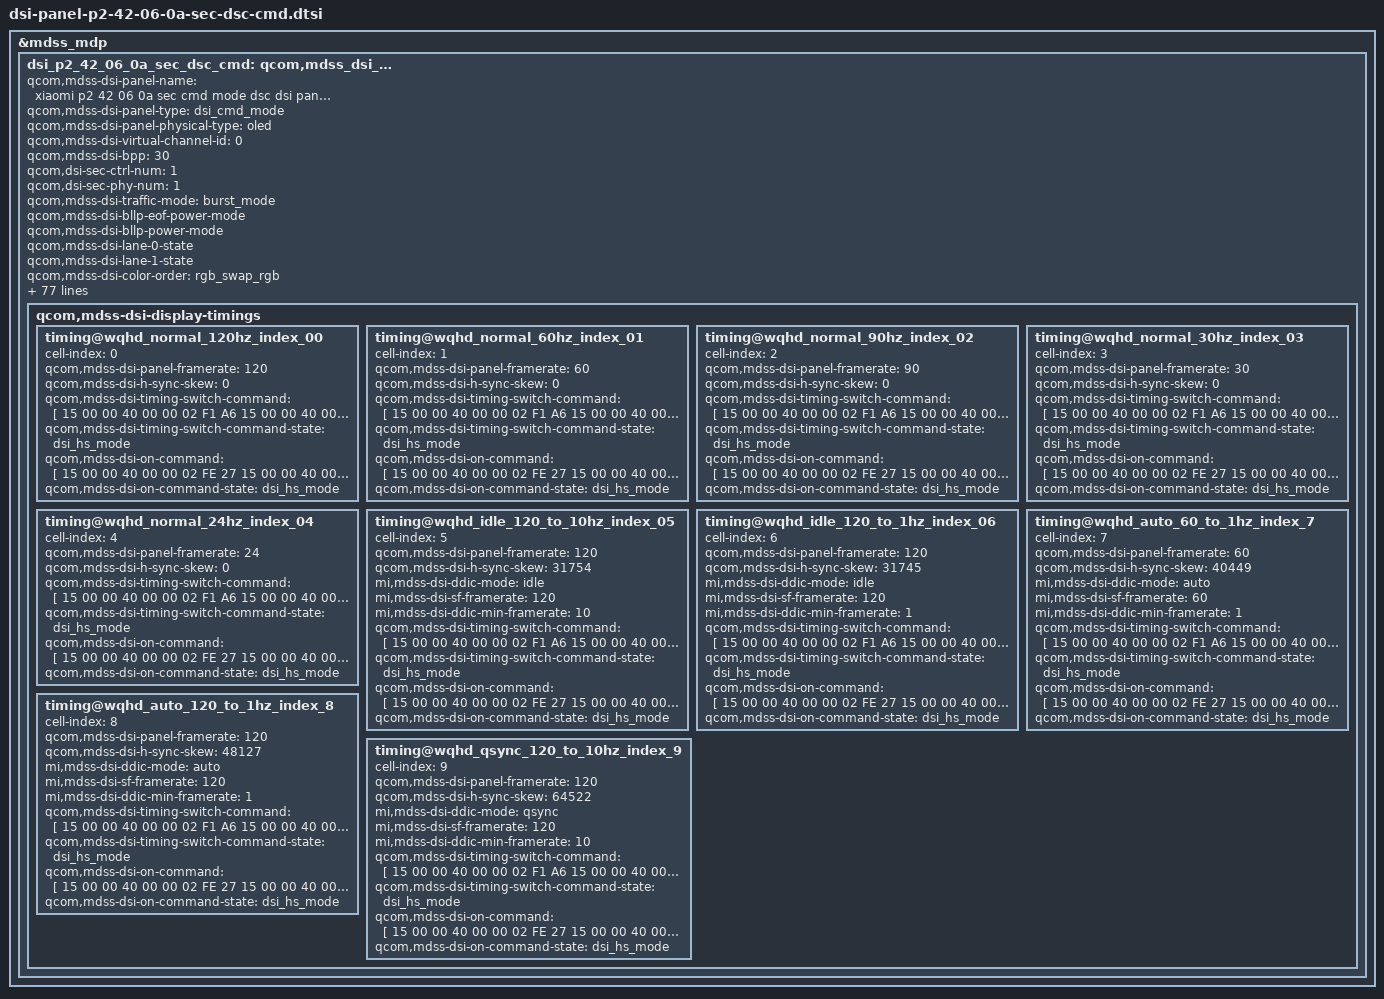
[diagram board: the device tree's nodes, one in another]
&mdss_mdp {
	dsi_p2_42_06_0a_sec_dsc_cmd: qcom,mdss_dsi_p2_42_06_0a_sec_dsc_cmd {
		qcom,mdss-dsi-panel-name = "xiaomi p2 42 06 0a sec cmd mode dsc dsi panel";
		qcom,mdss-dsi-panel-type = "dsi_cmd_mode";
		qcom,mdss-dsi-panel-physical-type = "oled";
		qcom,mdss-dsi-virtual-channel-id = <0>;
		qcom,mdss-dsi-bpp = <30>;
		qcom,dsi-sec-ctrl-num = <1>;
		qcom,dsi-sec-phy-num = <1>;
		qcom,mdss-dsi-traffic-mode = "burst_mode";
		qcom,mdss-dsi-bllp-eof-power-mode;
		qcom,mdss-dsi-bllp-power-mode;
		qcom,mdss-dsi-lane-0-state;
		qcom,mdss-dsi-lane-1-state;
		qcom,mdss-dsi-color-order = "rgb_swap_rgb";
		qcom,mdss-dsi-dma-trigger = "trigger_sw";
		qcom,mdss-dsi-mdp-trigger = "none";
		qcom,mdss-dsi-reset-sequence =<0 1>, <1 33>;
		qcom,mdss-pan-physical-width-dimension = <378>;
		qcom,mdss-pan-physical-height-dimension = <619>;
		qcom,mdss-dsi-te-pin-select = <1>;
		qcom,mdss-dsi-wr-mem-start = <0x2c>;
		qcom,mdss-dsi-wr-mem-continue = <0x3c>;
		qcom,mdss-dsi-te-dcs-command = <1>;
		qcom,mdss-dsi-tx-eot-append;
		//qcom,mdss-dsi-lp11-init;
		qcom,mdss-dsi-bl-inverted-dbv;
		qcom,bl-update-flag = "delay_until_first_frame";
		qcom,mdss-dsi-panel-hdr-enabled;
		qcom,mdss-dsi-panel-hdr-color-primaries = <14500 15500 32000
			17000 15500 30000 8000 3000>;
		qcom,mdss-dsi-panel-peak-brightness = <32000000>;
		qcom,mdss-dsi-panel-blackness-level = <3230>;
		qcom,mdss-dsi-dma-schedule-line = <1>;
		qcom,mdss-dsi-dma-schedule-window = <50>;

		qcom,mdss-disable-cesta-hw-sleep;

		qcom,mdss-dsi-display-timings {
			timing@wqhd_normal_120hz_index_00 {
				#include "dsi-panel-p2-42-06-0a-sec-dsc-cmd-common.dtsi"
				cell-index = <0>;
				qcom,mdss-dsi-panel-framerate = <120>;
				qcom,mdss-dsi-h-sync-skew = <0>;
				qcom,mdss-dsi-timing-switch-command = [
					15 00 00 40 00 00 02 F1 A6
					15 00 00 40 00 00 02 FE 00
					15 00 00 40 00 00 02 8A 17 // auto 120 - 1
					15 00 00 40 00 00 02 FE 98
					15 00 00 40 00 00 02 E3 08
					15 00 00 40 00 00 02 CB 01
					15 00 00 40 00 00 02 FE 44
					15 00 00 40 00 00 02 77 E8
					15 00 00 40 00 00 02 FE 00
					15 00 00 00 00 00 02 FB AA
				];
				qcom,mdss-dsi-timing-switch-command-state = "dsi_hs_mode";
				qcom,mdss-dsi-on-command = [
					/* round corner */
					15 00 00 40 00 00 02 FE 27
					15 00 00 40 00 00 02 BF 01
					15 00 00 40 00 00 02 F6 01
					15 00 00 40 00 00 02 FE 27
					15 00 00 40 00 00 02 0F F2
					15 00 00 40 00 00 02 13 2C
					15 00 00 40 00 00 02 19 86
					15 00 00 40 00 00 02 1A 14
					15 00 00 40 00 00 02 1B 40
					15 00 00 40 00 00 02 26 63
					15 00 00 40 00 00 02 27 63
					15 00 00 40 00 00 02 29 64
					15 00 00 40 00 00 02 2A 78
					15 00 00 40 00 00 02 2F 00
					15 00 00 40 00 00 02 30 6F
					15 00 00 40 00 00 02 31 95
					15 00 00 40 00 00 02 32 00
					15 00 00 40 00 00 02 33 96
					15 00 00 40 00 00 02 34 78
					15 00 00 40 00 00 02 35 00
					15 00 00 40 00 00 02 36 04
					15 00 00 40 00 00 02 37 07
					15 00 00 40 00 00 02 38 95
					15 00 00 40 00 00 02 39 6F
					15 00 00 40 00 00 02 3A 00
					15 00 00 40 00 00 02 3B 96
					15 00 00 40 00 00 02 3F 78
					15 00 00 40 00 00 02 40 00
					15 00 00 40 00 00 02 41 04
					15 00 00 40 00 00 02 42 07
					15 00 00 40 00 00 02 77 86
					15 00 00 40 00 00 02 78 A0
					15 00 00 40 00 00 02 80 64
					15 00 00 40 00 00 02 81 64
					15 00 00 40 00 00 02 83 63
					15 00 00 40 00 00 02 90 86
					15 00 00 40 00 00 02 91 A0
					15 00 00 40 00 00 02 B6 00
					15 00 00 40 00 00 02 B7 44
					15 00 00 40 00 00 02 C1 24
					15 00 00 40 00 00 02 C3 24
					15 00 00 40 00 00 02 FE 28
					15 00 00 40 00 00 02 37 18
					15 00 00 40 00 00 02 58 18
					15 00 00 40 00 00 02 FE 90
					15 00 00 40 00 00 02 08 00
					15 00 00 00 00 00 02 09 00
					/* init code */
					15 00 00 40 00 00 02 FE D2
					15 00 00 40 00 00 02 97 00
					15 00 00 40 00 00 02 FE 00
					15 00 00 40 00 00 02 FA 01
					15 00 00 40 00 00 02 FE 00
					15 00 00 40 00 00 02 2F 04
					15 00 00 40 00 00 02 8A 10
					15 00 00 40 00 00 02 FE 00
					39 00 00 40 00 00 05 2A 00 00 02 53
					39 00 00 40 00 00 05 2B 00 00 03 CF
					15 00 00 40 00 00 02 35 00
					39 00 00 00 00 00 03 51 00 00
					/* frame skip */
					15 00 00 40 00 00 02 FE 44
					15 00 00 40 00 00 02 00 88
					15 00 00 40 00 00 02 AA 00
					15 00 00 40 00 00 02 01 08
					15 00 00 40 00 00 02 02 01
					15 00 00 40 00 00 02 03 01
					15 00 00 40 00 00 02 04 32
					15 00 00 40 00 00 02 05 01
					15 00 00 40 00 00 02 06 00
					15 00 00 40 00 00 02 07 00
					15 00 00 40 00 00 02 08 00
					15 00 00 40 00 00 02 09 00
					15 00 00 40 00 00 02 0A 00
					15 00 00 40 00 00 02 0B 00
					15 00 00 40 00 00 02 0C 00
					15 00 00 40 00 00 02 0D 11
					15 00 00 40 00 00 02 0E 11
					15 00 00 40 00 00 02 0F 11
					15 00 00 40 00 00 02 10 11
					15 00 00 40 00 00 02 15 01
					15 00 00 40 00 00 02 16 03
					15 00 00 40 00 00 02 17 00
					15 00 00 40 00 00 02 18 00
					15 00 00 40 00 00 02 19 00
					15 00 00 40 00 00 02 1A 00
					15 00 00 40 00 00 02 1B 00
					15 00 00 40 00 00 02 1C 00
					15 00 00 40 00 00 02 1D 11
					15 00 00 40 00 00 02 1E 11
					15 00 00 40 00 00 02 1F 11
					15 00 00 40 00 00 02 20 11
					15 00 00 40 00 00 02 25 01
					15 00 00 40 00 00 02 26 03
					15 00 00 40 00 00 02 27 0B
					15 00 00 40 00 00 02 28 0B
					15 00 00 40 00 00 02 29 00
					15 00 00 40 00 00 02 2A 00
					15 00 00 40 00 00 02 2B 00
					15 00 00 40 00 00 02 2D 00
					15 00 00 40 00 00 02 2F 11
					15 00 00 40 00 00 02 30 FF
					15 00 00 40 00 00 02 31 11
					15 00 00 40 00 00 02 32 11
					15 00 00 40 00 00 02 37 01
					15 00 00 40 00 00 02 38 03
					15 00 00 40 00 00 02 39 04
					15 00 00 40 00 00 02 3A 00
					15 00 00 40 00 00 02 3B 00
					15 00 00 40 00 00 02 3D 00
					15 00 00 40 00 00 02 3F 00
					15 00 00 40 00 00 02 40 00
					15 00 00 40 00 00 02 41 11
					15 00 00 40 00 00 02 42 11
					15 00 00 40 00 00 02 43 11
					15 00 00 40 00 00 02 44 11
					15 00 00 40 00 00 02 69 00
					15 00 00 40 00 00 02 6A 00
					15 00 00 40 00 00 02 6B 00
					15 00 00 40 00 00 02 6C 00
					15 00 00 40 00 00 02 6D 00
					15 00 00 40 00 00 02 6E 00
					15 00 00 40 00 00 02 6F 00
					15 00 00 40 00 00 02 70 00
					15 00 00 40 00 00 02 80 42
					15 00 00 40 00 00 02 81 03
					15 00 00 40 00 00 02 82 0B
					15 00 00 40 00 00 02 83 0B
					15 00 00 40 00 00 02 84 00
					15 00 00 40 00 00 02 85 00
					15 00 00 40 00 00 02 86 00
					15 00 00 40 00 00 02 87 00
					15 00 00 40 00 00 02 88 00
					15 00 00 40 00 00 02 89 00
					15 00 00 40 00 00 02 8A 00
					15 00 00 40 00 00 02 8B 1F
					15 00 00 40 00 00 02 8C F1
					15 00 00 40 00 00 02 8D 11
					15 00 00 40 00 00 02 8E 11
					15 00 00 40 00 00 02 49 00
					15 00 00 40 00 00 02 4A 00
					15 00 00 40 00 00 02 4B 04
					15 00 00 40 00 00 02 4C 00
					15 00 00 40 00 00 02 4D 00
					15 00 00 40 00 00 02 4E 01
					15 00 00 40 00 00 02 4F 03
					15 00 00 40 00 00 02 50 04
					15 00 00 40 00 00 02 51 0B
					15 00 00 40 00 00 02 52 77
					15 00 00 40 00 00 02 53 EF
					15 00 00 40 00 00 02 54 77
					15 00 00 40 00 00 02 55 77
					15 00 00 40 00 00 02 56 0B
					15 00 00 40 00 00 02 58 59
					15 00 00 40 00 00 02 59 00
					15 00 00 40 00 00 02 5A 00
					15 00 00 40 00 00 02 5B 00
					15 00 00 40 00 00 02 5C 00
					15 00 00 40 00 00 02 5D 00
					15 00 00 40 00 00 02 98 00
					15 00 00 40 00 00 02 99 00
					15 00 00 40 00 00 02 9A 00
					15 00 00 40 00 00 02 9B 00
					15 00 00 40 00 00 02 9C 00
					15 00 00 40 00 00 02 9D 00
					15 00 00 40 00 00 02 9E 00
					15 00 00 40 00 00 02 9F 00
					15 00 00 40 00 00 02 A0 00
					15 00 00 40 00 00 02 A2 00
					15 00 00 40 00 00 02 A3 00
					15 00 00 40 00 00 02 A4 00
					15 00 00 40 00 00 02 A5 00
					15 00 00 40 00 00 02 A6 00
					15 00 00 40 00 00 02 A7 00
					15 00 00 40 00 00 02 A9 00
					15 00 00 40 00 00 02 5E 00
					15 00 00 40 00 00 02 5F 01
					15 00 00 40 00 00 02 60 12
					15 00 00 40 00 00 02 61 32
					15 00 00 40 00 00 02 62 44
					15 00 00 40 00 00 02 63 40
					15 00 00 40 00 00 02 64 00
					15 00 00 40 00 00 02 65 00
					15 00 00 40 00 00 02 76 C0
					15 00 00 40 00 00 02 77 E8
					15 00 00 40 00 00 02 FE 43
					15 00 00 40 00 00 02 64 1B
					15 00 00 40 00 00 02 63 05
					15 00 00 40 00 00 02 66 06
					15 00 00 40 00 00 02 67 22
					15 00 00 40 00 00 02 68 22
					15 00 00 40 00 00 02 69 B3
					15 00 00 40 00 00 02 6A 33
					15 00 00 40 00 00 02 6B 0B
					15 00 00 40 00 00 02 6C 16
					15 00 00 40 00 00 02 6D 21
					15 00 00 40 00 00 02 6F 37
					15 00 00 40 00 00 02 70 42
					15 00 00 40 00 00 02 71 4D
					15 00 00 40 00 00 02 72 58
					15 00 00 40 00 00 02 73 0B
					15 00 00 40 00 00 02 74 16
					15 00 00 40 00 00 02 75 21
					15 00 00 40 00 00 02 76 2C
					15 00 00 40 00 00 02 77 37
					15 00 00 40 00 00 02 78 42
					15 00 00 40 00 00 02 79 4D
					15 00 00 40 00 00 02 7A 58
					15 00 00 40 00 00 02 7B 0B
					15 00 00 40 00 00 02 7C 16
					15 00 00 40 00 00 02 7D 21
					15 00 00 40 00 00 02 7E 2C
					15 00 00 40 00 00 02 7F 37
					15 00 00 40 00 00 02 80 42
					15 00 00 40 00 00 02 81 4D
					15 00 00 40 00 00 02 82 58
					15 00 00 40 00 00 02 83 0B
					15 00 00 40 00 00 02 84 16
					15 00 00 40 00 00 02 85 21
					15 00 00 40 00 00 02 86 2C
					15 00 00 40 00 00 02 87 37
					15 00 00 40 00 00 02 88 42
					15 00 00 40 00 00 02 89 4D
					15 00 00 40 00 00 02 8A 58
					15 00 00 40 00 00 02 8B 58
					15 00 00 40 00 00 02 8C 4D
					15 00 00 40 00 00 02 8D 42
					15 00 00 40 00 00 02 8E 37
					15 00 00 40 00 00 02 8F 2C
					15 00 00 40 00 00 02 90 21
					15 00 00 40 00 00 02 91 16
					15 00 00 40 00 00 02 92 0B
					15 00 00 40 00 00 02 93 58
					15 00 00 40 00 00 02 94 4D
					15 00 00 40 00 00 02 95 42
					15 00 00 40 00 00 02 96 37
					15 00 00 40 00 00 02 97 2C
					15 00 00 40 00 00 02 98 21
					15 00 00 40 00 00 02 99 16
					15 00 00 40 00 00 02 9A 0B
					15 00 00 40 00 00 02 9B 58
					15 00 00 40 00 00 02 9C 4D
					15 00 00 40 00 00 02 9D 42
					15 00 00 40 00 00 02 9E 37
					15 00 00 40 00 00 02 9F 2C
					15 00 00 40 00 00 02 A0 21
					15 00 00 40 00 00 02 A2 16
					15 00 00 40 00 00 02 A3 0B
					15 00 00 40 00 00 02 A4 58
					15 00 00 40 00 00 02 A5 4D
					15 00 00 40 00 00 02 A6 42
					15 00 00 40 00 00 02 A7 37
					15 00 00 40 00 00 02 A9 2C
					15 00 00 40 00 00 02 AA 21
					15 00 00 40 00 00 02 AB 16
					15 00 00 40 00 00 02 AC 0B
					15 00 00 40 00 00 02 AD 16
					15 00 00 40 00 00 02 AE 2C
					15 00 00 40 00 00 02 AF 16
					15 00 00 40 00 00 02 B0 2C
					15 00 00 40 00 00 02 B1 16
					15 00 00 40 00 00 02 B2 2C
					15 00 00 40 00 00 02 B3 16
					15 00 00 40 00 00 02 B4 2C
					15 00 00 40 00 00 02 B5 16
					15 00 00 40 00 00 02 B6 2C
					15 00 00 40 00 00 02 B7 16
					15 00 00 40 00 00 02 B8 2C
					15 00 00 40 00 00 02 B9 16
					15 00 00 40 00 00 02 BA 2C
					15 00 00 40 00 00 02 BB 16
					15 00 00 40 00 00 02 BC 2C
					15 00 00 40 00 00 02 BD 16
					15 00 00 40 00 00 02 BE 2C
					15 00 00 40 00 00 02 BF 16
					15 00 00 40 00 00 02 C0 2C
					15 00 00 40 00 00 02 C1 16
					15 00 00 40 00 00 02 C2 2C
					15 00 00 40 00 00 02 C3 16
					15 00 00 40 00 00 02 C4 2C
					15 00 00 40 00 00 02 C5 16
					15 00 00 40 00 00 02 C6 2C
					15 00 00 40 00 00 02 C7 16
					15 00 00 40 00 00 02 C8 2C
					15 00 00 40 00 00 02 C9 16
					15 00 00 40 00 00 02 CA 2C
					15 00 00 40 00 00 02 CB 16
					15 00 00 40 00 00 02 CC 2C
					15 00 00 40 00 00 02 CD 2C
					15 00 00 40 00 00 02 CE 16
					15 00 00 40 00 00 02 CF 2C
					15 00 00 40 00 00 02 D0 16
					15 00 00 40 00 00 02 D1 2C
					15 00 00 40 00 00 02 D2 16
					15 00 00 40 00 00 02 D3 2C
					15 00 00 40 00 00 02 D4 16
					15 00 00 40 00 00 02 D5 2C
					15 00 00 40 00 00 02 D6 16
					15 00 00 40 00 00 02 D7 2C
					15 00 00 40 00 00 02 D8 16
					15 00 00 40 00 00 02 D9 2C
					15 00 00 40 00 00 02 DA 16
					15 00 00 40 00 00 02 DB 2C
					15 00 00 40 00 00 02 DC 16
					15 00 00 40 00 00 02 DD 2C
					15 00 00 40 00 00 02 DE 16
					15 00 00 40 00 00 02 DF 2C
					15 00 00 40 00 00 02 E0 16
					15 00 00 40 00 00 02 E1 2C
					15 00 00 40 00 00 02 E2 16
					15 00 00 40 00 00 02 E3 2C
					15 00 00 40 00 00 02 E4 16
					15 00 00 40 00 00 02 E5 2C
					15 00 00 40 00 00 02 E6 16
					15 00 00 40 00 00 02 E7 2C
					15 00 00 40 00 00 02 E8 16
					15 00 00 40 00 00 02 E9 2C
					15 00 00 40 00 00 02 EA 16
					15 00 00 40 00 00 02 EB 2C
					15 00 00 40 00 00 02 EC 16
					15 00 00 40 00 00 02 FE 6A
					15 00 00 40 00 00 02 4E 00
					15 00 00 40 00 00 02 4F 00
					15 00 00 40 00 00 02 50 00
					15 00 00 40 00 00 02 51 00
					15 00 00 40 00 00 02 52 00
					15 00 00 40 00 00 02 53 00
					15 00 00 40 00 00 02 54 00
					15 00 00 40 00 00 02 55 00
					15 00 00 40 00 00 02 56 00
					15 00 00 40 00 00 02 58 00
					15 00 00 40 00 00 02 59 00
					15 00 00 40 00 00 02 5A 00
					15 00 00 40 00 00 02 5B 00
					15 00 00 40 00 00 02 5C 00
					15 00 00 40 00 00 02 5D 00
					15 00 00 40 00 00 02 5E 00
					15 00 00 40 00 00 02 FE 44
					15 00 00 40 00 00 02 78 3F
					15 00 00 40 00 00 02 79 E0
					15 00 00 40 00 00 02 66 00
					15 00 00 40 00 00 02 67 00
					15 00 00 40 00 00 02 FE 72
					15 00 00 40 00 00 02 F3 60
					15 00 00 40 00 00 02 33 01
					15 00 00 40 00 00 02 FE 98
					15 00 00 40 00 00 02 02 04
					15 00 00 00 00 00 02 03 EC
					//err flag setting
					15 00 00 40 00 00 02 FE D4
					15 00 00 40 00 00 02 40 03
					15 00 00 40 00 00 02 42 00
					15 00 00 40 00 00 02 FE 47
					15 00 00 40 00 00 02 80 26
					15 00 00 40 00 00 02 83 00
					15 00 00 40 00 00 02 FE 40
					15 00 00 40 00 00 02 DE A8
					15 00 00 40 00 00 02 FE A0
					15 00 00 40 00 00 02 06 04
					15 00 00 40 00 00 02 7C 15
					15 00 00 40 00 00 02 FE 42
					15 00 00 40 00 00 02 17 02
					15 00 00 40 00 00 02 FE A1
					15 00 00 40 00 00 02 74 72
					15 00 00 40 00 00 02 C3 FF
					15 00 00 40 00 00 02 C4 FF
					15 00 00 00 00 00 02 C5 7F
					// IC write
					15 00 00 40 00 00 02 FE 40
					15 00 00 40 00 00 02 92 70
					15 00 00 40 00 00 02 93 81
					15 00 00 40 00 00 02 FE 98
					15 00 00 40 00 00 02 7D 10
					15 00 00 40 00 00 02 C4 88
					15 00 00 40 00 00 02 C6 03
					15 00 00 40 00 00 02 C7 8F
					15 00 00 40 00 00 02 FE A1
					15 00 00 00 00 00 02 58 67
					// timing switch
					15 00 00 40 00 00 02 FE 00
					15 00 00 40 00 00 02 8A 17 // auto 120 - 1
					15 00 00 40 00 00 02 FE 98
					15 00 00 40 00 00 02 E3 08
					15 00 00 40 00 00 02 CB 01
					15 00 00 40 00 00 02 FE 44
					15 00 00 40 00 00 02 77 E8
					// vsync out for Psensor
					15 00 00 40 00 00 02 FE D0
					15 00 00 40 00 00 02 1C 09
					15 00 00 40 00 00 02 FE 98
					15 00 00 40 00 00 02 E0 07
					15 00 00 40 00 00 02 E1 07
					15 00 00 40 00 00 02 E2 07
					15 00 00 40 00 00 02 FE 61
					15 00 00 40 00 00 02 48 11
					15 00 00 40 00 00 02 FE 62
					15 00 00 40 00 00 02 48 8D
					15 00 00 40 00 00 02 49 00
					15 00 00 40 00 00 02 4A 00
					15 00 00 40 00 00 02 4B 14
					15 00 00 40 00 00 02 4C 40
					15 00 00 40 00 00 02 4D 00
					15 00 00 40 00 00 02 4E 01
					15 00 00 00 00 00 02 4F 01
					// PPS lock
					15 00 00 00 00 00 02 FE FD
					15 00 00 00 00 00 02 90 01
					// PSCAN_CK1
					15 00 00 40 00 00 02 FE 62
					15 00 00 00 00 00 02 00 C7
					// Sleep Out
					15 00 00 00 00 00 02 FE 00
					05 00 00 00 78 00 01 11
					05 00 00 00 00 00 01 29
				];
				qcom,mdss-dsi-on-command-state = "dsi_hs_mode";
			};
			timing@wqhd_normal_60hz_index_01 {
				#include "dsi-panel-p2-42-06-0a-sec-dsc-cmd-common.dtsi"
				cell-index = <1>;
				qcom,mdss-dsi-panel-framerate = <60>;
				qcom,mdss-dsi-h-sync-skew = <0>;
				qcom,mdss-dsi-timing-switch-command = [
					15 00 00 40 00 00 02 F1 A6
					15 00 00 40 00 00 02 FE 00
					15 00 00 40 00 00 02 8A 11 // fix 60
					15 00 00 40 00 00 02 FE 98
					15 00 00 40 00 00 02 E3 04
					15 00 00 40 00 00 02 CB 01
					15 00 00 40 00 00 02 FE 44
					15 00 00 40 00 00 02 77 48
					15 00 00 40 00 00 02 FE 00
					15 00 00 00 00 00 02 FB AA
				];
				qcom,mdss-dsi-timing-switch-command-state = "dsi_hs_mode";
				qcom,mdss-dsi-on-command = [
					/* round corner */
					15 00 00 40 00 00 02 FE 27
					15 00 00 40 00 00 02 BF 01
					15 00 00 40 00 00 02 F6 01
					15 00 00 40 00 00 02 FE 27
					15 00 00 40 00 00 02 0F F2
					15 00 00 40 00 00 02 13 2C
					15 00 00 40 00 00 02 19 86
					15 00 00 40 00 00 02 1A 14
					15 00 00 40 00 00 02 1B 40
					15 00 00 40 00 00 02 26 63
					15 00 00 40 00 00 02 27 63
					15 00 00 40 00 00 02 29 64
					15 00 00 40 00 00 02 2A 78
					15 00 00 40 00 00 02 2F 00
					15 00 00 40 00 00 02 30 6F
					15 00 00 40 00 00 02 31 95
					15 00 00 40 00 00 02 32 00
					15 00 00 40 00 00 02 33 96
					15 00 00 40 00 00 02 34 78
					15 00 00 40 00 00 02 35 00
					15 00 00 40 00 00 02 36 04
					15 00 00 40 00 00 02 37 07
					15 00 00 40 00 00 02 38 95
					15 00 00 40 00 00 02 39 6F
					15 00 00 40 00 00 02 3A 00
					15 00 00 40 00 00 02 3B 96
					15 00 00 40 00 00 02 3F 78
					15 00 00 40 00 00 02 40 00
					15 00 00 40 00 00 02 41 04
					15 00 00 40 00 00 02 42 07
					15 00 00 40 00 00 02 77 86
					15 00 00 40 00 00 02 78 A0
					15 00 00 40 00 00 02 80 64
					15 00 00 40 00 00 02 81 64
					15 00 00 40 00 00 02 83 63
					15 00 00 40 00 00 02 90 86
					15 00 00 40 00 00 02 91 A0
					15 00 00 40 00 00 02 B6 00
					15 00 00 40 00 00 02 B7 44
					15 00 00 40 00 00 02 C1 24
					15 00 00 40 00 00 02 C3 24
					15 00 00 40 00 00 02 FE 28
					15 00 00 40 00 00 02 37 18
					15 00 00 40 00 00 02 58 18
					15 00 00 40 00 00 02 FE 90
					15 00 00 40 00 00 02 08 00
					15 00 00 00 00 00 02 09 00
					/* init code */
					15 00 00 40 00 00 02 FE D2
					15 00 00 40 00 00 02 97 00
					15 00 00 40 00 00 02 FE 00
					15 00 00 40 00 00 02 FA 01
					15 00 00 40 00 00 02 FE 00
					15 00 00 40 00 00 02 2F 04
					15 00 00 40 00 00 02 8A 10
					15 00 00 40 00 00 02 FE 00
					39 00 00 40 00 00 05 2A 00 00 02 53
					39 00 00 40 00 00 05 2B 00 00 03 CF
					15 00 00 40 00 00 02 35 00
					39 00 00 00 00 00 03 51 00 00
					/* frame skip */
					15 00 00 40 00 00 02 FE 44
					15 00 00 40 00 00 02 00 88
					15 00 00 40 00 00 02 AA 00
					15 00 00 40 00 00 02 01 08
					15 00 00 40 00 00 02 02 01
					15 00 00 40 00 00 02 03 01
					15 00 00 40 00 00 02 04 32
					15 00 00 40 00 00 02 05 01
					15 00 00 40 00 00 02 06 00
					15 00 00 40 00 00 02 07 00
					15 00 00 40 00 00 02 08 00
					15 00 00 40 00 00 02 09 00
					15 00 00 40 00 00 02 0A 00
					15 00 00 40 00 00 02 0B 00
					15 00 00 40 00 00 02 0C 00
					15 00 00 40 00 00 02 0D 11
					15 00 00 40 00 00 02 0E 11
					15 00 00 40 00 00 02 0F 11
					15 00 00 40 00 00 02 10 11
					15 00 00 40 00 00 02 15 01
					15 00 00 40 00 00 02 16 03
					15 00 00 40 00 00 02 17 00
					15 00 00 40 00 00 02 18 00
					15 00 00 40 00 00 02 19 00
					15 00 00 40 00 00 02 1A 00
					15 00 00 40 00 00 02 1B 00
					15 00 00 40 00 00 02 1C 00
					15 00 00 40 00 00 02 1D 11
					15 00 00 40 00 00 02 1E 11
					15 00 00 40 00 00 02 1F 11
					15 00 00 40 00 00 02 20 11
					15 00 00 40 00 00 02 25 01
					15 00 00 40 00 00 02 26 03
					15 00 00 40 00 00 02 27 0B
					15 00 00 40 00 00 02 28 0B
					15 00 00 40 00 00 02 29 00
					15 00 00 40 00 00 02 2A 00
					15 00 00 40 00 00 02 2B 00
					15 00 00 40 00 00 02 2D 00
					15 00 00 40 00 00 02 2F 11
					15 00 00 40 00 00 02 30 FF
					15 00 00 40 00 00 02 31 11
					15 00 00 40 00 00 02 32 11
					15 00 00 40 00 00 02 37 01
					15 00 00 40 00 00 02 38 03
					15 00 00 40 00 00 02 39 04
					15 00 00 40 00 00 02 3A 00
					15 00 00 40 00 00 02 3B 00
					15 00 00 40 00 00 02 3D 00
					15 00 00 40 00 00 02 3F 00
					15 00 00 40 00 00 02 40 00
					15 00 00 40 00 00 02 41 11
					15 00 00 40 00 00 02 42 11
					15 00 00 40 00 00 02 43 11
					15 00 00 40 00 00 02 44 11
					15 00 00 40 00 00 02 69 00
					15 00 00 40 00 00 02 6A 00
					15 00 00 40 00 00 02 6B 00
					15 00 00 40 00 00 02 6C 00
					15 00 00 40 00 00 02 6D 00
					15 00 00 40 00 00 02 6E 00
					15 00 00 40 00 00 02 6F 00
					15 00 00 40 00 00 02 70 00
					15 00 00 40 00 00 02 80 42
					15 00 00 40 00 00 02 81 03
					15 00 00 40 00 00 02 82 0B
					15 00 00 40 00 00 02 83 0B
					15 00 00 40 00 00 02 84 00
					15 00 00 40 00 00 02 85 00
					15 00 00 40 00 00 02 86 00
					15 00 00 40 00 00 02 87 00
					15 00 00 40 00 00 02 88 00
					15 00 00 40 00 00 02 89 00
					15 00 00 40 00 00 02 8A 00
					15 00 00 40 00 00 02 8B 1F
					15 00 00 40 00 00 02 8C F1
					15 00 00 40 00 00 02 8D 11
					15 00 00 40 00 00 02 8E 11
					15 00 00 40 00 00 02 49 00
					15 00 00 40 00 00 02 4A 00
					15 00 00 40 00 00 02 4B 04
					15 00 00 40 00 00 02 4C 00
					15 00 00 40 00 00 02 4D 00
					15 00 00 40 00 00 02 4E 01
					15 00 00 40 00 00 02 4F 03
					15 00 00 40 00 00 02 50 04
					15 00 00 40 00 00 02 51 0B
					15 00 00 40 00 00 02 52 77
					15 00 00 40 00 00 02 53 EF
					15 00 00 40 00 00 02 54 77
					15 00 00 40 00 00 02 55 77
					15 00 00 40 00 00 02 56 0B
					15 00 00 40 00 00 02 58 59
					15 00 00 40 00 00 02 59 00
					15 00 00 40 00 00 02 5A 00
					15 00 00 40 00 00 02 5B 00
					15 00 00 40 00 00 02 5C 00
					15 00 00 40 00 00 02 5D 00
					15 00 00 40 00 00 02 98 00
					15 00 00 40 00 00 02 99 00
					15 00 00 40 00 00 02 9A 00
					15 00 00 40 00 00 02 9B 00
					15 00 00 40 00 00 02 9C 00
					15 00 00 40 00 00 02 9D 00
					15 00 00 40 00 00 02 9E 00
					15 00 00 40 00 00 02 9F 00
					15 00 00 40 00 00 02 A0 00
					15 00 00 40 00 00 02 A2 00
					15 00 00 40 00 00 02 A3 00
					15 00 00 40 00 00 02 A4 00
					15 00 00 40 00 00 02 A5 00
					15 00 00 40 00 00 02 A6 00
					15 00 00 40 00 00 02 A7 00
					15 00 00 40 00 00 02 A9 00
					15 00 00 40 00 00 02 5E 00
					15 00 00 40 00 00 02 5F 01
					15 00 00 40 00 00 02 60 12
					15 00 00 40 00 00 02 61 32
					15 00 00 40 00 00 02 62 44
					15 00 00 40 00 00 02 63 40
					15 00 00 40 00 00 02 64 00
					15 00 00 40 00 00 02 65 00
					15 00 00 40 00 00 02 76 C0
					15 00 00 40 00 00 02 77 E8
					15 00 00 40 00 00 02 FE 43
					15 00 00 40 00 00 02 64 1B
					15 00 00 40 00 00 02 63 05
					15 00 00 40 00 00 02 66 06
					15 00 00 40 00 00 02 67 22
					15 00 00 40 00 00 02 68 22
					15 00 00 40 00 00 02 69 B3
					15 00 00 40 00 00 02 6A 33
					15 00 00 40 00 00 02 6B 0B
					15 00 00 40 00 00 02 6C 16
					15 00 00 40 00 00 02 6D 21
					15 00 00 40 00 00 02 6F 37
					15 00 00 40 00 00 02 70 42
					15 00 00 40 00 00 02 71 4D
					15 00 00 40 00 00 02 72 58
					15 00 00 40 00 00 02 73 0B
					15 00 00 40 00 00 02 74 16
					15 00 00 40 00 00 02 75 21
					15 00 00 40 00 00 02 76 2C
					15 00 00 40 00 00 02 77 37
					15 00 00 40 00 00 02 78 42
					15 00 00 40 00 00 02 79 4D
					15 00 00 40 00 00 02 7A 58
					15 00 00 40 00 00 02 7B 0B
					15 00 00 40 00 00 02 7C 16
					15 00 00 40 00 00 02 7D 21
					15 00 00 40 00 00 02 7E 2C
					15 00 00 40 00 00 02 7F 37
					15 00 00 40 00 00 02 80 42
					15 00 00 40 00 00 02 81 4D
					15 00 00 40 00 00 02 82 58
					15 00 00 40 00 00 02 83 0B
					15 00 00 40 00 00 02 84 16
					15 00 00 40 00 00 02 85 21
					15 00 00 40 00 00 02 86 2C
					15 00 00 40 00 00 02 87 37
					15 00 00 40 00 00 02 88 42
					15 00 00 40 00 00 02 89 4D
					15 00 00 40 00 00 02 8A 58
					15 00 00 40 00 00 02 8B 58
					15 00 00 40 00 00 02 8C 4D
					15 00 00 40 00 00 02 8D 42
					15 00 00 40 00 00 02 8E 37
					15 00 00 40 00 00 02 8F 2C
					15 00 00 40 00 00 02 90 21
					15 00 00 40 00 00 02 91 16
					15 00 00 40 00 00 02 92 0B
					15 00 00 40 00 00 02 93 58
					15 00 00 40 00 00 02 94 4D
					15 00 00 40 00 00 02 95 42
					15 00 00 40 00 00 02 96 37
					15 00 00 40 00 00 02 97 2C
					15 00 00 40 00 00 02 98 21
					15 00 00 40 00 00 02 99 16
					15 00 00 40 00 00 02 9A 0B
					15 00 00 40 00 00 02 9B 58
					15 00 00 40 00 00 02 9C 4D
					15 00 00 40 00 00 02 9D 42
					15 00 00 40 00 00 02 9E 37
					15 00 00 40 00 00 02 9F 2C
					15 00 00 40 00 00 02 A0 21
					15 00 00 40 00 00 02 A2 16
					15 00 00 40 00 00 02 A3 0B
					15 00 00 40 00 00 02 A4 58
					15 00 00 40 00 00 02 A5 4D
					15 00 00 40 00 00 02 A6 42
					15 00 00 40 00 00 02 A7 37
					15 00 00 40 00 00 02 A9 2C
					15 00 00 40 00 00 02 AA 21
					15 00 00 40 00 00 02 AB 16
					15 00 00 40 00 00 02 AC 0B
					15 00 00 40 00 00 02 AD 16
					15 00 00 40 00 00 02 AE 2C
					15 00 00 40 00 00 02 AF 16
					15 00 00 40 00 00 02 B0 2C
					15 00 00 40 00 00 02 B1 16
					15 00 00 40 00 00 02 B2 2C
					15 00 00 40 00 00 02 B3 16
					15 00 00 40 00 00 02 B4 2C
					15 00 00 40 00 00 02 B5 16
					15 00 00 40 00 00 02 B6 2C
					15 00 00 40 00 00 02 B7 16
					15 00 00 40 00 00 02 B8 2C
					15 00 00 40 00 00 02 B9 16
					15 00 00 40 00 00 02 BA 2C
					15 00 00 40 00 00 02 BB 16
					15 00 00 40 00 00 02 BC 2C
					15 00 00 40 00 00 02 BD 16
					15 00 00 40 00 00 02 BE 2C
					15 00 00 40 00 00 02 BF 16
					15 00 00 40 00 00 02 C0 2C
					15 00 00 40 00 00 02 C1 16
					15 00 00 40 00 00 02 C2 2C
					15 00 00 40 00 00 02 C3 16
					15 00 00 40 00 00 02 C4 2C
					15 00 00 40 00 00 02 C5 16
					15 00 00 40 00 00 02 C6 2C
					15 00 00 40 00 00 02 C7 16
					15 00 00 40 00 00 02 C8 2C
					15 00 00 40 00 00 02 C9 16
					15 00 00 40 00 00 02 CA 2C
					15 00 00 40 00 00 02 CB 16
					15 00 00 40 00 00 02 CC 2C
					15 00 00 40 00 00 02 CD 2C
					15 00 00 40 00 00 02 CE 16
					15 00 00 40 00 00 02 CF 2C
					15 00 00 40 00 00 02 D0 16
					15 00 00 40 00 00 02 D1 2C
					15 00 00 40 00 00 02 D2 16
					15 00 00 40 00 00 02 D3 2C
					15 00 00 40 00 00 02 D4 16
					15 00 00 40 00 00 02 D5 2C
					15 00 00 40 00 00 02 D6 16
					15 00 00 40 00 00 02 D7 2C
					15 00 00 40 00 00 02 D8 16
					15 00 00 40 00 00 02 D9 2C
					15 00 00 40 00 00 02 DA 16
					15 00 00 40 00 00 02 DB 2C
					15 00 00 40 00 00 02 DC 16
					15 00 00 40 00 00 02 DD 2C
					15 00 00 40 00 00 02 DE 16
					15 00 00 40 00 00 02 DF 2C
					15 00 00 40 00 00 02 E0 16
					15 00 00 40 00 00 02 E1 2C
					15 00 00 40 00 00 02 E2 16
					15 00 00 40 00 00 02 E3 2C
					15 00 00 40 00 00 02 E4 16
					15 00 00 40 00 00 02 E5 2C
					15 00 00 40 00 00 02 E6 16
					15 00 00 40 00 00 02 E7 2C
					15 00 00 40 00 00 02 E8 16
					15 00 00 40 00 00 02 E9 2C
					15 00 00 40 00 00 02 EA 16
					15 00 00 40 00 00 02 EB 2C
					15 00 00 40 00 00 02 EC 16
					15 00 00 40 00 00 02 FE 6A
					15 00 00 40 00 00 02 4E 00
					15 00 00 40 00 00 02 4F 00
					15 00 00 40 00 00 02 50 00
					15 00 00 40 00 00 02 51 00
					15 00 00 40 00 00 02 52 00
					15 00 00 40 00 00 02 53 00
					15 00 00 40 00 00 02 54 00
					15 00 00 40 00 00 02 55 00
					15 00 00 40 00 00 02 56 00
					15 00 00 40 00 00 02 58 00
					15 00 00 40 00 00 02 59 00
					15 00 00 40 00 00 02 5A 00
					15 00 00 40 00 00 02 5B 00
					15 00 00 40 00 00 02 5C 00
					15 00 00 40 00 00 02 5D 00
					15 00 00 40 00 00 02 5E 00
					15 00 00 40 00 00 02 FE 44
					15 00 00 40 00 00 02 78 3F
					15 00 00 40 00 00 02 79 E0
					15 00 00 40 00 00 02 66 00
					15 00 00 40 00 00 02 67 00
					15 00 00 40 00 00 02 FE 72
					15 00 00 40 00 00 02 F3 60
					15 00 00 40 00 00 02 33 01
					15 00 00 40 00 00 02 FE 98
					15 00 00 40 00 00 02 02 04
					15 00 00 00 00 00 02 03 EC
					//err flag setting
					15 00 00 40 00 00 02 FE D4
					15 00 00 40 00 00 02 40 03
					15 00 00 40 00 00 02 42 00
					15 00 00 40 00 00 02 FE 47
					15 00 00 40 00 00 02 80 26
					15 00 00 40 00 00 02 83 00
					15 00 00 40 00 00 02 FE 40
					15 00 00 40 00 00 02 DE A8
					15 00 00 40 00 00 02 FE A0
					15 00 00 40 00 00 02 06 04
					15 00 00 40 00 00 02 7C 15
					15 00 00 40 00 00 02 FE 42
					15 00 00 40 00 00 02 17 02
					15 00 00 40 00 00 02 FE A1
					15 00 00 40 00 00 02 74 72
					15 00 00 40 00 00 02 C3 FF
					15 00 00 40 00 00 02 C4 FF
					15 00 00 00 00 00 02 C5 7F
					// IC write
					15 00 00 40 00 00 02 FE 40
					15 00 00 40 00 00 02 92 70
					15 00 00 40 00 00 02 93 81
					15 00 00 40 00 00 02 FE 98
					15 00 00 40 00 00 02 7D 10
					15 00 00 40 00 00 02 C4 88
					15 00 00 40 00 00 02 C6 03
					15 00 00 40 00 00 02 C7 8F
					15 00 00 40 00 00 02 FE A1
					15 00 00 00 00 00 02 58 67
					// timing switch
					15 00 00 40 00 00 02 FE 00
					15 00 00 40 00 00 02 8A 11 // fix 60
					15 00 00 40 00 00 02 FE 98
					15 00 00 40 00 00 02 E3 04
					15 00 00 40 00 00 02 CB 01
					15 00 00 40 00 00 02 FE 44
					15 00 00 40 00 00 02 77 48
					// vsync out for Psensor
					15 00 00 40 00 00 02 FE D0
					15 00 00 40 00 00 02 1C 09
					15 00 00 40 00 00 02 FE 98
					15 00 00 40 00 00 02 E0 07
					15 00 00 40 00 00 02 E1 07
					15 00 00 40 00 00 02 E2 07
					15 00 00 40 00 00 02 FE 61
					15 00 00 40 00 00 02 48 11
					15 00 00 40 00 00 02 FE 62
					15 00 00 40 00 00 02 48 8D
					15 00 00 40 00 00 02 49 00
					15 00 00 40 00 00 02 4A 00
					15 00 00 40 00 00 02 4B 14
					15 00 00 40 00 00 02 4C 40
					15 00 00 40 00 00 02 4D 00
					15 00 00 40 00 00 02 4E 01
					15 00 00 00 00 00 02 4F 01
					// PPS lock
					15 00 00 00 00 00 02 FE FD
					15 00 00 00 00 00 02 90 01
					// PSCAN_CK1
					15 00 00 40 00 00 02 FE 62
					15 00 00 00 00 00 02 00 C7
					// Sleep Out
					15 00 00 00 00 00 02 FE 00
					05 00 00 00 78 00 01 11
					05 00 00 00 00 00 01 29
				];
				qcom,mdss-dsi-on-command-state = "dsi_hs_mode";
			};
			timing@wqhd_normal_90hz_index_02 {
				#include "dsi-panel-p2-42-06-0a-sec-dsc-cmd-common.dtsi"
				cell-index = <2>;
				qcom,mdss-dsi-panel-framerate = <90>;
				qcom,mdss-dsi-h-sync-skew = <0>;
				qcom,mdss-dsi-timing-switch-command = [
					15 00 00 40 00 00 02 F1 A6
					15 00 00 40 00 00 02 FE 00
					15 00 00 40 00 00 02 8A 1A // auto 90
					15 00 00 40 00 00 02 FE 98
					15 00 00 40 00 00 02 E3 08
					15 00 00 40 00 00 02 CB 01
					15 00 00 40 00 00 02 FE 44
					15 00 00 40 00 00 02 77 E8
					15 00 00 40 00 00 02 81 02
					15 00 00 40 00 00 02 82 08
					15 00 00 40 00 00 02 83 08
					15 00 00 40 00 00 02 FE 00
					15 00 00 00 00 00 02 FB AA
				];
				qcom,mdss-dsi-timing-switch-command-state = "dsi_hs_mode";
				qcom,mdss-dsi-on-command = [
					/* round corner */
					15 00 00 40 00 00 02 FE 27
					15 00 00 40 00 00 02 BF 01
					15 00 00 40 00 00 02 F6 01
					15 00 00 40 00 00 02 FE 27
					15 00 00 40 00 00 02 0F F2
					15 00 00 40 00 00 02 13 2C
					15 00 00 40 00 00 02 19 86
					15 00 00 40 00 00 02 1A 14
					15 00 00 40 00 00 02 1B 40
					15 00 00 40 00 00 02 26 63
					15 00 00 40 00 00 02 27 63
					15 00 00 40 00 00 02 29 64
					15 00 00 40 00 00 02 2A 78
					15 00 00 40 00 00 02 2F 00
					15 00 00 40 00 00 02 30 6F
					15 00 00 40 00 00 02 31 95
					15 00 00 40 00 00 02 32 00
					15 00 00 40 00 00 02 33 96
					15 00 00 40 00 00 02 34 78
					15 00 00 40 00 00 02 35 00
					15 00 00 40 00 00 02 36 04
					15 00 00 40 00 00 02 37 07
					15 00 00 40 00 00 02 38 95
					15 00 00 40 00 00 02 39 6F
					15 00 00 40 00 00 02 3A 00
					15 00 00 40 00 00 02 3B 96
					15 00 00 40 00 00 02 3F 78
					15 00 00 40 00 00 02 40 00
					15 00 00 40 00 00 02 41 04
					15 00 00 40 00 00 02 42 07
					15 00 00 40 00 00 02 77 86
					15 00 00 40 00 00 02 78 A0
					15 00 00 40 00 00 02 80 64
					15 00 00 40 00 00 02 81 64
					15 00 00 40 00 00 02 83 63
					15 00 00 40 00 00 02 90 86
					15 00 00 40 00 00 02 91 A0
					15 00 00 40 00 00 02 B6 00
					15 00 00 40 00 00 02 B7 44
					15 00 00 40 00 00 02 C1 24
					15 00 00 40 00 00 02 C3 24
					15 00 00 40 00 00 02 FE 28
					15 00 00 40 00 00 02 37 18
					15 00 00 40 00 00 02 58 18
					15 00 00 40 00 00 02 FE 90
					15 00 00 40 00 00 02 08 00
					15 00 00 00 00 00 02 09 00
					/* init code */
					15 00 00 40 00 00 02 FE D2
					15 00 00 40 00 00 02 97 00
					15 00 00 40 00 00 02 FE 00
					15 00 00 40 00 00 02 FA 01
					15 00 00 40 00 00 02 FE 00
					15 00 00 40 00 00 02 2F 04
					15 00 00 40 00 00 02 8A 10
					15 00 00 40 00 00 02 FE 00
					39 00 00 40 00 00 05 2A 00 00 02 53
					39 00 00 40 00 00 05 2B 00 00 03 CF
					15 00 00 40 00 00 02 35 00
					39 00 00 00 00 00 03 51 00 00
					/* frame skip */
					15 00 00 40 00 00 02 FE 44
					15 00 00 40 00 00 02 00 88
					15 00 00 40 00 00 02 AA 00
					15 00 00 40 00 00 02 01 08
					15 00 00 40 00 00 02 02 01
					15 00 00 40 00 00 02 03 01
					15 00 00 40 00 00 02 04 32
					15 00 00 40 00 00 02 05 01
					15 00 00 40 00 00 02 06 00
					15 00 00 40 00 00 02 07 00
					15 00 00 40 00 00 02 08 00
					15 00 00 40 00 00 02 09 00
					15 00 00 40 00 00 02 0A 00
					15 00 00 40 00 00 02 0B 00
					15 00 00 40 00 00 02 0C 00
					15 00 00 40 00 00 02 0D 11
					15 00 00 40 00 00 02 0E 11
					15 00 00 40 00 00 02 0F 11
					15 00 00 40 00 00 02 10 11
					15 00 00 40 00 00 02 15 01
					15 00 00 40 00 00 02 16 03
					15 00 00 40 00 00 02 17 00
					15 00 00 40 00 00 02 18 00
					15 00 00 40 00 00 02 19 00
					15 00 00 40 00 00 02 1A 00
					15 00 00 40 00 00 02 1B 00
					15 00 00 40 00 00 02 1C 00
					15 00 00 40 00 00 02 1D 11
					15 00 00 40 00 00 02 1E 11
					15 00 00 40 00 00 02 1F 11
					15 00 00 40 00 00 02 20 11
					15 00 00 40 00 00 02 25 01
					15 00 00 40 00 00 02 26 03
					15 00 00 40 00 00 02 27 0B
					15 00 00 40 00 00 02 28 0B
					15 00 00 40 00 00 02 29 00
					15 00 00 40 00 00 02 2A 00
					15 00 00 40 00 00 02 2B 00
					15 00 00 40 00 00 02 2D 00
					15 00 00 40 00 00 02 2F 11
					15 00 00 40 00 00 02 30 FF
					15 00 00 40 00 00 02 31 11
					15 00 00 40 00 00 02 32 11
					15 00 00 40 00 00 02 37 01
					15 00 00 40 00 00 02 38 03
					15 00 00 40 00 00 02 39 04
					15 00 00 40 00 00 02 3A 00
					15 00 00 40 00 00 02 3B 00
					15 00 00 40 00 00 02 3D 00
					15 00 00 40 00 00 02 3F 00
					15 00 00 40 00 00 02 40 00
					15 00 00 40 00 00 02 41 11
					15 00 00 40 00 00 02 42 11
					15 00 00 40 00 00 02 43 11
					15 00 00 40 00 00 02 44 11
					15 00 00 40 00 00 02 69 00
					15 00 00 40 00 00 02 6A 00
					15 00 00 40 00 00 02 6B 00
					15 00 00 40 00 00 02 6C 00
					15 00 00 40 00 00 02 6D 00
					15 00 00 40 00 00 02 6E 00
					15 00 00 40 00 00 02 6F 00
					15 00 00 40 00 00 02 70 00
					15 00 00 40 00 00 02 80 42
					15 00 00 40 00 00 02 81 03
					15 00 00 40 00 00 02 82 0B
					15 00 00 40 00 00 02 83 0B
					15 00 00 40 00 00 02 84 00
					15 00 00 40 00 00 02 85 00
					15 00 00 40 00 00 02 86 00
					15 00 00 40 00 00 02 87 00
					15 00 00 40 00 00 02 88 00
					15 00 00 40 00 00 02 89 00
					15 00 00 40 00 00 02 8A 00
					15 00 00 40 00 00 02 8B 1F
					15 00 00 40 00 00 02 8C F1
					15 00 00 40 00 00 02 8D 11
					15 00 00 40 00 00 02 8E 11
					15 00 00 40 00 00 02 49 00
					15 00 00 40 00 00 02 4A 00
					15 00 00 40 00 00 02 4B 04
					15 00 00 40 00 00 02 4C 00
					15 00 00 40 00 00 02 4D 00
					15 00 00 40 00 00 02 4E 01
					15 00 00 40 00 00 02 4F 03
					15 00 00 40 00 00 02 50 04
					15 00 00 40 00 00 02 51 0B
					15 00 00 40 00 00 02 52 77
					15 00 00 40 00 00 02 53 EF
					15 00 00 40 00 00 02 54 77
					15 00 00 40 00 00 02 55 77
					15 00 00 40 00 00 02 56 0B
					15 00 00 40 00 00 02 58 59
					15 00 00 40 00 00 02 59 00
					15 00 00 40 00 00 02 5A 00
					15 00 00 40 00 00 02 5B 00
					15 00 00 40 00 00 02 5C 00
					15 00 00 40 00 00 02 5D 00
					15 00 00 40 00 00 02 98 00
					15 00 00 40 00 00 02 99 00
					15 00 00 40 00 00 02 9A 00
					15 00 00 40 00 00 02 9B 00
					15 00 00 40 00 00 02 9C 00
					15 00 00 40 00 00 02 9D 00
					15 00 00 40 00 00 02 9E 00
					15 00 00 40 00 00 02 9F 00
					15 00 00 40 00 00 02 A0 00
					15 00 00 40 00 00 02 A2 00
					15 00 00 40 00 00 02 A3 00
					15 00 00 40 00 00 02 A4 00
					15 00 00 40 00 00 02 A5 00
					15 00 00 40 00 00 02 A6 00
					15 00 00 40 00 00 02 A7 00
					15 00 00 40 00 00 02 A9 00
					15 00 00 40 00 00 02 5E 00
					15 00 00 40 00 00 02 5F 01
					15 00 00 40 00 00 02 60 12
					15 00 00 40 00 00 02 61 32
					15 00 00 40 00 00 02 62 44
					15 00 00 40 00 00 02 63 40
					15 00 00 40 00 00 02 64 00
					15 00 00 40 00 00 02 65 00
					15 00 00 40 00 00 02 76 C0
					15 00 00 40 00 00 02 77 E8
					15 00 00 40 00 00 02 FE 43
					15 00 00 40 00 00 02 64 1B
					15 00 00 40 00 00 02 63 05
					15 00 00 40 00 00 02 66 06
					15 00 00 40 00 00 02 67 22
					15 00 00 40 00 00 02 68 22
					15 00 00 40 00 00 02 69 B3
					15 00 00 40 00 00 02 6A 33
					15 00 00 40 00 00 02 6B 0B
					15 00 00 40 00 00 02 6C 16
					15 00 00 40 00 00 02 6D 21
					15 00 00 40 00 00 02 6F 37
					15 00 00 40 00 00 02 70 42
					15 00 00 40 00 00 02 71 4D
					15 00 00 40 00 00 02 72 58
					15 00 00 40 00 00 02 73 0B
					15 00 00 40 00 00 02 74 16
					15 00 00 40 00 00 02 75 21
					15 00 00 40 00 00 02 76 2C
					15 00 00 40 00 00 02 77 37
					15 00 00 40 00 00 02 78 42
					15 00 00 40 00 00 02 79 4D
					15 00 00 40 00 00 02 7A 58
					15 00 00 40 00 00 02 7B 0B
					15 00 00 40 00 00 02 7C 16
					15 00 00 40 00 00 02 7D 21
					15 00 00 40 00 00 02 7E 2C
					15 00 00 40 00 00 02 7F 37
					15 00 00 40 00 00 02 80 42
					15 00 00 40 00 00 02 81 4D
					15 00 00 40 00 00 02 82 58
					15 00 00 40 00 00 02 83 0B
					15 00 00 40 00 00 02 84 16
					15 00 00 40 00 00 02 85 21
					15 00 00 40 00 00 02 86 2C
					15 00 00 40 00 00 02 87 37
					15 00 00 40 00 00 02 88 42
					15 00 00 40 00 00 02 89 4D
					15 00 00 40 00 00 02 8A 58
					15 00 00 40 00 00 02 8B 58
					15 00 00 40 00 00 02 8C 4D
					15 00 00 40 00 00 02 8D 42
					15 00 00 40 00 00 02 8E 37
					15 00 00 40 00 00 02 8F 2C
					15 00 00 40 00 00 02 90 21
					15 00 00 40 00 00 02 91 16
					15 00 00 40 00 00 02 92 0B
					15 00 00 40 00 00 02 93 58
					15 00 00 40 00 00 02 94 4D
					15 00 00 40 00 00 02 95 42
					15 00 00 40 00 00 02 96 37
					15 00 00 40 00 00 02 97 2C
					15 00 00 40 00 00 02 98 21
					15 00 00 40 00 00 02 99 16
					15 00 00 40 00 00 02 9A 0B
					15 00 00 40 00 00 02 9B 58
					15 00 00 40 00 00 02 9C 4D
					15 00 00 40 00 00 02 9D 42
					15 00 00 40 00 00 02 9E 37
					15 00 00 40 00 00 02 9F 2C
					15 00 00 40 00 00 02 A0 21
					15 00 00 40 00 00 02 A2 16
					15 00 00 40 00 00 02 A3 0B
					15 00 00 40 00 00 02 A4 58
					15 00 00 40 00 00 02 A5 4D
					15 00 00 40 00 00 02 A6 42
					15 00 00 40 00 00 02 A7 37
					15 00 00 40 00 00 02 A9 2C
					15 00 00 40 00 00 02 AA 21
					15 00 00 40 00 00 02 AB 16
					15 00 00 40 00 00 02 AC 0B
					15 00 00 40 00 00 02 AD 16
					15 00 00 40 00 00 02 AE 2C
					15 00 00 40 00 00 02 AF 16
					15 00 00 40 00 00 02 B0 2C
					15 00 00 40 00 00 02 B1 16
					15 00 00 40 00 00 02 B2 2C
					15 00 00 40 00 00 02 B3 16
					15 00 00 40 00 00 02 B4 2C
					15 00 00 40 00 00 02 B5 16
					15 00 00 40 00 00 02 B6 2C
					15 00 00 40 00 00 02 B7 16
					15 00 00 40 00 00 02 B8 2C
					15 00 00 40 00 00 02 B9 16
					15 00 00 40 00 00 02 BA 2C
					15 00 00 40 00 00 02 BB 16
					15 00 00 40 00 00 02 BC 2C
					15 00 00 40 00 00 02 BD 16
					15 00 00 40 00 00 02 BE 2C
					15 00 00 40 00 00 02 BF 16
					15 00 00 40 00 00 02 C0 2C
					15 00 00 40 00 00 02 C1 16
					15 00 00 40 00 00 02 C2 2C
					15 00 00 40 00 00 02 C3 16
					15 00 00 40 00 00 02 C4 2C
					15 00 00 40 00 00 02 C5 16
					15 00 00 40 00 00 02 C6 2C
					15 00 00 40 00 00 02 C7 16
					15 00 00 40 00 00 02 C8 2C
					15 00 00 40 00 00 02 C9 16
					15 00 00 40 00 00 02 CA 2C
					15 00 00 40 00 00 02 CB 16
					15 00 00 40 00 00 02 CC 2C
					15 00 00 40 00 00 02 CD 2C
					15 00 00 40 00 00 02 CE 16
					15 00 00 40 00 00 02 CF 2C
					15 00 00 40 00 00 02 D0 16
					15 00 00 40 00 00 02 D1 2C
					15 00 00 40 00 00 02 D2 16
					15 00 00 40 00 00 02 D3 2C
					15 00 00 40 00 00 02 D4 16
					15 00 00 40 00 00 02 D5 2C
					15 00 00 40 00 00 02 D6 16
					15 00 00 40 00 00 02 D7 2C
					15 00 00 40 00 00 02 D8 16
					15 00 00 40 00 00 02 D9 2C
					15 00 00 40 00 00 02 DA 16
					15 00 00 40 00 00 02 DB 2C
					15 00 00 40 00 00 02 DC 16
					15 00 00 40 00 00 02 DD 2C
					15 00 00 40 00 00 02 DE 16
					15 00 00 40 00 00 02 DF 2C
					15 00 00 40 00 00 02 E0 16
					15 00 00 40 00 00 02 E1 2C
					15 00 00 40 00 00 02 E2 16
					15 00 00 40 00 00 02 E3 2C
					15 00 00 40 00 00 02 E4 16
					15 00 00 40 00 00 02 E5 2C
					15 00 00 40 00 00 02 E6 16
					15 00 00 40 00 00 02 E7 2C
					15 00 00 40 00 00 02 E8 16
					15 00 00 40 00 00 02 E9 2C
					15 00 00 40 00 00 02 EA 16
					15 00 00 40 00 00 02 EB 2C
					15 00 00 40 00 00 02 EC 16
					15 00 00 40 00 00 02 FE 6A
					15 00 00 40 00 00 02 4E 00
					15 00 00 40 00 00 02 4F 00
					15 00 00 40 00 00 02 50 00
					15 00 00 40 00 00 02 51 00
					15 00 00 40 00 00 02 52 00
					15 00 00 40 00 00 02 53 00
					15 00 00 40 00 00 02 54 00
					15 00 00 40 00 00 02 55 00
					15 00 00 40 00 00 02 56 00
					15 00 00 40 00 00 02 58 00
					15 00 00 40 00 00 02 59 00
					15 00 00 40 00 00 02 5A 00
					15 00 00 40 00 00 02 5B 00
					15 00 00 40 00 00 02 5C 00
					15 00 00 40 00 00 02 5D 00
					15 00 00 40 00 00 02 5E 00
					15 00 00 40 00 00 02 FE 44
					15 00 00 40 00 00 02 78 3F
					15 00 00 40 00 00 02 79 E0
					15 00 00 40 00 00 02 66 00
					15 00 00 40 00 00 02 67 00
					15 00 00 40 00 00 02 FE 72
					15 00 00 40 00 00 02 F3 60
					15 00 00 40 00 00 02 33 01
					15 00 00 40 00 00 02 FE 98
					15 00 00 40 00 00 02 02 04
					15 00 00 00 00 00 02 03 EC
					//err flag setting
					15 00 00 40 00 00 02 FE D4
					15 00 00 40 00 00 02 40 03
					15 00 00 40 00 00 02 42 00
					15 00 00 40 00 00 02 FE 47
					15 00 00 40 00 00 02 80 26
					15 00 00 40 00 00 02 83 00
					15 00 00 40 00 00 02 FE 40
					15 00 00 40 00 00 02 DE A8
					15 00 00 40 00 00 02 FE A0
					15 00 00 40 00 00 02 06 04
					15 00 00 40 00 00 02 7C 15
					15 00 00 40 00 00 02 FE 42
					15 00 00 40 00 00 02 17 02
					15 00 00 40 00 00 02 FE A1
					15 00 00 40 00 00 02 74 72
					15 00 00 40 00 00 02 C3 FF
					15 00 00 40 00 00 02 C4 FF
					15 00 00 00 00 00 02 C5 7F
					// IC write
					15 00 00 40 00 00 02 FE 40
					15 00 00 40 00 00 02 92 70
					15 00 00 40 00 00 02 93 81
					15 00 00 40 00 00 02 FE 98
					15 00 00 40 00 00 02 7D 10
					15 00 00 40 00 00 02 C4 88
					15 00 00 40 00 00 02 C6 03
					15 00 00 40 00 00 02 C7 8F
					15 00 00 40 00 00 02 FE A1
					15 00 00 00 00 00 02 58 67
					// timing switch
					15 00 00 40 00 00 02 FE 00
					15 00 00 40 00 00 02 8A 1A // auto 90
					15 00 00 40 00 00 02 FE 98
					15 00 00 40 00 00 02 E3 08
					15 00 00 40 00 00 02 CB 01
					15 00 00 40 00 00 02 FE 44
					15 00 00 40 00 00 02 77 E8
					15 00 00 40 00 00 02 81 02
					15 00 00 40 00 00 02 82 08
					15 00 00 40 00 00 02 83 08
					// vsync out for Psensor
					15 00 00 40 00 00 02 FE D0
					15 00 00 40 00 00 02 1C 09
					15 00 00 40 00 00 02 FE 98
					15 00 00 40 00 00 02 E0 07
					15 00 00 40 00 00 02 E1 07
					15 00 00 40 00 00 02 E2 07
					15 00 00 40 00 00 02 FE 61
					15 00 00 40 00 00 02 48 11
					15 00 00 40 00 00 02 FE 62
					15 00 00 40 00 00 02 48 8D
					15 00 00 40 00 00 02 49 00
					15 00 00 40 00 00 02 4A 00
					15 00 00 40 00 00 02 4B 14
					15 00 00 40 00 00 02 4C 40
					15 00 00 40 00 00 02 4D 00
					15 00 00 40 00 00 02 4E 01
					15 00 00 00 00 00 02 4F 01
					// PPS lock
					15 00 00 00 00 00 02 FE FD
					15 00 00 00 00 00 02 90 01
					// PSCAN_CK1
					15 00 00 40 00 00 02 FE 62
					15 00 00 00 00 00 02 00 C7
					// Sleep Out
					15 00 00 00 00 00 02 FE 00
					05 00 00 00 78 00 01 11
					05 00 00 00 00 00 01 29
				];
				qcom,mdss-dsi-on-command-state = "dsi_hs_mode";
			};
			timing@wqhd_normal_30hz_index_03 {
				#include "dsi-panel-p2-42-06-0a-sec-dsc-cmd-common.dtsi"
				cell-index = <3>;
				qcom,mdss-dsi-panel-framerate = <30>;
				qcom,mdss-dsi-h-sync-skew = <0>;
				qcom,mdss-dsi-timing-switch-command = [
					15 00 00 40 00 00 02 F1 A6
					15 00 00 40 00 00 02 FE 00
					15 00 00 40 00 00 02 8A 12 // fix 30
					15 00 00 40 00 00 02 FE 98
					15 00 00 40 00 00 02 E3 04
					15 00 00 40 00 00 02 CB 01
					15 00 00 40 00 00 02 FE 44
					15 00 00 40 00 00 02 77 48
					15 00 00 40 00 00 02 FE 00
					15 00 00 00 00 00 02 FB AA
				];
				qcom,mdss-dsi-timing-switch-command-state = "dsi_hs_mode";
				qcom,mdss-dsi-on-command = [
					/* round corner */
					15 00 00 40 00 00 02 FE 27
					15 00 00 40 00 00 02 BF 01
					15 00 00 40 00 00 02 F6 01
					15 00 00 40 00 00 02 FE 27
					15 00 00 40 00 00 02 0F F2
					15 00 00 40 00 00 02 13 2C
					15 00 00 40 00 00 02 19 86
					15 00 00 40 00 00 02 1A 14
					15 00 00 40 00 00 02 1B 40
					15 00 00 40 00 00 02 26 63
					15 00 00 40 00 00 02 27 63
					15 00 00 40 00 00 02 29 64
					15 00 00 40 00 00 02 2A 78
					15 00 00 40 00 00 02 2F 00
					15 00 00 40 00 00 02 30 6F
					15 00 00 40 00 00 02 31 95
					15 00 00 40 00 00 02 32 00
					15 00 00 40 00 00 02 33 96
					15 00 00 40 00 00 02 34 78
					15 00 00 40 00 00 02 35 00
					15 00 00 40 00 00 02 36 04
					15 00 00 40 00 00 02 37 07
					15 00 00 40 00 00 02 38 95
					15 00 00 40 00 00 02 39 6F
					15 00 00 40 00 00 02 3A 00
					15 00 00 40 00 00 02 3B 96
					15 00 00 40 00 00 02 3F 78
					15 00 00 40 00 00 02 40 00
					15 00 00 40 00 00 02 41 04
					15 00 00 40 00 00 02 42 07
					15 00 00 40 00 00 02 77 86
					15 00 00 40 00 00 02 78 A0
					15 00 00 40 00 00 02 80 64
					15 00 00 40 00 00 02 81 64
					15 00 00 40 00 00 02 83 63
					15 00 00 40 00 00 02 90 86
					15 00 00 40 00 00 02 91 A0
					15 00 00 40 00 00 02 B6 00
					15 00 00 40 00 00 02 B7 44
					15 00 00 40 00 00 02 C1 24
					15 00 00 40 00 00 02 C3 24
					15 00 00 40 00 00 02 FE 28
					15 00 00 40 00 00 02 37 18
					15 00 00 40 00 00 02 58 18
					15 00 00 40 00 00 02 FE 90
					15 00 00 40 00 00 02 08 00
					15 00 00 00 00 00 02 09 00
					/* init code */
					15 00 00 40 00 00 02 FE D2
					15 00 00 40 00 00 02 97 00
					15 00 00 40 00 00 02 FE 00
					15 00 00 40 00 00 02 FA 01
					15 00 00 40 00 00 02 FE 00
					15 00 00 40 00 00 02 2F 04
					15 00 00 40 00 00 02 8A 10
					15 00 00 40 00 00 02 FE 00
					39 00 00 40 00 00 05 2A 00 00 02 53
					39 00 00 40 00 00 05 2B 00 00 03 CF
					15 00 00 40 00 00 02 35 00
					39 00 00 00 00 00 03 51 00 00
					/* frame skip */
					15 00 00 40 00 00 02 FE 44
					15 00 00 40 00 00 02 00 88
					15 00 00 40 00 00 02 AA 00
					15 00 00 40 00 00 02 01 08
					15 00 00 40 00 00 02 02 01
					15 00 00 40 00 00 02 03 01
					15 00 00 40 00 00 02 04 32
					15 00 00 40 00 00 02 05 01
					15 00 00 40 00 00 02 06 00
					15 00 00 40 00 00 02 07 00
					15 00 00 40 00 00 02 08 00
					15 00 00 40 00 00 02 09 00
					15 00 00 40 00 00 02 0A 00
					15 00 00 40 00 00 02 0B 00
					15 00 00 40 00 00 02 0C 00
					15 00 00 40 00 00 02 0D 11
					15 00 00 40 00 00 02 0E 11
					15 00 00 40 00 00 02 0F 11
					15 00 00 40 00 00 02 10 11
					15 00 00 40 00 00 02 15 01
					15 00 00 40 00 00 02 16 03
					15 00 00 40 00 00 02 17 00
					15 00 00 40 00 00 02 18 00
					15 00 00 40 00 00 02 19 00
					15 00 00 40 00 00 02 1A 00
					15 00 00 40 00 00 02 1B 00
					15 00 00 40 00 00 02 1C 00
					15 00 00 40 00 00 02 1D 11
					15 00 00 40 00 00 02 1E 11
					15 00 00 40 00 00 02 1F 11
					15 00 00 40 00 00 02 20 11
					15 00 00 40 00 00 02 25 01
					15 00 00 40 00 00 02 26 03
					15 00 00 40 00 00 02 27 0B
					15 00 00 40 00 00 02 28 0B
					15 00 00 40 00 00 02 29 00
					15 00 00 40 00 00 02 2A 00
					15 00 00 40 00 00 02 2B 00
					15 00 00 40 00 00 02 2D 00
					15 00 00 40 00 00 02 2F 11
					15 00 00 40 00 00 02 30 FF
					15 00 00 40 00 00 02 31 11
					15 00 00 40 00 00 02 32 11
					15 00 00 40 00 00 02 37 01
					15 00 00 40 00 00 02 38 03
					15 00 00 40 00 00 02 39 04
					15 00 00 40 00 00 02 3A 00
					15 00 00 40 00 00 02 3B 00
					15 00 00 40 00 00 02 3D 00
					15 00 00 40 00 00 02 3F 00
					15 00 00 40 00 00 02 40 00
					15 00 00 40 00 00 02 41 11
					15 00 00 40 00 00 02 42 11
					15 00 00 40 00 00 02 43 11
					15 00 00 40 00 00 02 44 11
					15 00 00 40 00 00 02 69 00
					15 00 00 40 00 00 02 6A 00
					15 00 00 40 00 00 02 6B 00
					15 00 00 40 00 00 02 6C 00
					15 00 00 40 00 00 02 6D 00
					15 00 00 40 00 00 02 6E 00
					15 00 00 40 00 00 02 6F 00
					15 00 00 40 00 00 02 70 00
					15 00 00 40 00 00 02 80 42
					15 00 00 40 00 00 02 81 03
					15 00 00 40 00 00 02 82 0B
					15 00 00 40 00 00 02 83 0B
					15 00 00 40 00 00 02 84 00
					15 00 00 40 00 00 02 85 00
					15 00 00 40 00 00 02 86 00
					15 00 00 40 00 00 02 87 00
					15 00 00 40 00 00 02 88 00
					15 00 00 40 00 00 02 89 00
					15 00 00 40 00 00 02 8A 00
					15 00 00 40 00 00 02 8B 1F
					15 00 00 40 00 00 02 8C F1
					15 00 00 40 00 00 02 8D 11
					15 00 00 40 00 00 02 8E 11
					15 00 00 40 00 00 02 49 00
					15 00 00 40 00 00 02 4A 00
					15 00 00 40 00 00 02 4B 04
					15 00 00 40 00 00 02 4C 00
					15 00 00 40 00 00 02 4D 00
					15 00 00 40 00 00 02 4E 01
					15 00 00 40 00 00 02 4F 03
					15 00 00 40 00 00 02 50 04
					15 00 00 40 00 00 02 51 0B
					15 00 00 40 00 00 02 52 77
					15 00 00 40 00 00 02 53 EF
					15 00 00 40 00 00 02 54 77
					15 00 00 40 00 00 02 55 77
					15 00 00 40 00 00 02 56 0B
					15 00 00 40 00 00 02 58 59
					15 00 00 40 00 00 02 59 00
					15 00 00 40 00 00 02 5A 00
					15 00 00 40 00 00 02 5B 00
					15 00 00 40 00 00 02 5C 00
					15 00 00 40 00 00 02 5D 00
					15 00 00 40 00 00 02 98 00
					15 00 00 40 00 00 02 99 00
					15 00 00 40 00 00 02 9A 00
					15 00 00 40 00 00 02 9B 00
					15 00 00 40 00 00 02 9C 00
					15 00 00 40 00 00 02 9D 00
					15 00 00 40 00 00 02 9E 00
					15 00 00 40 00 00 02 9F 00
					15 00 00 40 00 00 02 A0 00
					15 00 00 40 00 00 02 A2 00
					15 00 00 40 00 00 02 A3 00
					15 00 00 40 00 00 02 A4 00
					15 00 00 40 00 00 02 A5 00
					15 00 00 40 00 00 02 A6 00
					15 00 00 40 00 00 02 A7 00
					15 00 00 40 00 00 02 A9 00
					15 00 00 40 00 00 02 5E 00
					15 00 00 40 00 00 02 5F 01
					15 00 00 40 00 00 02 60 12
					15 00 00 40 00 00 02 61 32
					15 00 00 40 00 00 02 62 44
					15 00 00 40 00 00 02 63 40
					15 00 00 40 00 00 02 64 00
					15 00 00 40 00 00 02 65 00
					15 00 00 40 00 00 02 76 C0
					15 00 00 40 00 00 02 77 E8
					15 00 00 40 00 00 02 FE 43
					15 00 00 40 00 00 02 64 1B
					15 00 00 40 00 00 02 63 05
					15 00 00 40 00 00 02 66 06
					15 00 00 40 00 00 02 67 22
					15 00 00 40 00 00 02 68 22
					15 00 00 40 00 00 02 69 B3
					15 00 00 40 00 00 02 6A 33
					15 00 00 40 00 00 02 6B 0B
					15 00 00 40 00 00 02 6C 16
					15 00 00 40 00 00 02 6D 21
					15 00 00 40 00 00 02 6F 37
					15 00 00 40 00 00 02 70 42
					15 00 00 40 00 00 02 71 4D
					15 00 00 40 00 00 02 72 58
					15 00 00 40 00 00 02 73 0B
					15 00 00 40 00 00 02 74 16
					15 00 00 40 00 00 02 75 21
					15 00 00 40 00 00 02 76 2C
					15 00 00 40 00 00 02 77 37
					15 00 00 40 00 00 02 78 42
					15 00 00 40 00 00 02 79 4D
					15 00 00 40 00 00 02 7A 58
					15 00 00 40 00 00 02 7B 0B
					15 00 00 40 00 00 02 7C 16
					15 00 00 40 00 00 02 7D 21
					15 00 00 40 00 00 02 7E 2C
					15 00 00 40 00 00 02 7F 37
					15 00 00 40 00 00 02 80 42
					15 00 00 40 00 00 02 81 4D
					15 00 00 40 00 00 02 82 58
					15 00 00 40 00 00 02 83 0B
					15 00 00 40 00 00 02 84 16
					15 00 00 40 00 00 02 85 21
					15 00 00 40 00 00 02 86 2C
					15 00 00 40 00 00 02 87 37
					15 00 00 40 00 00 02 88 42
					15 00 00 40 00 00 02 89 4D
					15 00 00 40 00 00 02 8A 58
					15 00 00 40 00 00 02 8B 58
					15 00 00 40 00 00 02 8C 4D
					15 00 00 40 00 00 02 8D 42
					15 00 00 40 00 00 02 8E 37
					15 00 00 40 00 00 02 8F 2C
					15 00 00 40 00 00 02 90 21
					15 00 00 40 00 00 02 91 16
					15 00 00 40 00 00 02 92 0B
					15 00 00 40 00 00 02 93 58
					15 00 00 40 00 00 02 94 4D
					15 00 00 40 00 00 02 95 42
					15 00 00 40 00 00 02 96 37
					15 00 00 40 00 00 02 97 2C
					15 00 00 40 00 00 02 98 21
					15 00 00 40 00 00 02 99 16
					15 00 00 40 00 00 02 9A 0B
					15 00 00 40 00 00 02 9B 58
					15 00 00 40 00 00 02 9C 4D
					15 00 00 40 00 00 02 9D 42
					15 00 00 40 00 00 02 9E 37
					15 00 00 40 00 00 02 9F 2C
					15 00 00 40 00 00 02 A0 21
					15 00 00 40 00 00 02 A2 16
					15 00 00 40 00 00 02 A3 0B
					15 00 00 40 00 00 02 A4 58
					15 00 00 40 00 00 02 A5 4D
					15 00 00 40 00 00 02 A6 42
					15 00 00 40 00 00 02 A7 37
					15 00 00 40 00 00 02 A9 2C
					15 00 00 40 00 00 02 AA 21
					15 00 00 40 00 00 02 AB 16
					15 00 00 40 00 00 02 AC 0B
					15 00 00 40 00 00 02 AD 16
					15 00 00 40 00 00 02 AE 2C
					15 00 00 40 00 00 02 AF 16
					15 00 00 40 00 00 02 B0 2C
					15 00 00 40 00 00 02 B1 16
					15 00 00 40 00 00 02 B2 2C
					15 00 00 40 00 00 02 B3 16
					15 00 00 40 00 00 02 B4 2C
					15 00 00 40 00 00 02 B5 16
					15 00 00 40 00 00 02 B6 2C
					15 00 00 40 00 00 02 B7 16
					15 00 00 40 00 00 02 B8 2C
					15 00 00 40 00 00 02 B9 16
					15 00 00 40 00 00 02 BA 2C
					15 00 00 40 00 00 02 BB 16
					15 00 00 40 00 00 02 BC 2C
					15 00 00 40 00 00 02 BD 16
					15 00 00 40 00 00 02 BE 2C
					15 00 00 40 00 00 02 BF 16
					15 00 00 40 00 00 02 C0 2C
					15 00 00 40 00 00 02 C1 16
					15 00 00 40 00 00 02 C2 2C
					15 00 00 40 00 00 02 C3 16
					15 00 00 40 00 00 02 C4 2C
					15 00 00 40 00 00 02 C5 16
					15 00 00 40 00 00 02 C6 2C
					15 00 00 40 00 00 02 C7 16
					15 00 00 40 00 00 02 C8 2C
					15 00 00 40 00 00 02 C9 16
					15 00 00 40 00 00 02 CA 2C
					15 00 00 40 00 00 02 CB 16
					15 00 00 40 00 00 02 CC 2C
					15 00 00 40 00 00 02 CD 2C
					15 00 00 40 00 00 02 CE 16
					15 00 00 40 00 00 02 CF 2C
					15 00 00 40 00 00 02 D0 16
					15 00 00 40 00 00 02 D1 2C
					15 00 00 40 00 00 02 D2 16
					15 00 00 40 00 00 02 D3 2C
					15 00 00 40 00 00 02 D4 16
					15 00 00 40 00 00 02 D5 2C
					15 00 00 40 00 00 02 D6 16
					15 00 00 40 00 00 02 D7 2C
					15 00 00 40 00 00 02 D8 16
					15 00 00 40 00 00 02 D9 2C
					15 00 00 40 00 00 02 DA 16
					15 00 00 40 00 00 02 DB 2C
					15 00 00 40 00 00 02 DC 16
					15 00 00 40 00 00 02 DD 2C
					15 00 00 40 00 00 02 DE 16
					15 00 00 40 00 00 02 DF 2C
					15 00 00 40 00 00 02 E0 16
					15 00 00 40 00 00 02 E1 2C
					15 00 00 40 00 00 02 E2 16
					15 00 00 40 00 00 02 E3 2C
					15 00 00 40 00 00 02 E4 16
					15 00 00 40 00 00 02 E5 2C
					15 00 00 40 00 00 02 E6 16
					15 00 00 40 00 00 02 E7 2C
					15 00 00 40 00 00 02 E8 16
					15 00 00 40 00 00 02 E9 2C
					15 00 00 40 00 00 02 EA 16
					15 00 00 40 00 00 02 EB 2C
					15 00 00 40 00 00 02 EC 16
					15 00 00 40 00 00 02 FE 6A
					15 00 00 40 00 00 02 4E 00
					15 00 00 40 00 00 02 4F 00
					15 00 00 40 00 00 02 50 00
					15 00 00 40 00 00 02 51 00
					15 00 00 40 00 00 02 52 00
					15 00 00 40 00 00 02 53 00
					15 00 00 40 00 00 02 54 00
					15 00 00 40 00 00 02 55 00
					15 00 00 40 00 00 02 56 00
					15 00 00 40 00 00 02 58 00
					15 00 00 40 00 00 02 59 00
					15 00 00 40 00 00 02 5A 00
					15 00 00 40 00 00 02 5B 00
					15 00 00 40 00 00 02 5C 00
					15 00 00 40 00 00 02 5D 00
					15 00 00 40 00 00 02 5E 00
					15 00 00 40 00 00 02 FE 44
					15 00 00 40 00 00 02 78 3F
					15 00 00 40 00 00 02 79 E0
					15 00 00 40 00 00 02 66 00
					15 00 00 40 00 00 02 67 00
					15 00 00 40 00 00 02 FE 72
					15 00 00 40 00 00 02 F3 60
					15 00 00 40 00 00 02 33 01
					15 00 00 40 00 00 02 FE 98
					15 00 00 40 00 00 02 02 04
					15 00 00 00 00 00 02 03 EC
					//err flag setting
					15 00 00 40 00 00 02 FE D4
					15 00 00 40 00 00 02 40 03
					15 00 00 40 00 00 02 42 00
					15 00 00 40 00 00 02 FE 47
					15 00 00 40 00 00 02 80 26
					15 00 00 40 00 00 02 83 00
					15 00 00 40 00 00 02 FE 40
					15 00 00 40 00 00 02 DE A8
					15 00 00 40 00 00 02 FE A0
					15 00 00 40 00 00 02 06 04
					15 00 00 40 00 00 02 7C 15
					15 00 00 40 00 00 02 FE 42
					15 00 00 40 00 00 02 17 02
					15 00 00 40 00 00 02 FE A1
					15 00 00 40 00 00 02 74 72
					15 00 00 40 00 00 02 C3 FF
					15 00 00 40 00 00 02 C4 FF
					15 00 00 00 00 00 02 C5 7F
					// IC write
					15 00 00 40 00 00 02 FE 40
					15 00 00 40 00 00 02 92 70
					15 00 00 40 00 00 02 93 81
					15 00 00 40 00 00 02 FE 98
					15 00 00 40 00 00 02 7D 10
					15 00 00 40 00 00 02 C4 88
					15 00 00 40 00 00 02 C6 03
					15 00 00 40 00 00 02 C7 8F
					15 00 00 40 00 00 02 FE A1
					15 00 00 00 00 00 02 58 67
					// timing switch
					15 00 00 40 00 00 02 FE 00
					15 00 00 40 00 00 02 8A 12 // fix 30
					15 00 00 40 00 00 02 FE 98
					15 00 00 40 00 00 02 E3 04
					15 00 00 40 00 00 02 CB 01
					15 00 00 40 00 00 02 FE 44
					15 00 00 40 00 00 02 77 48
					// vsync out for Psensor
					15 00 00 40 00 00 02 FE D0
					15 00 00 40 00 00 02 1C 09
					15 00 00 40 00 00 02 FE 98
					15 00 00 40 00 00 02 E0 07
					15 00 00 40 00 00 02 E1 07
					15 00 00 40 00 00 02 E2 07
					15 00 00 40 00 00 02 FE 61
					15 00 00 40 00 00 02 48 11
					15 00 00 40 00 00 02 FE 62
					15 00 00 40 00 00 02 48 8D
					15 00 00 40 00 00 02 49 00
					15 00 00 40 00 00 02 4A 00
					15 00 00 40 00 00 02 4B 14
					15 00 00 40 00 00 02 4C 40
					15 00 00 40 00 00 02 4D 00
					15 00 00 40 00 00 02 4E 01
					15 00 00 00 00 00 02 4F 01
					// PPS lock
					15 00 00 00 00 00 02 FE FD
					15 00 00 00 00 00 02 90 01
					// PSCAN_CK1
					15 00 00 40 00 00 02 FE 62
					15 00 00 00 00 00 02 00 C7
					// Sleep Out
					15 00 00 00 00 00 02 FE 00
					05 00 00 00 78 00 01 11
					05 00 00 00 00 00 01 29
				];
				qcom,mdss-dsi-on-command-state = "dsi_hs_mode";
			};
			timing@wqhd_normal_24hz_index_04 {
				#include "dsi-panel-p2-42-06-0a-sec-dsc-cmd-common.dtsi"
				cell-index = <4>;
				qcom,mdss-dsi-panel-framerate = <24>;
				qcom,mdss-dsi-h-sync-skew = <0>;
				qcom,mdss-dsi-timing-switch-command = [
					15 00 00 40 00 00 02 F1 A6
					15 00 00 40 00 00 02 FE 00
					15 00 00 40 00 00 02 8A 13 // fix 24
					15 00 00 40 00 00 02 FE 98
					15 00 00 40 00 00 02 E3 04
					15 00 00 40 00 00 02 CB 01
					15 00 00 40 00 00 02 FE 44
					15 00 00 40 00 00 02 77 48
					15 00 00 40 00 00 02 FE 00
					15 00 00 00 00 00 02 FB AA
				];
				qcom,mdss-dsi-timing-switch-command-state = "dsi_hs_mode";
				qcom,mdss-dsi-on-command = [
					/* round corner */
					15 00 00 40 00 00 02 FE 27
					15 00 00 40 00 00 02 BF 01
					15 00 00 40 00 00 02 F6 01
					15 00 00 40 00 00 02 FE 27
					15 00 00 40 00 00 02 0F F2
					15 00 00 40 00 00 02 13 2C
					15 00 00 40 00 00 02 19 86
					15 00 00 40 00 00 02 1A 14
					15 00 00 40 00 00 02 1B 40
					15 00 00 40 00 00 02 26 63
					15 00 00 40 00 00 02 27 63
					15 00 00 40 00 00 02 29 64
					15 00 00 40 00 00 02 2A 78
					15 00 00 40 00 00 02 2F 00
					15 00 00 40 00 00 02 30 6F
					15 00 00 40 00 00 02 31 95
					15 00 00 40 00 00 02 32 00
					15 00 00 40 00 00 02 33 96
					15 00 00 40 00 00 02 34 78
					15 00 00 40 00 00 02 35 00
					15 00 00 40 00 00 02 36 04
					15 00 00 40 00 00 02 37 07
					15 00 00 40 00 00 02 38 95
					15 00 00 40 00 00 02 39 6F
					15 00 00 40 00 00 02 3A 00
					15 00 00 40 00 00 02 3B 96
					15 00 00 40 00 00 02 3F 78
					15 00 00 40 00 00 02 40 00
					15 00 00 40 00 00 02 41 04
					15 00 00 40 00 00 02 42 07
					15 00 00 40 00 00 02 77 86
					15 00 00 40 00 00 02 78 A0
					15 00 00 40 00 00 02 80 64
					15 00 00 40 00 00 02 81 64
					15 00 00 40 00 00 02 83 63
					15 00 00 40 00 00 02 90 86
					15 00 00 40 00 00 02 91 A0
					15 00 00 40 00 00 02 B6 00
					15 00 00 40 00 00 02 B7 44
					15 00 00 40 00 00 02 C1 24
					15 00 00 40 00 00 02 C3 24
					15 00 00 40 00 00 02 FE 28
					15 00 00 40 00 00 02 37 18
					15 00 00 40 00 00 02 58 18
					15 00 00 40 00 00 02 FE 90
					15 00 00 40 00 00 02 08 00
					15 00 00 00 00 00 02 09 00
					/* init code */
					15 00 00 40 00 00 02 FE D2
					15 00 00 40 00 00 02 97 00
					15 00 00 40 00 00 02 FE 00
					15 00 00 40 00 00 02 FA 01
					15 00 00 40 00 00 02 FE 00
					15 00 00 40 00 00 02 2F 04
					15 00 00 40 00 00 02 8A 10
					15 00 00 40 00 00 02 FE 00
					39 00 00 40 00 00 05 2A 00 00 02 53
					39 00 00 40 00 00 05 2B 00 00 03 CF
					15 00 00 40 00 00 02 35 00
					39 00 00 00 00 00 03 51 00 00
					/* frame skip */
					15 00 00 40 00 00 02 FE 44
					15 00 00 40 00 00 02 00 88
					15 00 00 40 00 00 02 AA 00
					15 00 00 40 00 00 02 01 08
					15 00 00 40 00 00 02 02 01
					15 00 00 40 00 00 02 03 01
					15 00 00 40 00 00 02 04 32
					15 00 00 40 00 00 02 05 01
					15 00 00 40 00 00 02 06 00
					15 00 00 40 00 00 02 07 00
					15 00 00 40 00 00 02 08 00
					15 00 00 40 00 00 02 09 00
					15 00 00 40 00 00 02 0A 00
					15 00 00 40 00 00 02 0B 00
					15 00 00 40 00 00 02 0C 00
					15 00 00 40 00 00 02 0D 11
					15 00 00 40 00 00 02 0E 11
					15 00 00 40 00 00 02 0F 11
					15 00 00 40 00 00 02 10 11
					15 00 00 40 00 00 02 15 01
					15 00 00 40 00 00 02 16 03
					15 00 00 40 00 00 02 17 00
					15 00 00 40 00 00 02 18 00
					15 00 00 40 00 00 02 19 00
					15 00 00 40 00 00 02 1A 00
					15 00 00 40 00 00 02 1B 00
					15 00 00 40 00 00 02 1C 00
					15 00 00 40 00 00 02 1D 11
					15 00 00 40 00 00 02 1E 11
					15 00 00 40 00 00 02 1F 11
					15 00 00 40 00 00 02 20 11
					15 00 00 40 00 00 02 25 01
					15 00 00 40 00 00 02 26 03
					15 00 00 40 00 00 02 27 0B
					15 00 00 40 00 00 02 28 0B
					15 00 00 40 00 00 02 29 00
					15 00 00 40 00 00 02 2A 00
					15 00 00 40 00 00 02 2B 00
					15 00 00 40 00 00 02 2D 00
					15 00 00 40 00 00 02 2F 11
					15 00 00 40 00 00 02 30 FF
					15 00 00 40 00 00 02 31 11
					15 00 00 40 00 00 02 32 11
					15 00 00 40 00 00 02 37 01
					15 00 00 40 00 00 02 38 03
					15 00 00 40 00 00 02 39 04
					15 00 00 40 00 00 02 3A 00
					15 00 00 40 00 00 02 3B 00
					15 00 00 40 00 00 02 3D 00
					15 00 00 40 00 00 02 3F 00
					15 00 00 40 00 00 02 40 00
					15 00 00 40 00 00 02 41 11
					15 00 00 40 00 00 02 42 11
					15 00 00 40 00 00 02 43 11
					15 00 00 40 00 00 02 44 11
					15 00 00 40 00 00 02 69 00
					15 00 00 40 00 00 02 6A 00
					15 00 00 40 00 00 02 6B 00
					15 00 00 40 00 00 02 6C 00
					15 00 00 40 00 00 02 6D 00
					15 00 00 40 00 00 02 6E 00
					15 00 00 40 00 00 02 6F 00
					15 00 00 40 00 00 02 70 00
					15 00 00 40 00 00 02 80 42
					15 00 00 40 00 00 02 81 03
					15 00 00 40 00 00 02 82 0B
					15 00 00 40 00 00 02 83 0B
					15 00 00 40 00 00 02 84 00
					15 00 00 40 00 00 02 85 00
					15 00 00 40 00 00 02 86 00
					15 00 00 40 00 00 02 87 00
					15 00 00 40 00 00 02 88 00
					15 00 00 40 00 00 02 89 00
					15 00 00 40 00 00 02 8A 00
					15 00 00 40 00 00 02 8B 1F
					15 00 00 40 00 00 02 8C F1
					15 00 00 40 00 00 02 8D 11
					15 00 00 40 00 00 02 8E 11
					15 00 00 40 00 00 02 49 00
					15 00 00 40 00 00 02 4A 00
					15 00 00 40 00 00 02 4B 04
					15 00 00 40 00 00 02 4C 00
					15 00 00 40 00 00 02 4D 00
					15 00 00 40 00 00 02 4E 01
					15 00 00 40 00 00 02 4F 03
					15 00 00 40 00 00 02 50 04
					15 00 00 40 00 00 02 51 0B
					15 00 00 40 00 00 02 52 77
					15 00 00 40 00 00 02 53 EF
					15 00 00 40 00 00 02 54 77
					15 00 00 40 00 00 02 55 77
					15 00 00 40 00 00 02 56 0B
					15 00 00 40 00 00 02 58 59
					15 00 00 40 00 00 02 59 00
					15 00 00 40 00 00 02 5A 00
					15 00 00 40 00 00 02 5B 00
					15 00 00 40 00 00 02 5C 00
					15 00 00 40 00 00 02 5D 00
					15 00 00 40 00 00 02 98 00
					15 00 00 40 00 00 02 99 00
					15 00 00 40 00 00 02 9A 00
					15 00 00 40 00 00 02 9B 00
					15 00 00 40 00 00 02 9C 00
					15 00 00 40 00 00 02 9D 00
					15 00 00 40 00 00 02 9E 00
					15 00 00 40 00 00 02 9F 00
					15 00 00 40 00 00 02 A0 00
					15 00 00 40 00 00 02 A2 00
					15 00 00 40 00 00 02 A3 00
					15 00 00 40 00 00 02 A4 00
					15 00 00 40 00 00 02 A5 00
					15 00 00 40 00 00 02 A6 00
					15 00 00 40 00 00 02 A7 00
					15 00 00 40 00 00 02 A9 00
					15 00 00 40 00 00 02 5E 00
					15 00 00 40 00 00 02 5F 01
					15 00 00 40 00 00 02 60 12
					15 00 00 40 00 00 02 61 32
					15 00 00 40 00 00 02 62 44
					15 00 00 40 00 00 02 63 40
					15 00 00 40 00 00 02 64 00
					15 00 00 40 00 00 02 65 00
					15 00 00 40 00 00 02 76 C0
					15 00 00 40 00 00 02 77 E8
					15 00 00 40 00 00 02 FE 43
					15 00 00 40 00 00 02 64 1B
					15 00 00 40 00 00 02 63 05
					15 00 00 40 00 00 02 66 06
					15 00 00 40 00 00 02 67 22
					15 00 00 40 00 00 02 68 22
					15 00 00 40 00 00 02 69 B3
					15 00 00 40 00 00 02 6A 33
					15 00 00 40 00 00 02 6B 0B
					15 00 00 40 00 00 02 6C 16
					15 00 00 40 00 00 02 6D 21
					15 00 00 40 00 00 02 6F 37
					15 00 00 40 00 00 02 70 42
					15 00 00 40 00 00 02 71 4D
					15 00 00 40 00 00 02 72 58
					15 00 00 40 00 00 02 73 0B
					15 00 00 40 00 00 02 74 16
					15 00 00 40 00 00 02 75 21
					15 00 00 40 00 00 02 76 2C
					15 00 00 40 00 00 02 77 37
					15 00 00 40 00 00 02 78 42
					15 00 00 40 00 00 02 79 4D
					15 00 00 40 00 00 02 7A 58
					15 00 00 40 00 00 02 7B 0B
					15 00 00 40 00 00 02 7C 16
					15 00 00 40 00 00 02 7D 21
					15 00 00 40 00 00 02 7E 2C
					15 00 00 40 00 00 02 7F 37
					15 00 00 40 00 00 02 80 42
					15 00 00 40 00 00 02 81 4D
					15 00 00 40 00 00 02 82 58
					15 00 00 40 00 00 02 83 0B
					15 00 00 40 00 00 02 84 16
					15 00 00 40 00 00 02 85 21
					15 00 00 40 00 00 02 86 2C
					15 00 00 40 00 00 02 87 37
					15 00 00 40 00 00 02 88 42
					15 00 00 40 00 00 02 89 4D
					15 00 00 40 00 00 02 8A 58
					15 00 00 40 00 00 02 8B 58
					15 00 00 40 00 00 02 8C 4D
					15 00 00 40 00 00 02 8D 42
					15 00 00 40 00 00 02 8E 37
					15 00 00 40 00 00 02 8F 2C
					15 00 00 40 00 00 02 90 21
					15 00 00 40 00 00 02 91 16
					15 00 00 40 00 00 02 92 0B
					15 00 00 40 00 00 02 93 58
					15 00 00 40 00 00 02 94 4D
					15 00 00 40 00 00 02 95 42
					15 00 00 40 00 00 02 96 37
					15 00 00 40 00 00 02 97 2C
					15 00 00 40 00 00 02 98 21
					15 00 00 40 00 00 02 99 16
					15 00 00 40 00 00 02 9A 0B
					15 00 00 40 00 00 02 9B 58
					15 00 00 40 00 00 02 9C 4D
					15 00 00 40 00 00 02 9D 42
					15 00 00 40 00 00 02 9E 37
					15 00 00 40 00 00 02 9F 2C
					15 00 00 40 00 00 02 A0 21
					15 00 00 40 00 00 02 A2 16
					15 00 00 40 00 00 02 A3 0B
					15 00 00 40 00 00 02 A4 58
					15 00 00 40 00 00 02 A5 4D
					15 00 00 40 00 00 02 A6 42
					15 00 00 40 00 00 02 A7 37
					15 00 00 40 00 00 02 A9 2C
					15 00 00 40 00 00 02 AA 21
					15 00 00 40 00 00 02 AB 16
					15 00 00 40 00 00 02 AC 0B
					15 00 00 40 00 00 02 AD 16
					15 00 00 40 00 00 02 AE 2C
					15 00 00 40 00 00 02 AF 16
					15 00 00 40 00 00 02 B0 2C
					15 00 00 40 00 00 02 B1 16
					15 00 00 40 00 00 02 B2 2C
					15 00 00 40 00 00 02 B3 16
					15 00 00 40 00 00 02 B4 2C
					15 00 00 40 00 00 02 B5 16
					15 00 00 40 00 00 02 B6 2C
					15 00 00 40 00 00 02 B7 16
					15 00 00 40 00 00 02 B8 2C
					15 00 00 40 00 00 02 B9 16
					15 00 00 40 00 00 02 BA 2C
					15 00 00 40 00 00 02 BB 16
					15 00 00 40 00 00 02 BC 2C
					15 00 00 40 00 00 02 BD 16
					15 00 00 40 00 00 02 BE 2C
					15 00 00 40 00 00 02 BF 16
					15 00 00 40 00 00 02 C0 2C
					15 00 00 40 00 00 02 C1 16
					15 00 00 40 00 00 02 C2 2C
					15 00 00 40 00 00 02 C3 16
					15 00 00 40 00 00 02 C4 2C
					15 00 00 40 00 00 02 C5 16
					15 00 00 40 00 00 02 C6 2C
					15 00 00 40 00 00 02 C7 16
					15 00 00 40 00 00 02 C8 2C
					15 00 00 40 00 00 02 C9 16
					15 00 00 40 00 00 02 CA 2C
					15 00 00 40 00 00 02 CB 16
					15 00 00 40 00 00 02 CC 2C
					15 00 00 40 00 00 02 CD 2C
					15 00 00 40 00 00 02 CE 16
					15 00 00 40 00 00 02 CF 2C
					15 00 00 40 00 00 02 D0 16
					15 00 00 40 00 00 02 D1 2C
					15 00 00 40 00 00 02 D2 16
					15 00 00 40 00 00 02 D3 2C
					15 00 00 40 00 00 02 D4 16
					15 00 00 40 00 00 02 D5 2C
					15 00 00 40 00 00 02 D6 16
					15 00 00 40 00 00 02 D7 2C
					15 00 00 40 00 00 02 D8 16
					15 00 00 40 00 00 02 D9 2C
					15 00 00 40 00 00 02 DA 16
					15 00 00 40 00 00 02 DB 2C
					15 00 00 40 00 00 02 DC 16
					15 00 00 40 00 00 02 DD 2C
					15 00 00 40 00 00 02 DE 16
					15 00 00 40 00 00 02 DF 2C
					15 00 00 40 00 00 02 E0 16
					15 00 00 40 00 00 02 E1 2C
					15 00 00 40 00 00 02 E2 16
					15 00 00 40 00 00 02 E3 2C
					15 00 00 40 00 00 02 E4 16
					15 00 00 40 00 00 02 E5 2C
					15 00 00 40 00 00 02 E6 16
					15 00 00 40 00 00 02 E7 2C
					15 00 00 40 00 00 02 E8 16
					15 00 00 40 00 00 02 E9 2C
					15 00 00 40 00 00 02 EA 16
					15 00 00 40 00 00 02 EB 2C
					15 00 00 40 00 00 02 EC 16
					15 00 00 40 00 00 02 FE 6A
					15 00 00 40 00 00 02 4E 00
					15 00 00 40 00 00 02 4F 00
					15 00 00 40 00 00 02 50 00
					15 00 00 40 00 00 02 51 00
					15 00 00 40 00 00 02 52 00
					15 00 00 40 00 00 02 53 00
					15 00 00 40 00 00 02 54 00
					15 00 00 40 00 00 02 55 00
					15 00 00 40 00 00 02 56 00
					15 00 00 40 00 00 02 58 00
					15 00 00 40 00 00 02 59 00
					15 00 00 40 00 00 02 5A 00
					15 00 00 40 00 00 02 5B 00
					15 00 00 40 00 00 02 5C 00
					15 00 00 40 00 00 02 5D 00
					15 00 00 40 00 00 02 5E 00
					15 00 00 40 00 00 02 FE 44
					15 00 00 40 00 00 02 78 3F
					15 00 00 40 00 00 02 79 E0
					15 00 00 40 00 00 02 66 00
					15 00 00 40 00 00 02 67 00
					15 00 00 40 00 00 02 FE 72
					15 00 00 40 00 00 02 F3 60
					15 00 00 40 00 00 02 33 01
					15 00 00 40 00 00 02 FE 98
					15 00 00 40 00 00 02 02 04
					15 00 00 00 00 00 02 03 EC
					//err flag setting
					15 00 00 40 00 00 02 FE D4
					15 00 00 40 00 00 02 40 03
					15 00 00 40 00 00 02 42 00
					15 00 00 40 00 00 02 FE 47
					15 00 00 40 00 00 02 80 26
					15 00 00 40 00 00 02 83 00
					15 00 00 40 00 00 02 FE 40
					15 00 00 40 00 00 02 DE A8
					15 00 00 40 00 00 02 FE A0
					15 00 00 40 00 00 02 06 04
					15 00 00 40 00 00 02 7C 15
					15 00 00 40 00 00 02 FE 42
					15 00 00 40 00 00 02 17 02
					15 00 00 40 00 00 02 FE A1
					15 00 00 40 00 00 02 74 72
					15 00 00 40 00 00 02 C3 FF
					15 00 00 40 00 00 02 C4 FF
					15 00 00 00 00 00 02 C5 7F
					// IC write
					15 00 00 40 00 00 02 FE 40
					15 00 00 40 00 00 02 92 70
					15 00 00 40 00 00 02 93 81
					15 00 00 40 00 00 02 FE 98
					15 00 00 40 00 00 02 7D 10
					15 00 00 40 00 00 02 C4 88
					15 00 00 40 00 00 02 C6 03
					15 00 00 40 00 00 02 C7 8F
					15 00 00 40 00 00 02 FE A1
					15 00 00 00 00 00 02 58 67
					// timing switch
					15 00 00 40 00 00 02 FE 00
					15 00 00 40 00 00 02 8A 13 // fix 24
					15 00 00 40 00 00 02 FE 98
					15 00 00 40 00 00 02 E3 04
					15 00 00 40 00 00 02 CB 01
					15 00 00 40 00 00 02 FE 44
					15 00 00 40 00 00 02 77 48
					// vsync out for Psensor
					15 00 00 40 00 00 02 FE D0
					15 00 00 40 00 00 02 1C 09
					15 00 00 40 00 00 02 FE 98
					15 00 00 40 00 00 02 E0 07
					15 00 00 40 00 00 02 E1 07
					15 00 00 40 00 00 02 E2 07
					15 00 00 40 00 00 02 FE 61
					15 00 00 40 00 00 02 48 11
					15 00 00 40 00 00 02 FE 62
					15 00 00 40 00 00 02 48 8D
					15 00 00 40 00 00 02 49 00
					15 00 00 40 00 00 02 4A 00
					15 00 00 40 00 00 02 4B 14
					15 00 00 40 00 00 02 4C 40
					15 00 00 40 00 00 02 4D 00
					15 00 00 40 00 00 02 4E 01
					15 00 00 00 00 00 02 4F 01
					// PPS lock
					15 00 00 00 00 00 02 FE FD
					15 00 00 00 00 00 02 90 01
					// PSCAN_CK1
					15 00 00 40 00 00 02 FE 62
					15 00 00 00 00 00 02 00 C7
					// Sleep Out
					15 00 00 00 00 00 02 FE 00
					05 00 00 00 78 00 01 11
					05 00 00 00 00 00 01 29
				];
				qcom,mdss-dsi-on-command-state = "dsi_hs_mode";
			};
			timing@wqhd_idle_120_to_10hz_index_05 {
				#include "dsi-panel-p2-42-06-0a-sec-dsc-cmd-common.dtsi"
				cell-index = <5>;
				qcom,mdss-dsi-panel-framerate = <120>;
				/* ---------------------------- */
				/* | 15 - 14 | 13 - 7 | 6 - 0 | */
				/* ---------------------------- */
				/* |   mode  | sf fps | min fps| */
				/* ---------------------------- -*/
				/* mode: 1 idle, 2 auto, 3 qsync */
				/*   1 << 14 | 120 << 7 | 10     */
				qcom,mdss-dsi-h-sync-skew = <31754>;
				/* mode: 0 normal, 1 idle, 2 auto, 3 qsync, 4 diff, 5 test */
				mi,mdss-dsi-ddic-mode = "idle";
				mi,mdss-dsi-sf-framerate = <120>;
				mi,mdss-dsi-ddic-min-framerate = <10>;
				qcom,mdss-dsi-timing-switch-command = [
					15 00 00 40 00 00 02 F1 A6
					15 00 00 40 00 00 02 FE 00
					15 00 00 40 00 00 02 8A 14 // idle 120 - 10
					15 00 00 40 00 00 02 FE 98
					15 00 00 40 00 00 02 E3 08
					15 00 00 40 00 00 02 CB 01
					15 00 00 40 00 00 02 FE 44
					15 00 00 40 00 00 02 77 E8
					15 00 00 40 00 00 02 FE 00
					15 00 00 00 00 00 02 FB AA
				];
				qcom,mdss-dsi-timing-switch-command-state = "dsi_hs_mode";
				qcom,mdss-dsi-on-command = [
					/* round corner */
					15 00 00 40 00 00 02 FE 27
					15 00 00 40 00 00 02 BF 01
					15 00 00 40 00 00 02 F6 01
					15 00 00 40 00 00 02 FE 27
					15 00 00 40 00 00 02 0F F2
					15 00 00 40 00 00 02 13 2C
					15 00 00 40 00 00 02 19 86
					15 00 00 40 00 00 02 1A 14
					15 00 00 40 00 00 02 1B 40
					15 00 00 40 00 00 02 26 63
					15 00 00 40 00 00 02 27 63
					15 00 00 40 00 00 02 29 64
					15 00 00 40 00 00 02 2A 78
					15 00 00 40 00 00 02 2F 00
					15 00 00 40 00 00 02 30 6F
					15 00 00 40 00 00 02 31 95
					15 00 00 40 00 00 02 32 00
					15 00 00 40 00 00 02 33 96
					15 00 00 40 00 00 02 34 78
					15 00 00 40 00 00 02 35 00
					15 00 00 40 00 00 02 36 04
					15 00 00 40 00 00 02 37 07
					15 00 00 40 00 00 02 38 95
					15 00 00 40 00 00 02 39 6F
					15 00 00 40 00 00 02 3A 00
					15 00 00 40 00 00 02 3B 96
					15 00 00 40 00 00 02 3F 78
					15 00 00 40 00 00 02 40 00
					15 00 00 40 00 00 02 41 04
					15 00 00 40 00 00 02 42 07
					15 00 00 40 00 00 02 77 86
					15 00 00 40 00 00 02 78 A0
					15 00 00 40 00 00 02 80 64
					15 00 00 40 00 00 02 81 64
					15 00 00 40 00 00 02 83 63
					15 00 00 40 00 00 02 90 86
					15 00 00 40 00 00 02 91 A0
					15 00 00 40 00 00 02 B6 00
					15 00 00 40 00 00 02 B7 44
					15 00 00 40 00 00 02 C1 24
					15 00 00 40 00 00 02 C3 24
					15 00 00 40 00 00 02 FE 28
					15 00 00 40 00 00 02 37 18
					15 00 00 40 00 00 02 58 18
					15 00 00 40 00 00 02 FE 90
					15 00 00 40 00 00 02 08 00
					15 00 00 00 00 00 02 09 00
					/* init code */
					15 00 00 40 00 00 02 FE D2
					15 00 00 40 00 00 02 97 00
					15 00 00 40 00 00 02 FE 00
					15 00 00 40 00 00 02 FA 01
					15 00 00 40 00 00 02 FE 00
					15 00 00 40 00 00 02 2F 04
					15 00 00 40 00 00 02 8A 10
					15 00 00 40 00 00 02 FE 00
					39 00 00 40 00 00 05 2A 00 00 02 53
					39 00 00 40 00 00 05 2B 00 00 03 CF
					15 00 00 40 00 00 02 35 00
					39 00 00 00 00 00 03 51 00 00
					/* frame skip */
					15 00 00 40 00 00 02 FE 44
					15 00 00 40 00 00 02 00 88
					15 00 00 40 00 00 02 AA 00
					15 00 00 40 00 00 02 01 08
					15 00 00 40 00 00 02 02 01
					15 00 00 40 00 00 02 03 01
					15 00 00 40 00 00 02 04 32
					15 00 00 40 00 00 02 05 01
					15 00 00 40 00 00 02 06 00
					15 00 00 40 00 00 02 07 00
					15 00 00 40 00 00 02 08 00
					15 00 00 40 00 00 02 09 00
					15 00 00 40 00 00 02 0A 00
					15 00 00 40 00 00 02 0B 00
					15 00 00 40 00 00 02 0C 00
					15 00 00 40 00 00 02 0D 11
					15 00 00 40 00 00 02 0E 11
					15 00 00 40 00 00 02 0F 11
					15 00 00 40 00 00 02 10 11
					15 00 00 40 00 00 02 15 01
					15 00 00 40 00 00 02 16 03
					15 00 00 40 00 00 02 17 00
					15 00 00 40 00 00 02 18 00
					15 00 00 40 00 00 02 19 00
					15 00 00 40 00 00 02 1A 00
					15 00 00 40 00 00 02 1B 00
					15 00 00 40 00 00 02 1C 00
					15 00 00 40 00 00 02 1D 11
					15 00 00 40 00 00 02 1E 11
					15 00 00 40 00 00 02 1F 11
					15 00 00 40 00 00 02 20 11
					15 00 00 40 00 00 02 25 01
					15 00 00 40 00 00 02 26 03
					15 00 00 40 00 00 02 27 0B
					15 00 00 40 00 00 02 28 0B
					15 00 00 40 00 00 02 29 00
					15 00 00 40 00 00 02 2A 00
					15 00 00 40 00 00 02 2B 00
					15 00 00 40 00 00 02 2D 00
					15 00 00 40 00 00 02 2F 11
					15 00 00 40 00 00 02 30 FF
					15 00 00 40 00 00 02 31 11
					15 00 00 40 00 00 02 32 11
					15 00 00 40 00 00 02 37 01
					15 00 00 40 00 00 02 38 03
					15 00 00 40 00 00 02 39 04
					15 00 00 40 00 00 02 3A 00
					15 00 00 40 00 00 02 3B 00
					15 00 00 40 00 00 02 3D 00
					15 00 00 40 00 00 02 3F 00
					15 00 00 40 00 00 02 40 00
					15 00 00 40 00 00 02 41 11
					15 00 00 40 00 00 02 42 11
					15 00 00 40 00 00 02 43 11
					15 00 00 40 00 00 02 44 11
					15 00 00 40 00 00 02 69 00
					15 00 00 40 00 00 02 6A 00
					15 00 00 40 00 00 02 6B 00
					15 00 00 40 00 00 02 6C 00
					15 00 00 40 00 00 02 6D 00
					15 00 00 40 00 00 02 6E 00
					15 00 00 40 00 00 02 6F 00
					15 00 00 40 00 00 02 70 00
					15 00 00 40 00 00 02 80 42
					15 00 00 40 00 00 02 81 03
					15 00 00 40 00 00 02 82 0B
					15 00 00 40 00 00 02 83 0B
					15 00 00 40 00 00 02 84 00
					15 00 00 40 00 00 02 85 00
					15 00 00 40 00 00 02 86 00
					15 00 00 40 00 00 02 87 00
					15 00 00 40 00 00 02 88 00
					15 00 00 40 00 00 02 89 00
					15 00 00 40 00 00 02 8A 00
					15 00 00 40 00 00 02 8B 1F
					15 00 00 40 00 00 02 8C F1
					15 00 00 40 00 00 02 8D 11
					15 00 00 40 00 00 02 8E 11
					15 00 00 40 00 00 02 49 00
					15 00 00 40 00 00 02 4A 00
					15 00 00 40 00 00 02 4B 04
					15 00 00 40 00 00 02 4C 00
					15 00 00 40 00 00 02 4D 00
					15 00 00 40 00 00 02 4E 01
					15 00 00 40 00 00 02 4F 03
					15 00 00 40 00 00 02 50 04
					15 00 00 40 00 00 02 51 0B
					15 00 00 40 00 00 02 52 77
					15 00 00 40 00 00 02 53 EF
					15 00 00 40 00 00 02 54 77
					15 00 00 40 00 00 02 55 77
					15 00 00 40 00 00 02 56 0B
					15 00 00 40 00 00 02 58 59
					15 00 00 40 00 00 02 59 00
					15 00 00 40 00 00 02 5A 00
					15 00 00 40 00 00 02 5B 00
					15 00 00 40 00 00 02 5C 00
					15 00 00 40 00 00 02 5D 00
					15 00 00 40 00 00 02 98 00
					15 00 00 40 00 00 02 99 00
					15 00 00 40 00 00 02 9A 00
					15 00 00 40 00 00 02 9B 00
					15 00 00 40 00 00 02 9C 00
					15 00 00 40 00 00 02 9D 00
					15 00 00 40 00 00 02 9E 00
					15 00 00 40 00 00 02 9F 00
					15 00 00 40 00 00 02 A0 00
					15 00 00 40 00 00 02 A2 00
					15 00 00 40 00 00 02 A3 00
					15 00 00 40 00 00 02 A4 00
					15 00 00 40 00 00 02 A5 00
					15 00 00 40 00 00 02 A6 00
					15 00 00 40 00 00 02 A7 00
					15 00 00 40 00 00 02 A9 00
					15 00 00 40 00 00 02 5E 00
					15 00 00 40 00 00 02 5F 01
					15 00 00 40 00 00 02 60 12
					15 00 00 40 00 00 02 61 32
					15 00 00 40 00 00 02 62 44
					15 00 00 40 00 00 02 63 40
					15 00 00 40 00 00 02 64 00
					15 00 00 40 00 00 02 65 00
					15 00 00 40 00 00 02 76 C0
					15 00 00 40 00 00 02 77 E8
					15 00 00 40 00 00 02 FE 43
					15 00 00 40 00 00 02 64 1B
					15 00 00 40 00 00 02 63 05
					15 00 00 40 00 00 02 66 06
					15 00 00 40 00 00 02 67 22
					15 00 00 40 00 00 02 68 22
					15 00 00 40 00 00 02 69 B3
					15 00 00 40 00 00 02 6A 33
					15 00 00 40 00 00 02 6B 0B
					15 00 00 40 00 00 02 6C 16
					15 00 00 40 00 00 02 6D 21
					15 00 00 40 00 00 02 6F 37
					15 00 00 40 00 00 02 70 42
					15 00 00 40 00 00 02 71 4D
					15 00 00 40 00 00 02 72 58
					15 00 00 40 00 00 02 73 0B
					15 00 00 40 00 00 02 74 16
					15 00 00 40 00 00 02 75 21
					15 00 00 40 00 00 02 76 2C
					15 00 00 40 00 00 02 77 37
					15 00 00 40 00 00 02 78 42
					15 00 00 40 00 00 02 79 4D
					15 00 00 40 00 00 02 7A 58
					15 00 00 40 00 00 02 7B 0B
					15 00 00 40 00 00 02 7C 16
					15 00 00 40 00 00 02 7D 21
					15 00 00 40 00 00 02 7E 2C
					15 00 00 40 00 00 02 7F 37
					15 00 00 40 00 00 02 80 42
					15 00 00 40 00 00 02 81 4D
					15 00 00 40 00 00 02 82 58
					15 00 00 40 00 00 02 83 0B
					15 00 00 40 00 00 02 84 16
					15 00 00 40 00 00 02 85 21
					15 00 00 40 00 00 02 86 2C
					15 00 00 40 00 00 02 87 37
					15 00 00 40 00 00 02 88 42
					15 00 00 40 00 00 02 89 4D
					15 00 00 40 00 00 02 8A 58
					15 00 00 40 00 00 02 8B 58
					15 00 00 40 00 00 02 8C 4D
					15 00 00 40 00 00 02 8D 42
					15 00 00 40 00 00 02 8E 37
					15 00 00 40 00 00 02 8F 2C
					15 00 00 40 00 00 02 90 21
					15 00 00 40 00 00 02 91 16
					15 00 00 40 00 00 02 92 0B
					15 00 00 40 00 00 02 93 58
					15 00 00 40 00 00 02 94 4D
					15 00 00 40 00 00 02 95 42
					15 00 00 40 00 00 02 96 37
					15 00 00 40 00 00 02 97 2C
					15 00 00 40 00 00 02 98 21
					15 00 00 40 00 00 02 99 16
					15 00 00 40 00 00 02 9A 0B
					15 00 00 40 00 00 02 9B 58
					15 00 00 40 00 00 02 9C 4D
					15 00 00 40 00 00 02 9D 42
					15 00 00 40 00 00 02 9E 37
					15 00 00 40 00 00 02 9F 2C
					15 00 00 40 00 00 02 A0 21
					15 00 00 40 00 00 02 A2 16
					15 00 00 40 00 00 02 A3 0B
					15 00 00 40 00 00 02 A4 58
					15 00 00 40 00 00 02 A5 4D
					15 00 00 40 00 00 02 A6 42
					15 00 00 40 00 00 02 A7 37
					15 00 00 40 00 00 02 A9 2C
					15 00 00 40 00 00 02 AA 21
					15 00 00 40 00 00 02 AB 16
					15 00 00 40 00 00 02 AC 0B
					15 00 00 40 00 00 02 AD 16
					15 00 00 40 00 00 02 AE 2C
					15 00 00 40 00 00 02 AF 16
					15 00 00 40 00 00 02 B0 2C
					15 00 00 40 00 00 02 B1 16
					15 00 00 40 00 00 02 B2 2C
					15 00 00 40 00 00 02 B3 16
					15 00 00 40 00 00 02 B4 2C
					15 00 00 40 00 00 02 B5 16
					15 00 00 40 00 00 02 B6 2C
					15 00 00 40 00 00 02 B7 16
					15 00 00 40 00 00 02 B8 2C
					15 00 00 40 00 00 02 B9 16
					15 00 00 40 00 00 02 BA 2C
					15 00 00 40 00 00 02 BB 16
					15 00 00 40 00 00 02 BC 2C
					15 00 00 40 00 00 02 BD 16
					15 00 00 40 00 00 02 BE 2C
					15 00 00 40 00 00 02 BF 16
					15 00 00 40 00 00 02 C0 2C
					15 00 00 40 00 00 02 C1 16
					15 00 00 40 00 00 02 C2 2C
					15 00 00 40 00 00 02 C3 16
					15 00 00 40 00 00 02 C4 2C
					15 00 00 40 00 00 02 C5 16
					15 00 00 40 00 00 02 C6 2C
					15 00 00 40 00 00 02 C7 16
					15 00 00 40 00 00 02 C8 2C
					15 00 00 40 00 00 02 C9 16
					15 00 00 40 00 00 02 CA 2C
					15 00 00 40 00 00 02 CB 16
					15 00 00 40 00 00 02 CC 2C
					15 00 00 40 00 00 02 CD 2C
					15 00 00 40 00 00 02 CE 16
					15 00 00 40 00 00 02 CF 2C
					15 00 00 40 00 00 02 D0 16
					15 00 00 40 00 00 02 D1 2C
					15 00 00 40 00 00 02 D2 16
					15 00 00 40 00 00 02 D3 2C
					15 00 00 40 00 00 02 D4 16
					15 00 00 40 00 00 02 D5 2C
					15 00 00 40 00 00 02 D6 16
					15 00 00 40 00 00 02 D7 2C
					15 00 00 40 00 00 02 D8 16
					15 00 00 40 00 00 02 D9 2C
					15 00 00 40 00 00 02 DA 16
					15 00 00 40 00 00 02 DB 2C
					15 00 00 40 00 00 02 DC 16
					15 00 00 40 00 00 02 DD 2C
					15 00 00 40 00 00 02 DE 16
					15 00 00 40 00 00 02 DF 2C
					15 00 00 40 00 00 02 E0 16
					15 00 00 40 00 00 02 E1 2C
					15 00 00 40 00 00 02 E2 16
					15 00 00 40 00 00 02 E3 2C
					15 00 00 40 00 00 02 E4 16
					15 00 00 40 00 00 02 E5 2C
					15 00 00 40 00 00 02 E6 16
					15 00 00 40 00 00 02 E7 2C
					15 00 00 40 00 00 02 E8 16
					15 00 00 40 00 00 02 E9 2C
					15 00 00 40 00 00 02 EA 16
					15 00 00 40 00 00 02 EB 2C
					15 00 00 40 00 00 02 EC 16
					15 00 00 40 00 00 02 FE 6A
					15 00 00 40 00 00 02 4E 00
					15 00 00 40 00 00 02 4F 00
					15 00 00 40 00 00 02 50 00
					15 00 00 40 00 00 02 51 00
					15 00 00 40 00 00 02 52 00
					15 00 00 40 00 00 02 53 00
					15 00 00 40 00 00 02 54 00
					15 00 00 40 00 00 02 55 00
					15 00 00 40 00 00 02 56 00
					15 00 00 40 00 00 02 58 00
					15 00 00 40 00 00 02 59 00
					15 00 00 40 00 00 02 5A 00
					15 00 00 40 00 00 02 5B 00
					15 00 00 40 00 00 02 5C 00
					15 00 00 40 00 00 02 5D 00
					15 00 00 40 00 00 02 5E 00
					15 00 00 40 00 00 02 FE 44
					15 00 00 40 00 00 02 78 3F
					15 00 00 40 00 00 02 79 E0
					15 00 00 40 00 00 02 66 00
					15 00 00 40 00 00 02 67 00
					15 00 00 40 00 00 02 FE 72
					15 00 00 40 00 00 02 F3 60
					15 00 00 40 00 00 02 33 01
					15 00 00 40 00 00 02 FE 98
					15 00 00 40 00 00 02 02 04
					15 00 00 00 00 00 02 03 EC
					//err flag setting
					15 00 00 40 00 00 02 FE D4
					15 00 00 40 00 00 02 40 03
					15 00 00 40 00 00 02 42 00
					15 00 00 40 00 00 02 FE 47
					15 00 00 40 00 00 02 80 26
					15 00 00 40 00 00 02 83 00
					15 00 00 40 00 00 02 FE 40
					15 00 00 40 00 00 02 DE A8
					15 00 00 40 00 00 02 FE A0
					15 00 00 40 00 00 02 06 04
					15 00 00 40 00 00 02 7C 15
					15 00 00 40 00 00 02 FE 42
					15 00 00 40 00 00 02 17 02
					15 00 00 40 00 00 02 FE A1
					15 00 00 40 00 00 02 74 72
					15 00 00 40 00 00 02 C3 FF
					15 00 00 40 00 00 02 C4 FF
					15 00 00 00 00 00 02 C5 7F
					// IC write
					15 00 00 40 00 00 02 FE 40
					15 00 00 40 00 00 02 92 70
					15 00 00 40 00 00 02 93 81
					15 00 00 40 00 00 02 FE 98
					15 00 00 40 00 00 02 7D 10
					15 00 00 40 00 00 02 C4 88
					15 00 00 40 00 00 02 C6 03
					15 00 00 40 00 00 02 C7 8F
					15 00 00 40 00 00 02 FE A1
					15 00 00 00 00 00 02 58 67
					// timing switch
					15 00 00 40 00 00 02 FE 00
					15 00 00 40 00 00 02 8A 14 // idle 120 - 10
					15 00 00 40 00 00 02 FE 98
					15 00 00 40 00 00 02 E3 08
					15 00 00 40 00 00 02 CB 01
					15 00 00 40 00 00 02 FE 44
					15 00 00 40 00 00 02 77 E8
					// vsync out for Psensor
					15 00 00 40 00 00 02 FE D0
					15 00 00 40 00 00 02 1C 09
					15 00 00 40 00 00 02 FE 98
					15 00 00 40 00 00 02 E0 07
					15 00 00 40 00 00 02 E1 07
					15 00 00 40 00 00 02 E2 07
					15 00 00 40 00 00 02 FE 61
					15 00 00 40 00 00 02 48 11
					15 00 00 40 00 00 02 FE 62
					15 00 00 40 00 00 02 48 8D
					15 00 00 40 00 00 02 49 00
					15 00 00 40 00 00 02 4A 00
					15 00 00 40 00 00 02 4B 14
					15 00 00 40 00 00 02 4C 40
					15 00 00 40 00 00 02 4D 00
					15 00 00 40 00 00 02 4E 01
					15 00 00 00 00 00 02 4F 01
					// PPS lock
					15 00 00 00 00 00 02 FE FD
					15 00 00 00 00 00 02 90 01
					// PSCAN_CK1
					15 00 00 40 00 00 02 FE 62
					15 00 00 00 00 00 02 00 C7
					// Sleep Out
					15 00 00 00 00 00 02 FE 00
					05 00 00 00 78 00 01 11
					05 00 00 00 00 00 01 29
				];
				qcom,mdss-dsi-on-command-state = "dsi_hs_mode";
			};
			timing@wqhd_idle_120_to_1hz_index_06 {
				#include "dsi-panel-p2-42-06-0a-sec-dsc-cmd-common.dtsi"
				cell-index = <6>;
				qcom,mdss-dsi-panel-framerate = <120>;
				/* ---------------------------- */
				/* | 15 - 14 | 13 - 7 | 6 - 0 | */
				/* ---------------------------- */
				/* |   mode  | sf fps | min fps| */
				/* ---------------------------- -*/
				/* mode: 1 idle, 2 auto, 3 qsync */
				/*   1 << 14 | 120 << 7 | 1     */
				qcom,mdss-dsi-h-sync-skew = <31745>;
				/* mode: 0 normal, 1 idle, 2 auto, 3 qsync, 4 diff, 5 test */
				mi,mdss-dsi-ddic-mode = "idle";
				mi,mdss-dsi-sf-framerate = <120>;
				mi,mdss-dsi-ddic-min-framerate = <1>;
				qcom,mdss-dsi-timing-switch-command = [
					15 00 00 40 00 00 02 F1 A6
					15 00 00 40 00 00 02 FE 00
					15 00 00 40 00 00 02 8A 15 // idle 120 - 1
					15 00 00 40 00 00 02 FE 98
					15 00 00 40 00 00 02 E3 08
					15 00 00 40 00 00 02 CB 01
					15 00 00 40 00 00 02 FE 44
					15 00 00 40 00 00 02 77 E8
					15 00 00 40 00 00 02 FE 00
					15 00 00 00 00 00 02 FB AA
				];
				qcom,mdss-dsi-timing-switch-command-state = "dsi_hs_mode";
				qcom,mdss-dsi-on-command = [
					/* round corner */
					15 00 00 40 00 00 02 FE 27
					15 00 00 40 00 00 02 BF 01
					15 00 00 40 00 00 02 F6 01
					15 00 00 40 00 00 02 FE 27
					15 00 00 40 00 00 02 0F F2
					15 00 00 40 00 00 02 13 2C
					15 00 00 40 00 00 02 19 86
					15 00 00 40 00 00 02 1A 14
					15 00 00 40 00 00 02 1B 40
					15 00 00 40 00 00 02 26 63
					15 00 00 40 00 00 02 27 63
					15 00 00 40 00 00 02 29 64
					15 00 00 40 00 00 02 2A 78
					15 00 00 40 00 00 02 2F 00
					15 00 00 40 00 00 02 30 6F
					15 00 00 40 00 00 02 31 95
					15 00 00 40 00 00 02 32 00
					15 00 00 40 00 00 02 33 96
					15 00 00 40 00 00 02 34 78
					15 00 00 40 00 00 02 35 00
					15 00 00 40 00 00 02 36 04
					15 00 00 40 00 00 02 37 07
					15 00 00 40 00 00 02 38 95
					15 00 00 40 00 00 02 39 6F
					15 00 00 40 00 00 02 3A 00
					15 00 00 40 00 00 02 3B 96
					15 00 00 40 00 00 02 3F 78
					15 00 00 40 00 00 02 40 00
					15 00 00 40 00 00 02 41 04
					15 00 00 40 00 00 02 42 07
					15 00 00 40 00 00 02 77 86
					15 00 00 40 00 00 02 78 A0
					15 00 00 40 00 00 02 80 64
					15 00 00 40 00 00 02 81 64
					15 00 00 40 00 00 02 83 63
					15 00 00 40 00 00 02 90 86
					15 00 00 40 00 00 02 91 A0
					15 00 00 40 00 00 02 B6 00
					15 00 00 40 00 00 02 B7 44
					15 00 00 40 00 00 02 C1 24
					15 00 00 40 00 00 02 C3 24
					15 00 00 40 00 00 02 FE 28
					15 00 00 40 00 00 02 37 18
					15 00 00 40 00 00 02 58 18
					15 00 00 40 00 00 02 FE 90
					15 00 00 40 00 00 02 08 00
					15 00 00 00 00 00 02 09 00
					/* init code */
					15 00 00 40 00 00 02 FE D2
					15 00 00 40 00 00 02 97 00
					15 00 00 40 00 00 02 FE 00
					15 00 00 40 00 00 02 FA 01
					15 00 00 40 00 00 02 FE 00
					15 00 00 40 00 00 02 2F 04
					15 00 00 40 00 00 02 8A 10
					15 00 00 40 00 00 02 FE 00
					39 00 00 40 00 00 05 2A 00 00 02 53
					39 00 00 40 00 00 05 2B 00 00 03 CF
					15 00 00 40 00 00 02 35 00
					39 00 00 00 00 00 03 51 00 00
					/* frame skip */
					15 00 00 40 00 00 02 FE 44
					15 00 00 40 00 00 02 00 88
					15 00 00 40 00 00 02 AA 00
					15 00 00 40 00 00 02 01 08
					15 00 00 40 00 00 02 02 01
					15 00 00 40 00 00 02 03 01
					15 00 00 40 00 00 02 04 32
					15 00 00 40 00 00 02 05 01
					15 00 00 40 00 00 02 06 00
					15 00 00 40 00 00 02 07 00
					15 00 00 40 00 00 02 08 00
					15 00 00 40 00 00 02 09 00
					15 00 00 40 00 00 02 0A 00
					15 00 00 40 00 00 02 0B 00
					15 00 00 40 00 00 02 0C 00
					15 00 00 40 00 00 02 0D 11
					15 00 00 40 00 00 02 0E 11
					15 00 00 40 00 00 02 0F 11
					15 00 00 40 00 00 02 10 11
					15 00 00 40 00 00 02 15 01
					15 00 00 40 00 00 02 16 03
					15 00 00 40 00 00 02 17 00
					15 00 00 40 00 00 02 18 00
					15 00 00 40 00 00 02 19 00
					15 00 00 40 00 00 02 1A 00
					15 00 00 40 00 00 02 1B 00
					15 00 00 40 00 00 02 1C 00
					15 00 00 40 00 00 02 1D 11
					15 00 00 40 00 00 02 1E 11
					15 00 00 40 00 00 02 1F 11
					15 00 00 40 00 00 02 20 11
					15 00 00 40 00 00 02 25 01
					15 00 00 40 00 00 02 26 03
					15 00 00 40 00 00 02 27 0B
					15 00 00 40 00 00 02 28 0B
					15 00 00 40 00 00 02 29 00
					15 00 00 40 00 00 02 2A 00
					15 00 00 40 00 00 02 2B 00
					15 00 00 40 00 00 02 2D 00
					15 00 00 40 00 00 02 2F 11
					15 00 00 40 00 00 02 30 FF
					15 00 00 40 00 00 02 31 11
					15 00 00 40 00 00 02 32 11
					15 00 00 40 00 00 02 37 01
					15 00 00 40 00 00 02 38 03
					15 00 00 40 00 00 02 39 04
					15 00 00 40 00 00 02 3A 00
					15 00 00 40 00 00 02 3B 00
					15 00 00 40 00 00 02 3D 00
					15 00 00 40 00 00 02 3F 00
					15 00 00 40 00 00 02 40 00
					15 00 00 40 00 00 02 41 11
					15 00 00 40 00 00 02 42 11
					15 00 00 40 00 00 02 43 11
					15 00 00 40 00 00 02 44 11
					15 00 00 40 00 00 02 69 00
					15 00 00 40 00 00 02 6A 00
					15 00 00 40 00 00 02 6B 00
					15 00 00 40 00 00 02 6C 00
					15 00 00 40 00 00 02 6D 00
					15 00 00 40 00 00 02 6E 00
					15 00 00 40 00 00 02 6F 00
					15 00 00 40 00 00 02 70 00
					15 00 00 40 00 00 02 80 42
					15 00 00 40 00 00 02 81 03
					15 00 00 40 00 00 02 82 0B
					15 00 00 40 00 00 02 83 0B
					15 00 00 40 00 00 02 84 00
					15 00 00 40 00 00 02 85 00
					15 00 00 40 00 00 02 86 00
					15 00 00 40 00 00 02 87 00
					15 00 00 40 00 00 02 88 00
					15 00 00 40 00 00 02 89 00
					15 00 00 40 00 00 02 8A 00
					15 00 00 40 00 00 02 8B 1F
					15 00 00 40 00 00 02 8C F1
					15 00 00 40 00 00 02 8D 11
					15 00 00 40 00 00 02 8E 11
					15 00 00 40 00 00 02 49 00
					15 00 00 40 00 00 02 4A 00
					15 00 00 40 00 00 02 4B 04
					15 00 00 40 00 00 02 4C 00
					15 00 00 40 00 00 02 4D 00
					15 00 00 40 00 00 02 4E 01
					15 00 00 40 00 00 02 4F 03
					15 00 00 40 00 00 02 50 04
					15 00 00 40 00 00 02 51 0B
					15 00 00 40 00 00 02 52 77
					15 00 00 40 00 00 02 53 EF
					15 00 00 40 00 00 02 54 77
					15 00 00 40 00 00 02 55 77
					15 00 00 40 00 00 02 56 0B
					15 00 00 40 00 00 02 58 59
					15 00 00 40 00 00 02 59 00
					15 00 00 40 00 00 02 5A 00
					15 00 00 40 00 00 02 5B 00
					15 00 00 40 00 00 02 5C 00
					15 00 00 40 00 00 02 5D 00
					15 00 00 40 00 00 02 98 00
					15 00 00 40 00 00 02 99 00
					15 00 00 40 00 00 02 9A 00
					15 00 00 40 00 00 02 9B 00
					15 00 00 40 00 00 02 9C 00
					15 00 00 40 00 00 02 9D 00
					15 00 00 40 00 00 02 9E 00
					15 00 00 40 00 00 02 9F 00
					15 00 00 40 00 00 02 A0 00
					15 00 00 40 00 00 02 A2 00
					15 00 00 40 00 00 02 A3 00
					15 00 00 40 00 00 02 A4 00
					15 00 00 40 00 00 02 A5 00
					15 00 00 40 00 00 02 A6 00
					15 00 00 40 00 00 02 A7 00
					15 00 00 40 00 00 02 A9 00
					15 00 00 40 00 00 02 5E 00
					15 00 00 40 00 00 02 5F 01
					15 00 00 40 00 00 02 60 12
					15 00 00 40 00 00 02 61 32
					15 00 00 40 00 00 02 62 44
					15 00 00 40 00 00 02 63 40
					15 00 00 40 00 00 02 64 00
					15 00 00 40 00 00 02 65 00
					15 00 00 40 00 00 02 76 C0
					15 00 00 40 00 00 02 77 E8
					15 00 00 40 00 00 02 FE 43
					15 00 00 40 00 00 02 64 1B
					15 00 00 40 00 00 02 63 05
					15 00 00 40 00 00 02 66 06
					15 00 00 40 00 00 02 67 22
					15 00 00 40 00 00 02 68 22
					15 00 00 40 00 00 02 69 B3
					15 00 00 40 00 00 02 6A 33
					15 00 00 40 00 00 02 6B 0B
					15 00 00 40 00 00 02 6C 16
					15 00 00 40 00 00 02 6D 21
					15 00 00 40 00 00 02 6F 37
					15 00 00 40 00 00 02 70 42
					15 00 00 40 00 00 02 71 4D
					15 00 00 40 00 00 02 72 58
					15 00 00 40 00 00 02 73 0B
					15 00 00 40 00 00 02 74 16
					15 00 00 40 00 00 02 75 21
					15 00 00 40 00 00 02 76 2C
					15 00 00 40 00 00 02 77 37
					15 00 00 40 00 00 02 78 42
					15 00 00 40 00 00 02 79 4D
					15 00 00 40 00 00 02 7A 58
					15 00 00 40 00 00 02 7B 0B
					15 00 00 40 00 00 02 7C 16
					15 00 00 40 00 00 02 7D 21
					15 00 00 40 00 00 02 7E 2C
					15 00 00 40 00 00 02 7F 37
					15 00 00 40 00 00 02 80 42
					15 00 00 40 00 00 02 81 4D
					15 00 00 40 00 00 02 82 58
					15 00 00 40 00 00 02 83 0B
					15 00 00 40 00 00 02 84 16
					15 00 00 40 00 00 02 85 21
					15 00 00 40 00 00 02 86 2C
					15 00 00 40 00 00 02 87 37
					15 00 00 40 00 00 02 88 42
					15 00 00 40 00 00 02 89 4D
					15 00 00 40 00 00 02 8A 58
					15 00 00 40 00 00 02 8B 58
					15 00 00 40 00 00 02 8C 4D
					15 00 00 40 00 00 02 8D 42
					15 00 00 40 00 00 02 8E 37
					15 00 00 40 00 00 02 8F 2C
					15 00 00 40 00 00 02 90 21
					15 00 00 40 00 00 02 91 16
					15 00 00 40 00 00 02 92 0B
					15 00 00 40 00 00 02 93 58
					15 00 00 40 00 00 02 94 4D
					15 00 00 40 00 00 02 95 42
					15 00 00 40 00 00 02 96 37
					15 00 00 40 00 00 02 97 2C
					15 00 00 40 00 00 02 98 21
					15 00 00 40 00 00 02 99 16
					15 00 00 40 00 00 02 9A 0B
					15 00 00 40 00 00 02 9B 58
					15 00 00 40 00 00 02 9C 4D
					15 00 00 40 00 00 02 9D 42
					15 00 00 40 00 00 02 9E 37
					15 00 00 40 00 00 02 9F 2C
					15 00 00 40 00 00 02 A0 21
					15 00 00 40 00 00 02 A2 16
					15 00 00 40 00 00 02 A3 0B
					15 00 00 40 00 00 02 A4 58
					15 00 00 40 00 00 02 A5 4D
					15 00 00 40 00 00 02 A6 42
					15 00 00 40 00 00 02 A7 37
					15 00 00 40 00 00 02 A9 2C
					15 00 00 40 00 00 02 AA 21
					15 00 00 40 00 00 02 AB 16
					15 00 00 40 00 00 02 AC 0B
					15 00 00 40 00 00 02 AD 16
					15 00 00 40 00 00 02 AE 2C
					15 00 00 40 00 00 02 AF 16
					15 00 00 40 00 00 02 B0 2C
					15 00 00 40 00 00 02 B1 16
					15 00 00 40 00 00 02 B2 2C
					15 00 00 40 00 00 02 B3 16
					15 00 00 40 00 00 02 B4 2C
					15 00 00 40 00 00 02 B5 16
					15 00 00 40 00 00 02 B6 2C
					15 00 00 40 00 00 02 B7 16
					15 00 00 40 00 00 02 B8 2C
					15 00 00 40 00 00 02 B9 16
					15 00 00 40 00 00 02 BA 2C
					15 00 00 40 00 00 02 BB 16
					15 00 00 40 00 00 02 BC 2C
					15 00 00 40 00 00 02 BD 16
					15 00 00 40 00 00 02 BE 2C
					15 00 00 40 00 00 02 BF 16
					15 00 00 40 00 00 02 C0 2C
					15 00 00 40 00 00 02 C1 16
					15 00 00 40 00 00 02 C2 2C
					15 00 00 40 00 00 02 C3 16
					15 00 00 40 00 00 02 C4 2C
					15 00 00 40 00 00 02 C5 16
					15 00 00 40 00 00 02 C6 2C
					15 00 00 40 00 00 02 C7 16
					15 00 00 40 00 00 02 C8 2C
					15 00 00 40 00 00 02 C9 16
					15 00 00 40 00 00 02 CA 2C
					15 00 00 40 00 00 02 CB 16
					15 00 00 40 00 00 02 CC 2C
					15 00 00 40 00 00 02 CD 2C
					15 00 00 40 00 00 02 CE 16
					15 00 00 40 00 00 02 CF 2C
					15 00 00 40 00 00 02 D0 16
					15 00 00 40 00 00 02 D1 2C
					15 00 00 40 00 00 02 D2 16
					15 00 00 40 00 00 02 D3 2C
					15 00 00 40 00 00 02 D4 16
					15 00 00 40 00 00 02 D5 2C
					15 00 00 40 00 00 02 D6 16
					15 00 00 40 00 00 02 D7 2C
					15 00 00 40 00 00 02 D8 16
					15 00 00 40 00 00 02 D9 2C
					15 00 00 40 00 00 02 DA 16
					15 00 00 40 00 00 02 DB 2C
					15 00 00 40 00 00 02 DC 16
					15 00 00 40 00 00 02 DD 2C
					15 00 00 40 00 00 02 DE 16
					15 00 00 40 00 00 02 DF 2C
					15 00 00 40 00 00 02 E0 16
					15 00 00 40 00 00 02 E1 2C
					15 00 00 40 00 00 02 E2 16
					15 00 00 40 00 00 02 E3 2C
					15 00 00 40 00 00 02 E4 16
					15 00 00 40 00 00 02 E5 2C
					15 00 00 40 00 00 02 E6 16
					15 00 00 40 00 00 02 E7 2C
					15 00 00 40 00 00 02 E8 16
					15 00 00 40 00 00 02 E9 2C
					15 00 00 40 00 00 02 EA 16
					15 00 00 40 00 00 02 EB 2C
					15 00 00 40 00 00 02 EC 16
					15 00 00 40 00 00 02 FE 6A
					15 00 00 40 00 00 02 4E 00
					15 00 00 40 00 00 02 4F 00
					15 00 00 40 00 00 02 50 00
					15 00 00 40 00 00 02 51 00
					15 00 00 40 00 00 02 52 00
					15 00 00 40 00 00 02 53 00
					15 00 00 40 00 00 02 54 00
					15 00 00 40 00 00 02 55 00
					15 00 00 40 00 00 02 56 00
					15 00 00 40 00 00 02 58 00
					15 00 00 40 00 00 02 59 00
					15 00 00 40 00 00 02 5A 00
					15 00 00 40 00 00 02 5B 00
					15 00 00 40 00 00 02 5C 00
					15 00 00 40 00 00 02 5D 00
					15 00 00 40 00 00 02 5E 00
					15 00 00 40 00 00 02 FE 44
					15 00 00 40 00 00 02 78 3F
					15 00 00 40 00 00 02 79 E0
					15 00 00 40 00 00 02 66 00
					15 00 00 40 00 00 02 67 00
					15 00 00 40 00 00 02 FE 72
					15 00 00 40 00 00 02 F3 60
					15 00 00 40 00 00 02 33 01
					15 00 00 40 00 00 02 FE 98
					15 00 00 40 00 00 02 02 04
					15 00 00 00 00 00 02 03 EC
					//err flag setting
					15 00 00 40 00 00 02 FE D4
					15 00 00 40 00 00 02 40 03
					15 00 00 40 00 00 02 42 00
					15 00 00 40 00 00 02 FE 47
					15 00 00 40 00 00 02 80 26
					15 00 00 40 00 00 02 83 00
					15 00 00 40 00 00 02 FE 40
					15 00 00 40 00 00 02 DE A8
					15 00 00 40 00 00 02 FE A0
					15 00 00 40 00 00 02 06 04
					15 00 00 40 00 00 02 7C 15
					15 00 00 40 00 00 02 FE 42
					15 00 00 40 00 00 02 17 02
					15 00 00 40 00 00 02 FE A1
					15 00 00 40 00 00 02 74 72
					15 00 00 40 00 00 02 C3 FF
					15 00 00 40 00 00 02 C4 FF
					15 00 00 00 00 00 02 C5 7F
					// IC write
					15 00 00 40 00 00 02 FE 40
					15 00 00 40 00 00 02 92 70
					15 00 00 40 00 00 02 93 81
					15 00 00 40 00 00 02 FE 98
					15 00 00 40 00 00 02 7D 10
					15 00 00 40 00 00 02 C4 88
					15 00 00 40 00 00 02 C6 03
					15 00 00 40 00 00 02 C7 8F
					15 00 00 40 00 00 02 FE A1
					15 00 00 00 00 00 02 58 67
					// timing switch
					15 00 00 40 00 00 02 FE 00
					15 00 00 40 00 00 02 8A 15 // idle 120 - 1
					15 00 00 40 00 00 02 FE 98
					15 00 00 40 00 00 02 E3 08
					15 00 00 40 00 00 02 CB 01
					15 00 00 40 00 00 02 FE 44
					15 00 00 40 00 00 02 77 E8
					// vsync out for Psensor
					15 00 00 40 00 00 02 FE D0
					15 00 00 40 00 00 02 1C 09
					15 00 00 40 00 00 02 FE 98
					15 00 00 40 00 00 02 E0 07
					15 00 00 40 00 00 02 E1 07
					15 00 00 40 00 00 02 E2 07
					15 00 00 40 00 00 02 FE 61
					15 00 00 40 00 00 02 48 11
					15 00 00 40 00 00 02 FE 62
					15 00 00 40 00 00 02 48 8D
					15 00 00 40 00 00 02 49 00
					15 00 00 40 00 00 02 4A 00
					15 00 00 40 00 00 02 4B 14
					15 00 00 40 00 00 02 4C 40
					15 00 00 40 00 00 02 4D 00
					15 00 00 40 00 00 02 4E 01
					15 00 00 00 00 00 02 4F 01
					// PPS lock
					15 00 00 00 00 00 02 FE FD
					15 00 00 00 00 00 02 90 01
					// PSCAN_CK1
					15 00 00 40 00 00 02 FE 62
					15 00 00 00 00 00 02 00 C7
					// Sleep Out
					15 00 00 00 00 00 02 FE 00
					05 00 00 00 78 00 01 11
					05 00 00 00 00 00 01 29
				];
				qcom,mdss-dsi-on-command-state = "dsi_hs_mode";
			};
			timing@wqhd_auto_60_to_1hz_index_7 {
				#include "dsi-panel-p2-42-06-0a-sec-dsc-cmd-common.dtsi"
				cell-index = <7>;
				qcom,mdss-dsi-panel-framerate = <60>;
				/* ---------------------------- */
				/* | 15 - 14 | 13 - 7 | 6 - 0 | */
				/* ---------------------------- */
				/* |   mode  | sf fps | min fps| */
				/* ---------------------------- -*/
				/* mode: 1 idle, 2 auto, 3 qsync */
				/*   2 << 14 | 60 << 7 | 1     */
				qcom,mdss-dsi-h-sync-skew = <40449>;
				/* mode: 0 normal, 1 idle, 2 auto, 3 qsync, 4 diff, 5 test */
				mi,mdss-dsi-ddic-mode = "auto";
				mi,mdss-dsi-sf-framerate = <60>;
				mi,mdss-dsi-ddic-min-framerate = <1>;
				qcom,mdss-dsi-timing-switch-command = [
					15 00 00 40 00 00 02 F1 A6
					15 00 00 40 00 00 02 FE 00
					15 00 00 40 00 00 02 8A 18 // auto 60 - 1
					15 00 00 40 00 00 02 FE 98
					15 00 00 40 00 00 02 E3 08
					15 00 00 40 00 00 02 CB 02
					15 00 00 40 00 00 02 FE 44
					15 00 00 40 00 00 02 77 E8
					15 00 00 40 00 00 02 81 03
					15 00 00 40 00 00 02 82 0B
					15 00 00 40 00 00 02 83 0B
					15 00 00 40 00 00 02 FE 00
					15 00 00 00 00 00 02 FB AA
				];
				qcom,mdss-dsi-timing-switch-command-state = "dsi_hs_mode";
				qcom,mdss-dsi-on-command = [
					/* round corner */
					15 00 00 40 00 00 02 FE 27
					15 00 00 40 00 00 02 BF 01
					15 00 00 40 00 00 02 F6 01
					15 00 00 40 00 00 02 FE 27
					15 00 00 40 00 00 02 0F F2
					15 00 00 40 00 00 02 13 2C
					15 00 00 40 00 00 02 19 86
					15 00 00 40 00 00 02 1A 14
					15 00 00 40 00 00 02 1B 40
					15 00 00 40 00 00 02 26 63
					15 00 00 40 00 00 02 27 63
					15 00 00 40 00 00 02 29 64
					15 00 00 40 00 00 02 2A 78
					15 00 00 40 00 00 02 2F 00
					15 00 00 40 00 00 02 30 6F
					15 00 00 40 00 00 02 31 95
					15 00 00 40 00 00 02 32 00
					15 00 00 40 00 00 02 33 96
					15 00 00 40 00 00 02 34 78
					15 00 00 40 00 00 02 35 00
					15 00 00 40 00 00 02 36 04
					15 00 00 40 00 00 02 37 07
					15 00 00 40 00 00 02 38 95
					15 00 00 40 00 00 02 39 6F
					15 00 00 40 00 00 02 3A 00
					15 00 00 40 00 00 02 3B 96
					15 00 00 40 00 00 02 3F 78
					15 00 00 40 00 00 02 40 00
					15 00 00 40 00 00 02 41 04
					15 00 00 40 00 00 02 42 07
					15 00 00 40 00 00 02 77 86
					15 00 00 40 00 00 02 78 A0
					15 00 00 40 00 00 02 80 64
					15 00 00 40 00 00 02 81 64
					15 00 00 40 00 00 02 83 63
					15 00 00 40 00 00 02 90 86
					15 00 00 40 00 00 02 91 A0
					15 00 00 40 00 00 02 B6 00
					15 00 00 40 00 00 02 B7 44
					15 00 00 40 00 00 02 C1 24
					15 00 00 40 00 00 02 C3 24
					15 00 00 40 00 00 02 FE 28
					15 00 00 40 00 00 02 37 18
					15 00 00 40 00 00 02 58 18
					15 00 00 40 00 00 02 FE 90
					15 00 00 40 00 00 02 08 00
					15 00 00 00 00 00 02 09 00
					/* init code */
					15 00 00 40 00 00 02 FE D2
					15 00 00 40 00 00 02 97 00
					15 00 00 40 00 00 02 FE 00
					15 00 00 40 00 00 02 FA 01
					15 00 00 40 00 00 02 FE 00
					15 00 00 40 00 00 02 2F 04
					15 00 00 40 00 00 02 8A 10
					15 00 00 40 00 00 02 FE 00
					39 00 00 40 00 00 05 2A 00 00 02 53
					39 00 00 40 00 00 05 2B 00 00 03 CF
					15 00 00 40 00 00 02 35 00
					39 00 00 00 00 00 03 51 00 00
					/* frame skip */
					15 00 00 40 00 00 02 FE 44
					15 00 00 40 00 00 02 00 88
					15 00 00 40 00 00 02 AA 00
					15 00 00 40 00 00 02 01 08
					15 00 00 40 00 00 02 02 01
					15 00 00 40 00 00 02 03 01
					15 00 00 40 00 00 02 04 32
					15 00 00 40 00 00 02 05 01
					15 00 00 40 00 00 02 06 00
					15 00 00 40 00 00 02 07 00
					15 00 00 40 00 00 02 08 00
					15 00 00 40 00 00 02 09 00
					15 00 00 40 00 00 02 0A 00
					15 00 00 40 00 00 02 0B 00
					15 00 00 40 00 00 02 0C 00
					15 00 00 40 00 00 02 0D 11
					15 00 00 40 00 00 02 0E 11
					15 00 00 40 00 00 02 0F 11
					15 00 00 40 00 00 02 10 11
					15 00 00 40 00 00 02 15 01
					15 00 00 40 00 00 02 16 03
					15 00 00 40 00 00 02 17 00
					15 00 00 40 00 00 02 18 00
					15 00 00 40 00 00 02 19 00
					15 00 00 40 00 00 02 1A 00
					15 00 00 40 00 00 02 1B 00
					15 00 00 40 00 00 02 1C 00
					15 00 00 40 00 00 02 1D 11
					15 00 00 40 00 00 02 1E 11
					15 00 00 40 00 00 02 1F 11
					15 00 00 40 00 00 02 20 11
					15 00 00 40 00 00 02 25 01
					15 00 00 40 00 00 02 26 03
					15 00 00 40 00 00 02 27 0B
					15 00 00 40 00 00 02 28 0B
					15 00 00 40 00 00 02 29 00
					15 00 00 40 00 00 02 2A 00
					15 00 00 40 00 00 02 2B 00
					15 00 00 40 00 00 02 2D 00
					15 00 00 40 00 00 02 2F 11
					15 00 00 40 00 00 02 30 FF
					15 00 00 40 00 00 02 31 11
					15 00 00 40 00 00 02 32 11
					15 00 00 40 00 00 02 37 01
					15 00 00 40 00 00 02 38 03
					15 00 00 40 00 00 02 39 04
					15 00 00 40 00 00 02 3A 00
					15 00 00 40 00 00 02 3B 00
					15 00 00 40 00 00 02 3D 00
					15 00 00 40 00 00 02 3F 00
					15 00 00 40 00 00 02 40 00
					15 00 00 40 00 00 02 41 11
					15 00 00 40 00 00 02 42 11
					15 00 00 40 00 00 02 43 11
					15 00 00 40 00 00 02 44 11
					15 00 00 40 00 00 02 69 00
					15 00 00 40 00 00 02 6A 00
					15 00 00 40 00 00 02 6B 00
					15 00 00 40 00 00 02 6C 00
					15 00 00 40 00 00 02 6D 00
					15 00 00 40 00 00 02 6E 00
					15 00 00 40 00 00 02 6F 00
					15 00 00 40 00 00 02 70 00
					15 00 00 40 00 00 02 80 42
					15 00 00 40 00 00 02 81 03
					15 00 00 40 00 00 02 82 0B
					15 00 00 40 00 00 02 83 0B
					15 00 00 40 00 00 02 84 00
					15 00 00 40 00 00 02 85 00
					15 00 00 40 00 00 02 86 00
					15 00 00 40 00 00 02 87 00
					15 00 00 40 00 00 02 88 00
					15 00 00 40 00 00 02 89 00
					15 00 00 40 00 00 02 8A 00
					15 00 00 40 00 00 02 8B 1F
					15 00 00 40 00 00 02 8C F1
					15 00 00 40 00 00 02 8D 11
					15 00 00 40 00 00 02 8E 11
					15 00 00 40 00 00 02 49 00
					15 00 00 40 00 00 02 4A 00
					15 00 00 40 00 00 02 4B 04
					15 00 00 40 00 00 02 4C 00
					15 00 00 40 00 00 02 4D 00
					15 00 00 40 00 00 02 4E 01
					15 00 00 40 00 00 02 4F 03
					15 00 00 40 00 00 02 50 04
					15 00 00 40 00 00 02 51 0B
					15 00 00 40 00 00 02 52 77
					15 00 00 40 00 00 02 53 EF
					15 00 00 40 00 00 02 54 77
					15 00 00 40 00 00 02 55 77
					15 00 00 40 00 00 02 56 0B
					15 00 00 40 00 00 02 58 59
					15 00 00 40 00 00 02 59 00
					15 00 00 40 00 00 02 5A 00
					15 00 00 40 00 00 02 5B 00
					15 00 00 40 00 00 02 5C 00
					15 00 00 40 00 00 02 5D 00
					15 00 00 40 00 00 02 98 00
					15 00 00 40 00 00 02 99 00
					15 00 00 40 00 00 02 9A 00
					15 00 00 40 00 00 02 9B 00
					15 00 00 40 00 00 02 9C 00
					15 00 00 40 00 00 02 9D 00
					15 00 00 40 00 00 02 9E 00
					15 00 00 40 00 00 02 9F 00
					15 00 00 40 00 00 02 A0 00
					15 00 00 40 00 00 02 A2 00
					15 00 00 40 00 00 02 A3 00
					15 00 00 40 00 00 02 A4 00
					15 00 00 40 00 00 02 A5 00
					15 00 00 40 00 00 02 A6 00
					15 00 00 40 00 00 02 A7 00
					15 00 00 40 00 00 02 A9 00
					15 00 00 40 00 00 02 5E 00
					15 00 00 40 00 00 02 5F 01
					15 00 00 40 00 00 02 60 12
					15 00 00 40 00 00 02 61 32
					15 00 00 40 00 00 02 62 44
					15 00 00 40 00 00 02 63 40
					15 00 00 40 00 00 02 64 00
					15 00 00 40 00 00 02 65 00
					15 00 00 40 00 00 02 76 C0
					15 00 00 40 00 00 02 77 E8
					15 00 00 40 00 00 02 FE 43
					15 00 00 40 00 00 02 64 1B
					15 00 00 40 00 00 02 63 05
					15 00 00 40 00 00 02 66 06
					15 00 00 40 00 00 02 67 22
					15 00 00 40 00 00 02 68 22
					15 00 00 40 00 00 02 69 B3
					15 00 00 40 00 00 02 6A 33
					15 00 00 40 00 00 02 6B 0B
					15 00 00 40 00 00 02 6C 16
					15 00 00 40 00 00 02 6D 21
					15 00 00 40 00 00 02 6F 37
					15 00 00 40 00 00 02 70 42
					15 00 00 40 00 00 02 71 4D
					15 00 00 40 00 00 02 72 58
					15 00 00 40 00 00 02 73 0B
					15 00 00 40 00 00 02 74 16
					15 00 00 40 00 00 02 75 21
					15 00 00 40 00 00 02 76 2C
					15 00 00 40 00 00 02 77 37
					15 00 00 40 00 00 02 78 42
					15 00 00 40 00 00 02 79 4D
					15 00 00 40 00 00 02 7A 58
					15 00 00 40 00 00 02 7B 0B
					15 00 00 40 00 00 02 7C 16
					15 00 00 40 00 00 02 7D 21
					15 00 00 40 00 00 02 7E 2C
					15 00 00 40 00 00 02 7F 37
					15 00 00 40 00 00 02 80 42
					15 00 00 40 00 00 02 81 4D
					15 00 00 40 00 00 02 82 58
					15 00 00 40 00 00 02 83 0B
					15 00 00 40 00 00 02 84 16
					15 00 00 40 00 00 02 85 21
					15 00 00 40 00 00 02 86 2C
					15 00 00 40 00 00 02 87 37
					15 00 00 40 00 00 02 88 42
					15 00 00 40 00 00 02 89 4D
					15 00 00 40 00 00 02 8A 58
					15 00 00 40 00 00 02 8B 58
					15 00 00 40 00 00 02 8C 4D
					15 00 00 40 00 00 02 8D 42
					15 00 00 40 00 00 02 8E 37
					15 00 00 40 00 00 02 8F 2C
					15 00 00 40 00 00 02 90 21
					15 00 00 40 00 00 02 91 16
					15 00 00 40 00 00 02 92 0B
					15 00 00 40 00 00 02 93 58
					15 00 00 40 00 00 02 94 4D
					15 00 00 40 00 00 02 95 42
					15 00 00 40 00 00 02 96 37
					15 00 00 40 00 00 02 97 2C
					15 00 00 40 00 00 02 98 21
					15 00 00 40 00 00 02 99 16
					15 00 00 40 00 00 02 9A 0B
					15 00 00 40 00 00 02 9B 58
					15 00 00 40 00 00 02 9C 4D
					15 00 00 40 00 00 02 9D 42
					15 00 00 40 00 00 02 9E 37
					15 00 00 40 00 00 02 9F 2C
					15 00 00 40 00 00 02 A0 21
					15 00 00 40 00 00 02 A2 16
					15 00 00 40 00 00 02 A3 0B
					15 00 00 40 00 00 02 A4 58
					15 00 00 40 00 00 02 A5 4D
					15 00 00 40 00 00 02 A6 42
					15 00 00 40 00 00 02 A7 37
					15 00 00 40 00 00 02 A9 2C
					15 00 00 40 00 00 02 AA 21
					15 00 00 40 00 00 02 AB 16
					15 00 00 40 00 00 02 AC 0B
					15 00 00 40 00 00 02 AD 16
					15 00 00 40 00 00 02 AE 2C
					15 00 00 40 00 00 02 AF 16
					15 00 00 40 00 00 02 B0 2C
					15 00 00 40 00 00 02 B1 16
					15 00 00 40 00 00 02 B2 2C
					15 00 00 40 00 00 02 B3 16
					15 00 00 40 00 00 02 B4 2C
					15 00 00 40 00 00 02 B5 16
					15 00 00 40 00 00 02 B6 2C
					15 00 00 40 00 00 02 B7 16
					15 00 00 40 00 00 02 B8 2C
					15 00 00 40 00 00 02 B9 16
					15 00 00 40 00 00 02 BA 2C
					15 00 00 40 00 00 02 BB 16
					15 00 00 40 00 00 02 BC 2C
					15 00 00 40 00 00 02 BD 16
					15 00 00 40 00 00 02 BE 2C
					15 00 00 40 00 00 02 BF 16
					15 00 00 40 00 00 02 C0 2C
					15 00 00 40 00 00 02 C1 16
					15 00 00 40 00 00 02 C2 2C
					15 00 00 40 00 00 02 C3 16
					15 00 00 40 00 00 02 C4 2C
					15 00 00 40 00 00 02 C5 16
					15 00 00 40 00 00 02 C6 2C
					15 00 00 40 00 00 02 C7 16
					15 00 00 40 00 00 02 C8 2C
					15 00 00 40 00 00 02 C9 16
					15 00 00 40 00 00 02 CA 2C
					15 00 00 40 00 00 02 CB 16
					15 00 00 40 00 00 02 CC 2C
					15 00 00 40 00 00 02 CD 2C
					15 00 00 40 00 00 02 CE 16
					15 00 00 40 00 00 02 CF 2C
					15 00 00 40 00 00 02 D0 16
					15 00 00 40 00 00 02 D1 2C
					15 00 00 40 00 00 02 D2 16
					15 00 00 40 00 00 02 D3 2C
					15 00 00 40 00 00 02 D4 16
					15 00 00 40 00 00 02 D5 2C
					15 00 00 40 00 00 02 D6 16
					15 00 00 40 00 00 02 D7 2C
					15 00 00 40 00 00 02 D8 16
					15 00 00 40 00 00 02 D9 2C
					15 00 00 40 00 00 02 DA 16
					15 00 00 40 00 00 02 DB 2C
					15 00 00 40 00 00 02 DC 16
					15 00 00 40 00 00 02 DD 2C
					15 00 00 40 00 00 02 DE 16
					15 00 00 40 00 00 02 DF 2C
					15 00 00 40 00 00 02 E0 16
					15 00 00 40 00 00 02 E1 2C
					15 00 00 40 00 00 02 E2 16
					15 00 00 40 00 00 02 E3 2C
					15 00 00 40 00 00 02 E4 16
					15 00 00 40 00 00 02 E5 2C
					15 00 00 40 00 00 02 E6 16
					15 00 00 40 00 00 02 E7 2C
					15 00 00 40 00 00 02 E8 16
					15 00 00 40 00 00 02 E9 2C
					15 00 00 40 00 00 02 EA 16
					15 00 00 40 00 00 02 EB 2C
					15 00 00 40 00 00 02 EC 16
					15 00 00 40 00 00 02 FE 6A
					15 00 00 40 00 00 02 4E 00
					15 00 00 40 00 00 02 4F 00
					15 00 00 40 00 00 02 50 00
					15 00 00 40 00 00 02 51 00
					15 00 00 40 00 00 02 52 00
					15 00 00 40 00 00 02 53 00
					15 00 00 40 00 00 02 54 00
					15 00 00 40 00 00 02 55 00
					15 00 00 40 00 00 02 56 00
					15 00 00 40 00 00 02 58 00
					15 00 00 40 00 00 02 59 00
					15 00 00 40 00 00 02 5A 00
					15 00 00 40 00 00 02 5B 00
					15 00 00 40 00 00 02 5C 00
					15 00 00 40 00 00 02 5D 00
					15 00 00 40 00 00 02 5E 00
					15 00 00 40 00 00 02 FE 44
					15 00 00 40 00 00 02 78 3F
					15 00 00 40 00 00 02 79 E0
					15 00 00 40 00 00 02 66 00
					15 00 00 40 00 00 02 67 00
					15 00 00 40 00 00 02 FE 72
					15 00 00 40 00 00 02 F3 60
					15 00 00 40 00 00 02 33 01
					15 00 00 40 00 00 02 FE 98
					15 00 00 40 00 00 02 02 04
					15 00 00 00 00 00 02 03 EC
					//err flag setting
					15 00 00 40 00 00 02 FE D4
					15 00 00 40 00 00 02 40 03
					15 00 00 40 00 00 02 42 00
					15 00 00 40 00 00 02 FE 47
					15 00 00 40 00 00 02 80 26
					15 00 00 40 00 00 02 83 00
					15 00 00 40 00 00 02 FE 40
					15 00 00 40 00 00 02 DE A8
					15 00 00 40 00 00 02 FE A0
					15 00 00 40 00 00 02 06 04
					15 00 00 40 00 00 02 7C 15
					15 00 00 40 00 00 02 FE 42
					15 00 00 40 00 00 02 17 02
					15 00 00 40 00 00 02 FE A1
					15 00 00 40 00 00 02 74 72
					15 00 00 40 00 00 02 C3 FF
					15 00 00 40 00 00 02 C4 FF
					15 00 00 00 00 00 02 C5 7F
					// IC write
					15 00 00 40 00 00 02 FE 40
					15 00 00 40 00 00 02 92 70
					15 00 00 40 00 00 02 93 81
					15 00 00 40 00 00 02 FE 98
					15 00 00 40 00 00 02 7D 10
					15 00 00 40 00 00 02 C4 88
					15 00 00 40 00 00 02 C6 03
					15 00 00 40 00 00 02 C7 8F
					15 00 00 40 00 00 02 FE A1
					15 00 00 00 00 00 02 58 67
					// timing switch
					15 00 00 40 00 00 02 FE 00
					15 00 00 40 00 00 02 8A 18 // auto 60 - 1
					15 00 00 40 00 00 02 FE 98
					15 00 00 40 00 00 02 E3 08
					15 00 00 40 00 00 02 CB 02
					15 00 00 40 00 00 02 FE 44
					15 00 00 40 00 00 02 77 E8
					15 00 00 40 00 00 02 81 03
					15 00 00 40 00 00 02 82 0B
					15 00 00 40 00 00 02 83 0B
					// vsync out for Psensor
					15 00 00 40 00 00 02 FE D0
					15 00 00 40 00 00 02 1C 09
					15 00 00 40 00 00 02 FE 98
					15 00 00 40 00 00 02 E0 07
					15 00 00 40 00 00 02 E1 07
					15 00 00 40 00 00 02 E2 07
					15 00 00 40 00 00 02 FE 61
					15 00 00 40 00 00 02 48 11
					15 00 00 40 00 00 02 FE 62
					15 00 00 40 00 00 02 48 8D
					15 00 00 40 00 00 02 49 00
					15 00 00 40 00 00 02 4A 00
					15 00 00 40 00 00 02 4B 14
					15 00 00 40 00 00 02 4C 40
					15 00 00 40 00 00 02 4D 00
					15 00 00 40 00 00 02 4E 01
					15 00 00 00 00 00 02 4F 01
					// PPS lock
					15 00 00 00 00 00 02 FE FD
					15 00 00 00 00 00 02 90 01
					// PSCAN_CK1
					15 00 00 40 00 00 02 FE 62
					15 00 00 00 00 00 02 00 C7
					// Sleep Out
					15 00 00 00 00 00 02 FE 00
					05 00 00 00 78 00 01 11
					05 00 00 00 00 00 01 29
				];
				qcom,mdss-dsi-on-command-state = "dsi_hs_mode";
			};
			timing@wqhd_auto_120_to_1hz_index_8 {
				#include "dsi-panel-p2-42-06-0a-sec-dsc-cmd-common.dtsi"
				cell-index = <8>;
				qcom,mdss-dsi-panel-framerate = <120>;
				/* ---------------------------- */
				/* | 15 - 14 | 13 - 7 | 6 - 0 | */
				/* ---------------------------- */
				/* |   mode  | sf fps | min fps| */
				/* ---------------------------- -*/
				/* mode: 1 idle, 2 auto, 3 qsync */
				/*   2 << 14 | 120 << 7 | 1     */
				qcom,mdss-dsi-h-sync-skew = <48127>;
				/* mode: 0 normal, 1 idle, 2 auto, 3 qsync, 4 diff, 5 test */
				mi,mdss-dsi-ddic-mode = "auto";
				mi,mdss-dsi-sf-framerate = <120>;
				mi,mdss-dsi-ddic-min-framerate = <1>;
				qcom,mdss-dsi-timing-switch-command = [
					15 00 00 40 00 00 02 F1 A6
					15 00 00 40 00 00 02 FE 00
					15 00 00 40 00 00 02 8A 17 // auto 120 - 1
					15 00 00 40 00 00 02 FE 98
					15 00 00 40 00 00 02 E3 08
					15 00 00 40 00 00 02 CB 01
					15 00 00 40 00 00 02 FE 44
					15 00 00 40 00 00 02 77 E8
					15 00 00 40 00 00 02 FE 00
					15 00 00 00 00 00 02 FB AA
				];
				qcom,mdss-dsi-timing-switch-command-state = "dsi_hs_mode";
				qcom,mdss-dsi-on-command = [
					/* round corner */
					15 00 00 40 00 00 02 FE 27
					15 00 00 40 00 00 02 BF 01
					15 00 00 40 00 00 02 F6 01
					15 00 00 40 00 00 02 FE 27
					15 00 00 40 00 00 02 0F F2
					15 00 00 40 00 00 02 13 2C
					15 00 00 40 00 00 02 19 86
					15 00 00 40 00 00 02 1A 14
					15 00 00 40 00 00 02 1B 40
					15 00 00 40 00 00 02 26 63
					15 00 00 40 00 00 02 27 63
					15 00 00 40 00 00 02 29 64
					15 00 00 40 00 00 02 2A 78
					15 00 00 40 00 00 02 2F 00
					15 00 00 40 00 00 02 30 6F
					15 00 00 40 00 00 02 31 95
					15 00 00 40 00 00 02 32 00
					15 00 00 40 00 00 02 33 96
					15 00 00 40 00 00 02 34 78
					15 00 00 40 00 00 02 35 00
					15 00 00 40 00 00 02 36 04
					15 00 00 40 00 00 02 37 07
					15 00 00 40 00 00 02 38 95
					15 00 00 40 00 00 02 39 6F
					15 00 00 40 00 00 02 3A 00
					15 00 00 40 00 00 02 3B 96
					15 00 00 40 00 00 02 3F 78
					15 00 00 40 00 00 02 40 00
					15 00 00 40 00 00 02 41 04
					15 00 00 40 00 00 02 42 07
					15 00 00 40 00 00 02 77 86
					15 00 00 40 00 00 02 78 A0
					15 00 00 40 00 00 02 80 64
					15 00 00 40 00 00 02 81 64
					15 00 00 40 00 00 02 83 63
					15 00 00 40 00 00 02 90 86
					15 00 00 40 00 00 02 91 A0
					15 00 00 40 00 00 02 B6 00
					15 00 00 40 00 00 02 B7 44
					15 00 00 40 00 00 02 C1 24
					15 00 00 40 00 00 02 C3 24
					15 00 00 40 00 00 02 FE 28
					15 00 00 40 00 00 02 37 18
					15 00 00 40 00 00 02 58 18
					15 00 00 40 00 00 02 FE 90
					15 00 00 40 00 00 02 08 00
					15 00 00 00 00 00 02 09 00
					/* init code */
					15 00 00 40 00 00 02 FE D2
					15 00 00 40 00 00 02 97 00
					15 00 00 40 00 00 02 FE 00
					15 00 00 40 00 00 02 FA 01
					15 00 00 40 00 00 02 FE 00
					15 00 00 40 00 00 02 2F 04
					15 00 00 40 00 00 02 8A 10
					15 00 00 40 00 00 02 FE 00
					39 00 00 40 00 00 05 2A 00 00 02 53
					39 00 00 40 00 00 05 2B 00 00 03 CF
					15 00 00 40 00 00 02 35 00
					39 00 00 00 00 00 03 51 00 00
					/* frame skip */
					15 00 00 40 00 00 02 FE 44
					15 00 00 40 00 00 02 00 88
					15 00 00 40 00 00 02 AA 00
					15 00 00 40 00 00 02 01 08
					15 00 00 40 00 00 02 02 01
					15 00 00 40 00 00 02 03 01
					15 00 00 40 00 00 02 04 32
					15 00 00 40 00 00 02 05 01
					15 00 00 40 00 00 02 06 00
					15 00 00 40 00 00 02 07 00
					15 00 00 40 00 00 02 08 00
					15 00 00 40 00 00 02 09 00
					15 00 00 40 00 00 02 0A 00
					15 00 00 40 00 00 02 0B 00
					15 00 00 40 00 00 02 0C 00
					15 00 00 40 00 00 02 0D 11
					15 00 00 40 00 00 02 0E 11
					15 00 00 40 00 00 02 0F 11
					15 00 00 40 00 00 02 10 11
					15 00 00 40 00 00 02 15 01
					15 00 00 40 00 00 02 16 03
					15 00 00 40 00 00 02 17 00
					15 00 00 40 00 00 02 18 00
					15 00 00 40 00 00 02 19 00
					15 00 00 40 00 00 02 1A 00
					15 00 00 40 00 00 02 1B 00
					15 00 00 40 00 00 02 1C 00
					15 00 00 40 00 00 02 1D 11
					15 00 00 40 00 00 02 1E 11
					15 00 00 40 00 00 02 1F 11
					15 00 00 40 00 00 02 20 11
					15 00 00 40 00 00 02 25 01
					15 00 00 40 00 00 02 26 03
					15 00 00 40 00 00 02 27 0B
					15 00 00 40 00 00 02 28 0B
					15 00 00 40 00 00 02 29 00
					15 00 00 40 00 00 02 2A 00
					15 00 00 40 00 00 02 2B 00
					15 00 00 40 00 00 02 2D 00
					15 00 00 40 00 00 02 2F 11
					15 00 00 40 00 00 02 30 FF
					15 00 00 40 00 00 02 31 11
					15 00 00 40 00 00 02 32 11
					15 00 00 40 00 00 02 37 01
					15 00 00 40 00 00 02 38 03
					15 00 00 40 00 00 02 39 04
					15 00 00 40 00 00 02 3A 00
					15 00 00 40 00 00 02 3B 00
					15 00 00 40 00 00 02 3D 00
					15 00 00 40 00 00 02 3F 00
					15 00 00 40 00 00 02 40 00
					15 00 00 40 00 00 02 41 11
					15 00 00 40 00 00 02 42 11
					15 00 00 40 00 00 02 43 11
					15 00 00 40 00 00 02 44 11
					15 00 00 40 00 00 02 69 00
					15 00 00 40 00 00 02 6A 00
					15 00 00 40 00 00 02 6B 00
					15 00 00 40 00 00 02 6C 00
					15 00 00 40 00 00 02 6D 00
					15 00 00 40 00 00 02 6E 00
					15 00 00 40 00 00 02 6F 00
					15 00 00 40 00 00 02 70 00
					15 00 00 40 00 00 02 80 42
					15 00 00 40 00 00 02 81 03
					15 00 00 40 00 00 02 82 0B
					15 00 00 40 00 00 02 83 0B
					15 00 00 40 00 00 02 84 00
					15 00 00 40 00 00 02 85 00
					15 00 00 40 00 00 02 86 00
					15 00 00 40 00 00 02 87 00
					15 00 00 40 00 00 02 88 00
					15 00 00 40 00 00 02 89 00
					15 00 00 40 00 00 02 8A 00
					15 00 00 40 00 00 02 8B 1F
					15 00 00 40 00 00 02 8C F1
					15 00 00 40 00 00 02 8D 11
					15 00 00 40 00 00 02 8E 11
					15 00 00 40 00 00 02 49 00
					15 00 00 40 00 00 02 4A 00
					15 00 00 40 00 00 02 4B 04
					15 00 00 40 00 00 02 4C 00
					15 00 00 40 00 00 02 4D 00
					15 00 00 40 00 00 02 4E 01
					15 00 00 40 00 00 02 4F 03
					15 00 00 40 00 00 02 50 04
					15 00 00 40 00 00 02 51 0B
					15 00 00 40 00 00 02 52 77
					15 00 00 40 00 00 02 53 EF
					15 00 00 40 00 00 02 54 77
					15 00 00 40 00 00 02 55 77
					15 00 00 40 00 00 02 56 0B
					15 00 00 40 00 00 02 58 59
					15 00 00 40 00 00 02 59 00
					15 00 00 40 00 00 02 5A 00
					15 00 00 40 00 00 02 5B 00
					15 00 00 40 00 00 02 5C 00
					15 00 00 40 00 00 02 5D 00
					15 00 00 40 00 00 02 98 00
					15 00 00 40 00 00 02 99 00
					15 00 00 40 00 00 02 9A 00
					15 00 00 40 00 00 02 9B 00
					15 00 00 40 00 00 02 9C 00
					15 00 00 40 00 00 02 9D 00
					15 00 00 40 00 00 02 9E 00
					15 00 00 40 00 00 02 9F 00
					15 00 00 40 00 00 02 A0 00
					15 00 00 40 00 00 02 A2 00
					15 00 00 40 00 00 02 A3 00
					15 00 00 40 00 00 02 A4 00
					15 00 00 40 00 00 02 A5 00
					15 00 00 40 00 00 02 A6 00
					15 00 00 40 00 00 02 A7 00
					15 00 00 40 00 00 02 A9 00
					15 00 00 40 00 00 02 5E 00
					15 00 00 40 00 00 02 5F 01
					15 00 00 40 00 00 02 60 12
					15 00 00 40 00 00 02 61 32
					15 00 00 40 00 00 02 62 44
					15 00 00 40 00 00 02 63 40
					15 00 00 40 00 00 02 64 00
					15 00 00 40 00 00 02 65 00
					15 00 00 40 00 00 02 76 C0
					15 00 00 40 00 00 02 77 E8
					15 00 00 40 00 00 02 FE 43
					15 00 00 40 00 00 02 64 1B
					15 00 00 40 00 00 02 63 05
					15 00 00 40 00 00 02 66 06
					15 00 00 40 00 00 02 67 22
					15 00 00 40 00 00 02 68 22
					15 00 00 40 00 00 02 69 B3
					15 00 00 40 00 00 02 6A 33
					15 00 00 40 00 00 02 6B 0B
					15 00 00 40 00 00 02 6C 16
					15 00 00 40 00 00 02 6D 21
					15 00 00 40 00 00 02 6F 37
					15 00 00 40 00 00 02 70 42
					15 00 00 40 00 00 02 71 4D
					15 00 00 40 00 00 02 72 58
					15 00 00 40 00 00 02 73 0B
					15 00 00 40 00 00 02 74 16
					15 00 00 40 00 00 02 75 21
					15 00 00 40 00 00 02 76 2C
					15 00 00 40 00 00 02 77 37
					15 00 00 40 00 00 02 78 42
					15 00 00 40 00 00 02 79 4D
					15 00 00 40 00 00 02 7A 58
					15 00 00 40 00 00 02 7B 0B
					15 00 00 40 00 00 02 7C 16
					15 00 00 40 00 00 02 7D 21
					15 00 00 40 00 00 02 7E 2C
					15 00 00 40 00 00 02 7F 37
					15 00 00 40 00 00 02 80 42
					15 00 00 40 00 00 02 81 4D
					15 00 00 40 00 00 02 82 58
					15 00 00 40 00 00 02 83 0B
					15 00 00 40 00 00 02 84 16
					15 00 00 40 00 00 02 85 21
					15 00 00 40 00 00 02 86 2C
					15 00 00 40 00 00 02 87 37
					15 00 00 40 00 00 02 88 42
					15 00 00 40 00 00 02 89 4D
					15 00 00 40 00 00 02 8A 58
					15 00 00 40 00 00 02 8B 58
					15 00 00 40 00 00 02 8C 4D
					15 00 00 40 00 00 02 8D 42
					15 00 00 40 00 00 02 8E 37
					15 00 00 40 00 00 02 8F 2C
					15 00 00 40 00 00 02 90 21
					15 00 00 40 00 00 02 91 16
					15 00 00 40 00 00 02 92 0B
					15 00 00 40 00 00 02 93 58
					15 00 00 40 00 00 02 94 4D
					15 00 00 40 00 00 02 95 42
					15 00 00 40 00 00 02 96 37
					15 00 00 40 00 00 02 97 2C
					15 00 00 40 00 00 02 98 21
					15 00 00 40 00 00 02 99 16
					15 00 00 40 00 00 02 9A 0B
					15 00 00 40 00 00 02 9B 58
					15 00 00 40 00 00 02 9C 4D
					15 00 00 40 00 00 02 9D 42
					15 00 00 40 00 00 02 9E 37
					15 00 00 40 00 00 02 9F 2C
					15 00 00 40 00 00 02 A0 21
					15 00 00 40 00 00 02 A2 16
					15 00 00 40 00 00 02 A3 0B
					15 00 00 40 00 00 02 A4 58
					15 00 00 40 00 00 02 A5 4D
					15 00 00 40 00 00 02 A6 42
					15 00 00 40 00 00 02 A7 37
					15 00 00 40 00 00 02 A9 2C
					15 00 00 40 00 00 02 AA 21
					15 00 00 40 00 00 02 AB 16
					15 00 00 40 00 00 02 AC 0B
					15 00 00 40 00 00 02 AD 16
					15 00 00 40 00 00 02 AE 2C
					15 00 00 40 00 00 02 AF 16
					15 00 00 40 00 00 02 B0 2C
					15 00 00 40 00 00 02 B1 16
					15 00 00 40 00 00 02 B2 2C
					15 00 00 40 00 00 02 B3 16
					15 00 00 40 00 00 02 B4 2C
					15 00 00 40 00 00 02 B5 16
					15 00 00 40 00 00 02 B6 2C
					15 00 00 40 00 00 02 B7 16
					15 00 00 40 00 00 02 B8 2C
					15 00 00 40 00 00 02 B9 16
					15 00 00 40 00 00 02 BA 2C
					15 00 00 40 00 00 02 BB 16
					15 00 00 40 00 00 02 BC 2C
					15 00 00 40 00 00 02 BD 16
					15 00 00 40 00 00 02 BE 2C
					15 00 00 40 00 00 02 BF 16
					15 00 00 40 00 00 02 C0 2C
					15 00 00 40 00 00 02 C1 16
					15 00 00 40 00 00 02 C2 2C
					15 00 00 40 00 00 02 C3 16
					15 00 00 40 00 00 02 C4 2C
					15 00 00 40 00 00 02 C5 16
					15 00 00 40 00 00 02 C6 2C
					15 00 00 40 00 00 02 C7 16
					15 00 00 40 00 00 02 C8 2C
					15 00 00 40 00 00 02 C9 16
					15 00 00 40 00 00 02 CA 2C
					15 00 00 40 00 00 02 CB 16
					15 00 00 40 00 00 02 CC 2C
					15 00 00 40 00 00 02 CD 2C
					15 00 00 40 00 00 02 CE 16
					15 00 00 40 00 00 02 CF 2C
					15 00 00 40 00 00 02 D0 16
					15 00 00 40 00 00 02 D1 2C
					15 00 00 40 00 00 02 D2 16
					15 00 00 40 00 00 02 D3 2C
					15 00 00 40 00 00 02 D4 16
					15 00 00 40 00 00 02 D5 2C
					15 00 00 40 00 00 02 D6 16
					15 00 00 40 00 00 02 D7 2C
					15 00 00 40 00 00 02 D8 16
					15 00 00 40 00 00 02 D9 2C
					15 00 00 40 00 00 02 DA 16
					15 00 00 40 00 00 02 DB 2C
					15 00 00 40 00 00 02 DC 16
					15 00 00 40 00 00 02 DD 2C
					15 00 00 40 00 00 02 DE 16
					15 00 00 40 00 00 02 DF 2C
					15 00 00 40 00 00 02 E0 16
					15 00 00 40 00 00 02 E1 2C
					15 00 00 40 00 00 02 E2 16
					15 00 00 40 00 00 02 E3 2C
					15 00 00 40 00 00 02 E4 16
					15 00 00 40 00 00 02 E5 2C
					15 00 00 40 00 00 02 E6 16
					15 00 00 40 00 00 02 E7 2C
					15 00 00 40 00 00 02 E8 16
					15 00 00 40 00 00 02 E9 2C
					15 00 00 40 00 00 02 EA 16
					15 00 00 40 00 00 02 EB 2C
					15 00 00 40 00 00 02 EC 16
					15 00 00 40 00 00 02 FE 6A
					15 00 00 40 00 00 02 4E 00
					15 00 00 40 00 00 02 4F 00
					15 00 00 40 00 00 02 50 00
					15 00 00 40 00 00 02 51 00
					15 00 00 40 00 00 02 52 00
					15 00 00 40 00 00 02 53 00
					15 00 00 40 00 00 02 54 00
					15 00 00 40 00 00 02 55 00
					15 00 00 40 00 00 02 56 00
					15 00 00 40 00 00 02 58 00
					15 00 00 40 00 00 02 59 00
					15 00 00 40 00 00 02 5A 00
					15 00 00 40 00 00 02 5B 00
					15 00 00 40 00 00 02 5C 00
					15 00 00 40 00 00 02 5D 00
					15 00 00 40 00 00 02 5E 00
					15 00 00 40 00 00 02 FE 44
					15 00 00 40 00 00 02 78 3F
					15 00 00 40 00 00 02 79 E0
					15 00 00 40 00 00 02 66 00
					15 00 00 40 00 00 02 67 00
					15 00 00 40 00 00 02 FE 72
					15 00 00 40 00 00 02 F3 60
					15 00 00 40 00 00 02 33 01
					15 00 00 40 00 00 02 FE 98
					15 00 00 40 00 00 02 02 04
					15 00 00 00 00 00 02 03 EC
					//err flag setting
					15 00 00 40 00 00 02 FE D4
					15 00 00 40 00 00 02 40 03
					15 00 00 40 00 00 02 42 00
					15 00 00 40 00 00 02 FE 47
					15 00 00 40 00 00 02 80 26
					15 00 00 40 00 00 02 83 00
					15 00 00 40 00 00 02 FE 40
					15 00 00 40 00 00 02 DE A8
					15 00 00 40 00 00 02 FE A0
					15 00 00 40 00 00 02 06 04
					15 00 00 40 00 00 02 7C 15
					15 00 00 40 00 00 02 FE 42
					15 00 00 40 00 00 02 17 02
					15 00 00 40 00 00 02 FE A1
					15 00 00 40 00 00 02 74 72
					15 00 00 40 00 00 02 C3 FF
					15 00 00 40 00 00 02 C4 FF
					15 00 00 00 00 00 02 C5 7F
					// IC write
					15 00 00 40 00 00 02 FE 40
					15 00 00 40 00 00 02 92 70
					15 00 00 40 00 00 02 93 81
					15 00 00 40 00 00 02 FE 98
					15 00 00 40 00 00 02 7D 10
					15 00 00 40 00 00 02 C4 88
					15 00 00 40 00 00 02 C6 03
					15 00 00 40 00 00 02 C7 8F
					15 00 00 40 00 00 02 FE A1
					15 00 00 00 00 00 02 58 67
					// timing switch
					15 00 00 40 00 00 02 FE 00
					15 00 00 40 00 00 02 8A 17 // auto 120 - 1
					15 00 00 40 00 00 02 FE 98
					15 00 00 40 00 00 02 E3 08
					15 00 00 40 00 00 02 CB 01
					15 00 00 40 00 00 02 FE 44
					15 00 00 40 00 00 02 77 E8
					// vsync out for Psensor
					15 00 00 40 00 00 02 FE D0
					15 00 00 40 00 00 02 1C 09
					15 00 00 40 00 00 02 FE 98
					15 00 00 40 00 00 02 E0 07
					15 00 00 40 00 00 02 E1 07
					15 00 00 40 00 00 02 E2 07
					15 00 00 40 00 00 02 FE 61
					15 00 00 40 00 00 02 48 11
					15 00 00 40 00 00 02 FE 62
					15 00 00 40 00 00 02 48 8D
					15 00 00 40 00 00 02 49 00
					15 00 00 40 00 00 02 4A 00
					15 00 00 40 00 00 02 4B 14
					15 00 00 40 00 00 02 4C 40
					15 00 00 40 00 00 02 4D 00
					15 00 00 40 00 00 02 4E 01
					15 00 00 00 00 00 02 4F 01
					// PPS lock
					15 00 00 00 00 00 02 FE FD
					15 00 00 00 00 00 02 90 01
					// PSCAN_CK1
					15 00 00 40 00 00 02 FE 62
					15 00 00 00 00 00 02 00 C7
					// Sleep Out
					15 00 00 00 00 00 02 FE 00
					05 00 00 00 78 00 01 11
					05 00 00 00 00 00 01 29
				];
				qcom,mdss-dsi-on-command-state = "dsi_hs_mode";
			};
			timing@wqhd_qsync_120_to_10hz_index_9 {
				#include "dsi-panel-p2-42-06-0a-sec-dsc-cmd-common.dtsi"
				cell-index = <9>;
				qcom,mdss-dsi-panel-framerate = <120>;
				/* ---------------------------- */
				/* | 15 - 14 | 13 - 7 | 6 - 0 | */
				/* ---------------------------- */
				/* |   mode  | sf fps | min fps| */
				/* ---------------------------- -*/
				/* mode: 1 idle, 2 auto, 3 qsync */
				/*   3 << 14 | 120 << 7 | 10     */
				qcom,mdss-dsi-h-sync-skew = <64522>;
				/* mode: 0 normal, 1 idle, 2 auto, 3 qsync, 4 diff, 5 test */
				mi,mdss-dsi-ddic-mode = "qsync";
				mi,mdss-dsi-sf-framerate = <120>;
				mi,mdss-dsi-ddic-min-framerate = <10>;
				qcom,mdss-dsi-timing-switch-command = [
					15 00 00 40 00 00 02 F1 A6
					15 00 00 40 00 00 02 FE 00
					15 00 00 40 00 00 02 8A 19 // qsync 120 - 10
					15 00 00 40 00 00 02 FE 98
					15 00 00 40 00 00 02 E3 04
					15 00 00 40 00 00 02 CB 01
					15 00 00 40 00 00 02 FE 44
					15 00 00 40 00 00 02 77 68
					15 00 00 40 00 00 02 FE 00
					15 00 00 00 00 00 02 FB AA
				];
				qcom,mdss-dsi-timing-switch-command-state = "dsi_hs_mode";
				qcom,mdss-dsi-on-command = [
					/* round corner */
					15 00 00 40 00 00 02 FE 27
					15 00 00 40 00 00 02 BF 01
					15 00 00 40 00 00 02 F6 01
					15 00 00 40 00 00 02 FE 27
					15 00 00 40 00 00 02 0F F2
					15 00 00 40 00 00 02 13 2C
					15 00 00 40 00 00 02 19 86
					15 00 00 40 00 00 02 1A 14
					15 00 00 40 00 00 02 1B 40
					15 00 00 40 00 00 02 26 63
					15 00 00 40 00 00 02 27 63
					15 00 00 40 00 00 02 29 64
					15 00 00 40 00 00 02 2A 78
					15 00 00 40 00 00 02 2F 00
					15 00 00 40 00 00 02 30 6F
					15 00 00 40 00 00 02 31 95
					15 00 00 40 00 00 02 32 00
					15 00 00 40 00 00 02 33 96
					15 00 00 40 00 00 02 34 78
					15 00 00 40 00 00 02 35 00
					15 00 00 40 00 00 02 36 04
					15 00 00 40 00 00 02 37 07
					15 00 00 40 00 00 02 38 95
					15 00 00 40 00 00 02 39 6F
					15 00 00 40 00 00 02 3A 00
					15 00 00 40 00 00 02 3B 96
					15 00 00 40 00 00 02 3F 78
					15 00 00 40 00 00 02 40 00
					15 00 00 40 00 00 02 41 04
					15 00 00 40 00 00 02 42 07
					15 00 00 40 00 00 02 77 86
					15 00 00 40 00 00 02 78 A0
					15 00 00 40 00 00 02 80 64
					15 00 00 40 00 00 02 81 64
					15 00 00 40 00 00 02 83 63
					15 00 00 40 00 00 02 90 86
					15 00 00 40 00 00 02 91 A0
					15 00 00 40 00 00 02 B6 00
					15 00 00 40 00 00 02 B7 44
					15 00 00 40 00 00 02 C1 24
					15 00 00 40 00 00 02 C3 24
					15 00 00 40 00 00 02 FE 28
					15 00 00 40 00 00 02 37 18
					15 00 00 40 00 00 02 58 18
					15 00 00 40 00 00 02 FE 90
					15 00 00 40 00 00 02 08 00
					15 00 00 00 00 00 02 09 00
					/* init code */
					15 00 00 40 00 00 02 FE D2
					15 00 00 40 00 00 02 97 00
					15 00 00 40 00 00 02 FE 00
					15 00 00 40 00 00 02 FA 01
					15 00 00 40 00 00 02 FE 00
					15 00 00 40 00 00 02 2F 04
					15 00 00 40 00 00 02 8A 10
					15 00 00 40 00 00 02 FE 00
					39 00 00 40 00 00 05 2A 00 00 02 53
					39 00 00 40 00 00 05 2B 00 00 03 CF
					15 00 00 40 00 00 02 35 00
					39 00 00 00 00 00 03 51 00 00
					/* frame skip */
					15 00 00 40 00 00 02 FE 44
					15 00 00 40 00 00 02 00 88
					15 00 00 40 00 00 02 AA 00
					15 00 00 40 00 00 02 01 08
					15 00 00 40 00 00 02 02 01
					15 00 00 40 00 00 02 03 01
					15 00 00 40 00 00 02 04 32
					15 00 00 40 00 00 02 05 01
					15 00 00 40 00 00 02 06 00
					15 00 00 40 00 00 02 07 00
					15 00 00 40 00 00 02 08 00
					15 00 00 40 00 00 02 09 00
					15 00 00 40 00 00 02 0A 00
					15 00 00 40 00 00 02 0B 00
					15 00 00 40 00 00 02 0C 00
					15 00 00 40 00 00 02 0D 11
					15 00 00 40 00 00 02 0E 11
					15 00 00 40 00 00 02 0F 11
					15 00 00 40 00 00 02 10 11
					15 00 00 40 00 00 02 15 01
					15 00 00 40 00 00 02 16 03
					15 00 00 40 00 00 02 17 00
					15 00 00 40 00 00 02 18 00
					15 00 00 40 00 00 02 19 00
					15 00 00 40 00 00 02 1A 00
					15 00 00 40 00 00 02 1B 00
					15 00 00 40 00 00 02 1C 00
					15 00 00 40 00 00 02 1D 11
					15 00 00 40 00 00 02 1E 11
					15 00 00 40 00 00 02 1F 11
					15 00 00 40 00 00 02 20 11
					15 00 00 40 00 00 02 25 01
					15 00 00 40 00 00 02 26 03
					15 00 00 40 00 00 02 27 0B
					15 00 00 40 00 00 02 28 0B
					15 00 00 40 00 00 02 29 00
					15 00 00 40 00 00 02 2A 00
					15 00 00 40 00 00 02 2B 00
					15 00 00 40 00 00 02 2D 00
					15 00 00 40 00 00 02 2F 11
					15 00 00 40 00 00 02 30 FF
					15 00 00 40 00 00 02 31 11
					15 00 00 40 00 00 02 32 11
					15 00 00 40 00 00 02 37 01
					15 00 00 40 00 00 02 38 03
					15 00 00 40 00 00 02 39 04
					15 00 00 40 00 00 02 3A 00
					15 00 00 40 00 00 02 3B 00
					15 00 00 40 00 00 02 3D 00
					15 00 00 40 00 00 02 3F 00
					15 00 00 40 00 00 02 40 00
					15 00 00 40 00 00 02 41 11
					15 00 00 40 00 00 02 42 11
					15 00 00 40 00 00 02 43 11
					15 00 00 40 00 00 02 44 11
					15 00 00 40 00 00 02 69 00
					15 00 00 40 00 00 02 6A 00
					15 00 00 40 00 00 02 6B 00
					15 00 00 40 00 00 02 6C 00
					15 00 00 40 00 00 02 6D 00
					15 00 00 40 00 00 02 6E 00
					15 00 00 40 00 00 02 6F 00
					15 00 00 40 00 00 02 70 00
					15 00 00 40 00 00 02 80 42
					15 00 00 40 00 00 02 81 03
					15 00 00 40 00 00 02 82 0B
					15 00 00 40 00 00 02 83 0B
					15 00 00 40 00 00 02 84 00
					15 00 00 40 00 00 02 85 00
					15 00 00 40 00 00 02 86 00
					15 00 00 40 00 00 02 87 00
					15 00 00 40 00 00 02 88 00
					15 00 00 40 00 00 02 89 00
					15 00 00 40 00 00 02 8A 00
					15 00 00 40 00 00 02 8B 1F
					15 00 00 40 00 00 02 8C F1
					15 00 00 40 00 00 02 8D 11
					15 00 00 40 00 00 02 8E 11
					15 00 00 40 00 00 02 49 00
					15 00 00 40 00 00 02 4A 00
					15 00 00 40 00 00 02 4B 04
					15 00 00 40 00 00 02 4C 00
					15 00 00 40 00 00 02 4D 00
					15 00 00 40 00 00 02 4E 01
					15 00 00 40 00 00 02 4F 03
					15 00 00 40 00 00 02 50 04
					15 00 00 40 00 00 02 51 0B
					15 00 00 40 00 00 02 52 77
					15 00 00 40 00 00 02 53 EF
					15 00 00 40 00 00 02 54 77
					15 00 00 40 00 00 02 55 77
					15 00 00 40 00 00 02 56 0B
					15 00 00 40 00 00 02 58 59
					15 00 00 40 00 00 02 59 00
					15 00 00 40 00 00 02 5A 00
					15 00 00 40 00 00 02 5B 00
					15 00 00 40 00 00 02 5C 00
					15 00 00 40 00 00 02 5D 00
					15 00 00 40 00 00 02 98 00
					15 00 00 40 00 00 02 99 00
					15 00 00 40 00 00 02 9A 00
					15 00 00 40 00 00 02 9B 00
					15 00 00 40 00 00 02 9C 00
					15 00 00 40 00 00 02 9D 00
					15 00 00 40 00 00 02 9E 00
					15 00 00 40 00 00 02 9F 00
					15 00 00 40 00 00 02 A0 00
					15 00 00 40 00 00 02 A2 00
					15 00 00 40 00 00 02 A3 00
					15 00 00 40 00 00 02 A4 00
					15 00 00 40 00 00 02 A5 00
					15 00 00 40 00 00 02 A6 00
					15 00 00 40 00 00 02 A7 00
					15 00 00 40 00 00 02 A9 00
					15 00 00 40 00 00 02 5E 00
					15 00 00 40 00 00 02 5F 01
					15 00 00 40 00 00 02 60 12
					15 00 00 40 00 00 02 61 32
					15 00 00 40 00 00 02 62 44
					15 00 00 40 00 00 02 63 40
					15 00 00 40 00 00 02 64 00
					15 00 00 40 00 00 02 65 00
					15 00 00 40 00 00 02 76 C0
					15 00 00 40 00 00 02 77 E8
					15 00 00 40 00 00 02 FE 43
					15 00 00 40 00 00 02 64 1B
					15 00 00 40 00 00 02 63 05
					15 00 00 40 00 00 02 66 06
					15 00 00 40 00 00 02 67 22
					15 00 00 40 00 00 02 68 22
					15 00 00 40 00 00 02 69 B3
					15 00 00 40 00 00 02 6A 33
					15 00 00 40 00 00 02 6B 0B
					15 00 00 40 00 00 02 6C 16
					15 00 00 40 00 00 02 6D 21
					15 00 00 40 00 00 02 6F 37
					15 00 00 40 00 00 02 70 42
					15 00 00 40 00 00 02 71 4D
					15 00 00 40 00 00 02 72 58
					15 00 00 40 00 00 02 73 0B
					15 00 00 40 00 00 02 74 16
					15 00 00 40 00 00 02 75 21
					15 00 00 40 00 00 02 76 2C
					15 00 00 40 00 00 02 77 37
					15 00 00 40 00 00 02 78 42
					15 00 00 40 00 00 02 79 4D
					15 00 00 40 00 00 02 7A 58
					15 00 00 40 00 00 02 7B 0B
					15 00 00 40 00 00 02 7C 16
					15 00 00 40 00 00 02 7D 21
					15 00 00 40 00 00 02 7E 2C
					15 00 00 40 00 00 02 7F 37
					15 00 00 40 00 00 02 80 42
					15 00 00 40 00 00 02 81 4D
					15 00 00 40 00 00 02 82 58
					15 00 00 40 00 00 02 83 0B
					15 00 00 40 00 00 02 84 16
					15 00 00 40 00 00 02 85 21
					15 00 00 40 00 00 02 86 2C
					15 00 00 40 00 00 02 87 37
					15 00 00 40 00 00 02 88 42
					15 00 00 40 00 00 02 89 4D
					15 00 00 40 00 00 02 8A 58
					15 00 00 40 00 00 02 8B 58
					15 00 00 40 00 00 02 8C 4D
					15 00 00 40 00 00 02 8D 42
					15 00 00 40 00 00 02 8E 37
					15 00 00 40 00 00 02 8F 2C
					15 00 00 40 00 00 02 90 21
					15 00 00 40 00 00 02 91 16
					15 00 00 40 00 00 02 92 0B
					15 00 00 40 00 00 02 93 58
					15 00 00 40 00 00 02 94 4D
					15 00 00 40 00 00 02 95 42
					15 00 00 40 00 00 02 96 37
					15 00 00 40 00 00 02 97 2C
					15 00 00 40 00 00 02 98 21
					15 00 00 40 00 00 02 99 16
					15 00 00 40 00 00 02 9A 0B
					15 00 00 40 00 00 02 9B 58
					15 00 00 40 00 00 02 9C 4D
					15 00 00 40 00 00 02 9D 42
					15 00 00 40 00 00 02 9E 37
					15 00 00 40 00 00 02 9F 2C
					15 00 00 40 00 00 02 A0 21
					15 00 00 40 00 00 02 A2 16
					15 00 00 40 00 00 02 A3 0B
					15 00 00 40 00 00 02 A4 58
					15 00 00 40 00 00 02 A5 4D
					15 00 00 40 00 00 02 A6 42
					15 00 00 40 00 00 02 A7 37
					15 00 00 40 00 00 02 A9 2C
					15 00 00 40 00 00 02 AA 21
					15 00 00 40 00 00 02 AB 16
					15 00 00 40 00 00 02 AC 0B
					15 00 00 40 00 00 02 AD 16
					15 00 00 40 00 00 02 AE 2C
					15 00 00 40 00 00 02 AF 16
					15 00 00 40 00 00 02 B0 2C
					15 00 00 40 00 00 02 B1 16
					15 00 00 40 00 00 02 B2 2C
					15 00 00 40 00 00 02 B3 16
					15 00 00 40 00 00 02 B4 2C
					15 00 00 40 00 00 02 B5 16
					15 00 00 40 00 00 02 B6 2C
					15 00 00 40 00 00 02 B7 16
					15 00 00 40 00 00 02 B8 2C
					15 00 00 40 00 00 02 B9 16
					15 00 00 40 00 00 02 BA 2C
					15 00 00 40 00 00 02 BB 16
					15 00 00 40 00 00 02 BC 2C
					15 00 00 40 00 00 02 BD 16
					15 00 00 40 00 00 02 BE 2C
					15 00 00 40 00 00 02 BF 16
					15 00 00 40 00 00 02 C0 2C
					15 00 00 40 00 00 02 C1 16
					15 00 00 40 00 00 02 C2 2C
					15 00 00 40 00 00 02 C3 16
					15 00 00 40 00 00 02 C4 2C
					15 00 00 40 00 00 02 C5 16
					15 00 00 40 00 00 02 C6 2C
					15 00 00 40 00 00 02 C7 16
					15 00 00 40 00 00 02 C8 2C
					15 00 00 40 00 00 02 C9 16
					15 00 00 40 00 00 02 CA 2C
					15 00 00 40 00 00 02 CB 16
					15 00 00 40 00 00 02 CC 2C
					15 00 00 40 00 00 02 CD 2C
					15 00 00 40 00 00 02 CE 16
					15 00 00 40 00 00 02 CF 2C
					15 00 00 40 00 00 02 D0 16
					15 00 00 40 00 00 02 D1 2C
					15 00 00 40 00 00 02 D2 16
					15 00 00 40 00 00 02 D3 2C
					15 00 00 40 00 00 02 D4 16
					15 00 00 40 00 00 02 D5 2C
					15 00 00 40 00 00 02 D6 16
					15 00 00 40 00 00 02 D7 2C
					15 00 00 40 00 00 02 D8 16
					15 00 00 40 00 00 02 D9 2C
					15 00 00 40 00 00 02 DA 16
					15 00 00 40 00 00 02 DB 2C
					15 00 00 40 00 00 02 DC 16
					15 00 00 40 00 00 02 DD 2C
					15 00 00 40 00 00 02 DE 16
					15 00 00 40 00 00 02 DF 2C
					15 00 00 40 00 00 02 E0 16
					15 00 00 40 00 00 02 E1 2C
					15 00 00 40 00 00 02 E2 16
					15 00 00 40 00 00 02 E3 2C
					15 00 00 40 00 00 02 E4 16
					15 00 00 40 00 00 02 E5 2C
					15 00 00 40 00 00 02 E6 16
					15 00 00 40 00 00 02 E7 2C
					15 00 00 40 00 00 02 E8 16
					15 00 00 40 00 00 02 E9 2C
					15 00 00 40 00 00 02 EA 16
					15 00 00 40 00 00 02 EB 2C
					15 00 00 40 00 00 02 EC 16
					15 00 00 40 00 00 02 FE 6A
					15 00 00 40 00 00 02 4E 00
					15 00 00 40 00 00 02 4F 00
					15 00 00 40 00 00 02 50 00
					15 00 00 40 00 00 02 51 00
					15 00 00 40 00 00 02 52 00
					15 00 00 40 00 00 02 53 00
					15 00 00 40 00 00 02 54 00
					15 00 00 40 00 00 02 55 00
					15 00 00 40 00 00 02 56 00
					15 00 00 40 00 00 02 58 00
					15 00 00 40 00 00 02 59 00
					15 00 00 40 00 00 02 5A 00
					15 00 00 40 00 00 02 5B 00
					15 00 00 40 00 00 02 5C 00
					15 00 00 40 00 00 02 5D 00
					15 00 00 40 00 00 02 5E 00
					15 00 00 40 00 00 02 FE 44
					15 00 00 40 00 00 02 78 3F
					15 00 00 40 00 00 02 79 E0
					15 00 00 40 00 00 02 66 00
					15 00 00 40 00 00 02 67 00
					15 00 00 40 00 00 02 FE 72
					15 00 00 40 00 00 02 F3 60
					15 00 00 40 00 00 02 33 01
					15 00 00 40 00 00 02 FE 98
					15 00 00 40 00 00 02 02 04
					15 00 00 00 00 00 02 03 EC
					//err flag setting
					15 00 00 40 00 00 02 FE D4
					15 00 00 40 00 00 02 40 03
					15 00 00 40 00 00 02 42 00
					15 00 00 40 00 00 02 FE 47
					15 00 00 40 00 00 02 80 26
					15 00 00 40 00 00 02 83 00
					15 00 00 40 00 00 02 FE 40
					15 00 00 40 00 00 02 DE A8
					15 00 00 40 00 00 02 FE A0
					15 00 00 40 00 00 02 06 04
					15 00 00 40 00 00 02 7C 15
					15 00 00 40 00 00 02 FE 42
					15 00 00 40 00 00 02 17 02
					15 00 00 40 00 00 02 FE A1
					15 00 00 40 00 00 02 74 72
					15 00 00 40 00 00 02 C3 FF
					15 00 00 40 00 00 02 C4 FF
					15 00 00 00 00 00 02 C5 7F
					// IC write
					15 00 00 40 00 00 02 FE 40
					15 00 00 40 00 00 02 92 70
					15 00 00 40 00 00 02 93 81
					15 00 00 40 00 00 02 FE 98
					15 00 00 40 00 00 02 7D 10
					15 00 00 40 00 00 02 C4 88
					15 00 00 40 00 00 02 C6 03
					15 00 00 40 00 00 02 C7 8F
					15 00 00 40 00 00 02 FE A1
					15 00 00 00 00 00 02 58 67
					// timing switch
					15 00 00 40 00 00 02 FE 00
					15 00 00 40 00 00 02 8A 19 // qsync 120 - 10
					15 00 00 40 00 00 02 FE 98
					15 00 00 40 00 00 02 E3 04
					15 00 00 40 00 00 02 CB 01
					15 00 00 40 00 00 02 FE 44
					15 00 00 40 00 00 02 77 68
					// vsync out for Psensor
					15 00 00 40 00 00 02 FE D0
					15 00 00 40 00 00 02 1C 09
					15 00 00 40 00 00 02 FE 98
					15 00 00 40 00 00 02 E0 07
					15 00 00 40 00 00 02 E1 07
					15 00 00 40 00 00 02 E2 07
					15 00 00 40 00 00 02 FE 61
					15 00 00 40 00 00 02 48 11
					15 00 00 40 00 00 02 FE 62
					15 00 00 40 00 00 02 48 8D
					15 00 00 40 00 00 02 49 00
					15 00 00 40 00 00 02 4A 00
					15 00 00 40 00 00 02 4B 14
					15 00 00 40 00 00 02 4C 40
					15 00 00 40 00 00 02 4D 00
					15 00 00 40 00 00 02 4E 01
					15 00 00 00 00 00 02 4F 01
					// PPS lock
					15 00 00 00 00 00 02 FE FD
					15 00 00 00 00 00 02 90 01
					// PSCAN_CK1
					15 00 00 40 00 00 02 FE 62
					15 00 00 00 00 00 02 00 C7
					// Sleep Out
					15 00 00 00 00 00 02 FE 00
					05 00 00 00 78 00 01 11
					05 00 00 00 00 00 01 29
				];
				qcom,mdss-dsi-on-command-state = "dsi_hs_mode";
			};
		};
	};
};

&dsi_p2_42_06_0a_sec_dsc_cmd {
	qcom,panel-sec-supply-entries = <&dsi_panel_pwr_supply_p2_sec>;
	qcom,mdss-dsi-sec-bl-pmic-control-type = "bl_ctrl_dcs";
	qcom,mdss-dsi-bl-min-level = <15>;
	qcom,mdss-dsi-bl-max-level = <4095>;
	qcom,bl-dsc-cmd-state = "dsi_hs_mode";
	qcom,mdss-brightness-max-level = <4095>;
	qcom,mdss-brightness-init-level = <281>;
	qcom,platform-sec-reset-gpio = <&tlmm 30 0>;
	qcom,platform-sec-pmic-reset-gpio = <&tlmm 173 0>;

	mi,panel-id = <0x00005032 0x5342060A>;
	mi,panel-on-dimming-delay = <120>;

	/* IRQF_ONESHOT | IRQF_TRIGGER_HEIGH */
	mi,esd-err-irq-gpio = <&tlmm 55 0x2004>;
	mi,esd-err-irq-gpio-flag = <0x2004>;

	mi,mdss-dsi-panel-wp-read-command = [06 01 00 00 00 00 01 0D];
	mi,mdss-dsi-panel-wp-read-command-state = "dsi_hs_mode";
	mi,mdss-dsi-panel-wp-read-pre-tx-command = [39 00 00 00 00 00 02 FE C6];
	mi,mdss-dsi-panel-wp-read-pre-tx-command-state = "dsi_hs_mode";
	mi,mdss-dsi-panel-wp-read-length = <8>;

	mi,mdss-dsi-panel-cell-id-read-command = [06 01 00 00 00 00 01 00];
	mi,mdss-dsi-panel-cell-id-read-pre-tx-command = [39 00 00 00 00 00 02 FE C6];
	mi,mdss-dsi-panel-cell-id-read-pre-tx-command-state = "dsi_hs_mode";
	mi,mdss-dsi-panel-cell-id-read-command-state = "dsi_hs_mode";
	mi,mdss-dsi-panel-cell-id-read-length = <13>;

	mi,mdss-dsi-fac-bl-max-level = <2047>;
	mi,mdss-fac-brightness-max-level = <2047>;
	mi,max-brightness-normal = <1535>;

	mi,flatmode-status-check-enabled;
	mi,mdss-dsi-panel-flatmode-status-command = [
			06 01 00 01 00 00 01 5F
	];
	mi,mdss-dsi-panel-flatmode-status-command-state = "dsi_hs_mode";
	mi,mdss-dsi-panel-flatmode-status-read-length = <1>;
	mi,mdss-dsi-panel-flatmode-on-status-value = <0x00>;

	mi,doze-hbm-dbv-level = <412>;
	mi,doze-lbm-dbv-level = <35>;
	mi,ddic-round-corner-enabled;

	mi,panel-build-id-read-needed;
	mi,panel-build-id-read-length = <1>;
	mi,mdss-dsi-panel-build-id-read-command = [06 01 00 01 00 00 01 DA];
	mi,mdss-dsi-panel-build-id-read-command-state = "dsi_hs_mode";

	qcom,dsi-select-sec-clocks = "pll_byte_clk1", "pll_dsi_clk1";
	qcom,mdss-dsi-clk-strength = <0x88>;
};
